VERSION ""

NS_ :

BS_:

BU_: BMS ECC EVBUS_Virtual_ECU GW OBC VCU

BO_ 1328 ICC_0x530: 8 GW
 SG_ ICC_DrvrTSet : 7|8@0+ (0.5,0) [0|127.5] "Degree Celsius"  ECC
 SG_ ICC_PassTSet : 15|8@0+ (0.5,0) [0|127.5] "Degree Celsius"  ECC
 SG_ ICC_VSPVoiceTypSwt : 17|1@0+ (1,0) [0|1] ""  EVBUS_Virtual_ECU
 SG_ ICC_ECCAUTOReq : 19|1@0+ (1,0) [0|1] ""  ECC
 SG_ ICC_DrvrSYNCReq : 20|1@0+ (1,0) [0|1] ""  ECC
 SG_ ICC_ACSwtReq : 21|1@0+ (1,0) [0|1] ""  ECC
 SG_ ICC_AirVolSet : 27|4@0+ (1,0) [0|15] ""  ECC
 SG_ ICC_ECCIntExtCircReq : 28|1@0+ (1,0) [0|1] ""  ECC
 SG_ ICC_AirClnSwtReq : 29|1@0+ (1,0) [0|1] ""  ECC
 SG_ ICC_MaxFrntDefrstSet : 30|1@0+ (1,0) [0|1] ""  ECC
 SG_ ICC_VSPCtrlCmd : 31|1@0+ (1,0) [0|1] ""  EVBUS_Virtual_ECU
 SG_ ICC_NavCtryCod : 39|8@0+ (1,0) [0|255] ""  EVBUS_Virtual_ECU
 SG_ ICC_NavRoadTyp : 43|4@0+ (1,0) [0|15] ""  EVBUS_Virtual_ECU
 SG_ ICC_NavSpdLimUnit : 45|2@0+ (1,0) [0|3] ""  EVBUS_Virtual_ECU
 SG_ ICC_NavSpdLimSts : 47|2@0+ (1,0) [0|3] ""  EVBUS_Virtual_ECU
 SG_ ICC_NavSpdLim : 53|6@0+ (1,0) [0|63] ""  EVBUS_Virtual_ECU
 SG_ ICC_BlowWinBtn : 55|1@0+ (1,0) [0|1] ""  ECC
 SG_ ICC_NavSpdLimExitDst : 63|8@0+ (10,0) [0|2550] "m"  EVBUS_Virtual_ECU

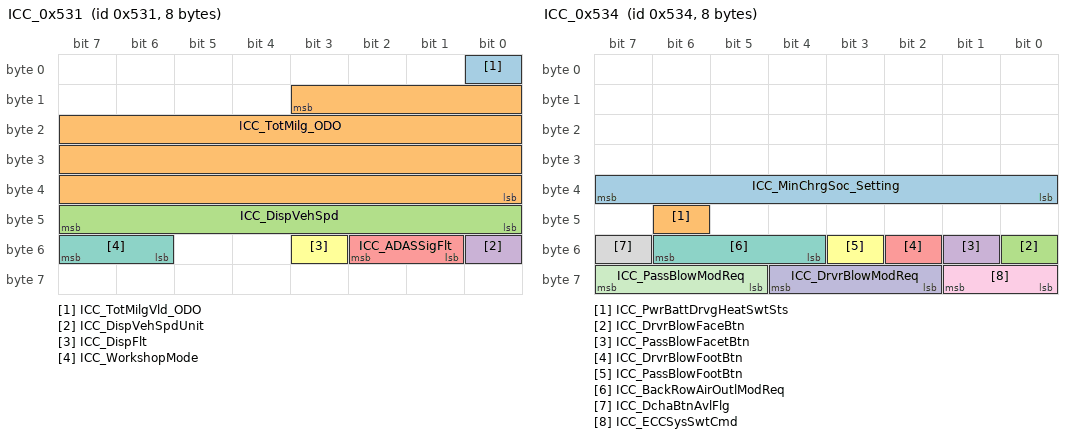
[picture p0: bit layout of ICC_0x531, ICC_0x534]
BO_ 1329 ICC_0x531: 8 GW
 SG_ ICC_TotMilgVld_ODO : 0|1@0+ (1,0) [0|1] ""  BMS,ECC,OBC,VCU
 SG_ ICC_TotMilg_ODO : 11|28@0+ (0.01,0) [0|2000000] "km"  BMS,ECC,OBC,VCU
 SG_ ICC_DispVehSpd : 47|8@0+ (1,0) [0|255] ""  ECC,VCU
 SG_ ICC_DispVehSpdUnit : 48|1@0+ (1,0) [0|1] ""  ECC,VCU
 SG_ ICC_ADASSigFlt : 50|2@0+ (1,0) [0|3] ""  ECC
 SG_ ICC_DispFlt : 51|1@0+ (1,0) [0|1] ""  ECC,VCU
 SG_ ICC_WorkshopMode : 55|2@0+ (1,0) [0|3] ""  ECC,VCU

BO_ 1332 ICC_0x534: 8 GW
 SG_ ICC_MinChrgSoc_Setting : 39|8@0+ (1,0) [0|255] "%"  VCU
 SG_ ICC_PwrBattDrvgHeatSwtSts : 46|1@0+ (1,0) [0|1] ""  ECC
 SG_ ICC_DrvrBlowFaceBtn : 48|1@0+ (1,0) [0|1] ""  ECC
 SG_ ICC_PassBlowFacetBtn : 49|1@0+ (1,0) [0|1] ""  ECC
 SG_ ICC_DrvrBlowFootBtn : 50|1@0+ (1,0) [0|1] ""  ECC
 SG_ ICC_PassBlowFootBtn : 51|1@0+ (1,0) [0|1] ""  ECC
 SG_ ICC_BackRowAirOutlModReq : 54|3@0+ (1,0) [0|7] ""  ECC
 SG_ ICC_DchaBtnAvlFlg : 55|1@0+ (1,0) [0|1] ""  VCU
 SG_ ICC_ECCSysSwtCmd : 57|2@0+ (1,0) [0|3] ""  ECC
 SG_ ICC_DrvrBlowModReq : 60|3@0+ (1,0) [0|7] ""  ECC
 SG_ ICC_PassBlowModReq : 63|3@0+ (1,0) [0|7] ""  ECC

BO_ 1360 OBC_0x550: 16 OBC
 SG_ OBC_0x550_CheckSum : 7|8@0+ (1,0) [0|255] ""  ECC,GW,VCU
 SG_ OBC_0x550_AliveCounter : 11|4@0+ (1,0) [0|14] ""  ECC,GW,VCU
 SG_ OBC_PDU_CrtSts : 12|1@0+ (1,0) [0|1] ""  GW,VCU
 SG_ OBC_Pwr : 15|3@0+ (1,0) [0|3] ""  GW,VCU
 SG_ OBC_OutpMaxPwr : 18|11@0+ (0.01,0) [0|20] "KW"  GW,VCU
 SG_ OBC_V2L_RdySts : 20|2@0+ (1,0) [0|3] ""  GW,VCU
 SG_ OBC_V2L_ActvStsFb : 22|2@0+ (1,0) [0|3] ""  GW,VCU
 SG_ OBC_T : 47|8@0+ (1,-48) [-48|207] "Degree Celsius"  ECC,GW,VCU
 SG_ OBC_CrtSts : 50|3@0+ (1,0) [0|7] ""  ECC,GW,VCU
 SG_ OBC_DCNegRlyAdhFlt : 51|1@0+ (1,0) [0|1] ""  GW,VCU
 SG_ OBC_DCPosRlyAdhFlt : 52|1@0+ (1,0) [0|1] ""  GW,VCU
 SG_ OBC_OperMod : 55|3@0+ (1,0) [0|3] ""  GW,VCU
 SG_ OBC_PwrSplyHLVIntlkFlt : 56|1@0+ (1,0) [0|1] ""  GW,VCU
 SG_ OBC_ACSCIntlkSigChkCircFlt : 57|1@0+ (1,0) [0|1] ""  GW,VCU
 SG_ OBC_DCFCIntlkSigChkCircFlt : 58|1@0+ (1,0) [0|1] ""  GW,VCU
 SG_ OBC_PTCIntlkSigChkCircFlt : 59|1@0+ (1,0) [0|1] ""  GW,VCU
 SG_ OBC_PwrBattIntlkSigChkCircFlt : 60|1@0+ (1,0) [0|1] ""  GW,VCU
 SG_ OBC_EASIntlkSigChkCircFlt : 61|1@0+ (1,0) [0|1] ""  GW,VCU
 SG_ OBC_OTARdy_Fb : 63|2@0+ (1,0) [0|3] ""  GW
 SG_ OBC_550_SSecOC_Fresh_Byte0 : 71|8@0+ (1,0) [0|255] ""  GW,VCU
 SG_ OBC_550_SSecOC_MAC_Byte0 : 79|8@0+ (1,0) [0|255] ""  GW,VCU
 SG_ OBC_550_SSecOC_MAC_Byte1 : 87|8@0+ (1,0) [0|255] ""  GW,VCU
 SG_ OBC_550_SSecOC_MAC_Byte2 : 95|8@0+ (1,0) [0|255] ""  GW,VCU

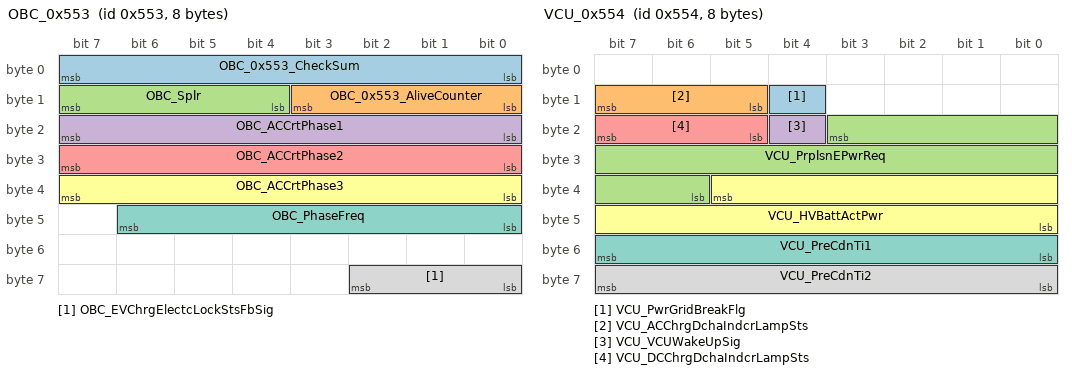
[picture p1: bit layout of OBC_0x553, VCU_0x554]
BO_ 1363 OBC_0x553: 8 OBC
 SG_ OBC_0x553_CheckSum : 7|8@0+ (1,0) [0|255] ""  GW,VCU
 SG_ OBC_0x553_AliveCounter : 11|4@0+ (1,0) [0|14] ""  GW,VCU
 SG_ OBC_Splr : 15|4@0+ (1,0) [0|15] ""  GW
 SG_ OBC_ACCrtPhase1 : 23|8@0+ (1,0) [0|255] "A"  GW,VCU
 SG_ OBC_ACCrtPhase2 : 31|8@0+ (1,0) [0|255] "A"  GW,VCU
 SG_ OBC_ACCrtPhase3 : 39|8@0+ (1,0) [0|255] "A"  GW,VCU
 SG_ OBC_PhaseFreq : 46|7@0+ (1,0) [0|63] "Hz"  GW,VCU
 SG_ OBC_EVChrgElectcLockStsFbSig : 58|3@0+ (1,0) [0|7] ""  GW,VCU

BO_ 1364 VCU_0x554: 8 VCU
 SG_ VCU_PwrGridBreakFlg : 12|1@0+ (1,0) [0|1] ""  GW
 SG_ VCU_ACChrgDchaIndcrLampSts : 15|3@0+ (1,0) [0|7] ""  GW
 SG_ VCU_PrplsnEPwrReq : 19|14@0+ (0.1,-600) [-600|600] "KW"  GW
 SG_ VCU_VCUWakeUpSig : 20|1@0+ (1,0) [0|1] ""  GW
 SG_ VCU_DCChrgDchaIndcrLampSts : 23|3@0+ (1,0) [0|7] ""  GW
 SG_ VCU_HVBattActPwr : 37|14@0+ (0.1,-600) [-600|600] "KW"  GW
 SG_ VCU_PreCdnTi1 : 55|8@0+ (1,0) [0|255] "min"  GW
 SG_ VCU_PreCdnTi2 : 63|8@0+ (1,0) [0|255] "min"  GW

BO_ 1365 VCU_0x555: 8 VCU
 SG_ VCU_DCChrgElectcLockDrvFlt : 1|2@0+ (1,0) [0|3] ""  GW
 SG_ VCU_ACDCChrgIndcrLamp12VFlt : 4|3@0+ (1,0) [0|7] ""  GW
 SG_ VCU_ComChkFlt_VCU : 5|1@0+ (1,0) [0|1] ""  GW
 SG_ VCU_ComChkFlt_BMS : 6|1@0+ (1,0) [0|1] ""  GW
 SG_ VCU_ComLostFlt_ICC : 7|1@0+ (1,0) [0|1] ""  GW
 SG_ VCU_ComLostFlt_PEPS : 9|1@0+ (1,0) [0|1] ""  GW
 SG_ VCU_ACChrgNTC1AndNTC2TFlt : 10|1@0+ (1,0) [0|1] ""  GW
 SG_ VCU_ComChkFlt_ESP : 11|1@0+ (1,0) [0|1] ""  GW
 SG_ VCU_ComLostFlt_OBC : 12|1@0+ (1,0) [0|1] ""  GW
 SG_ VCU_CrtSts : 15|3@0+ (1,0) [0|7] ""  GW
 SG_ VCU_ACChrgTAlrmFlt : 17|2@0+ (1,0) [0|3] ""  GW
 SG_ VCU_DCChrgNTC1AndNTC2TFlt : 19|1@0+ (1,0) [0|1] ""  GW
 SG_ VCU_KL30OperFlt : 20|1@0+ (1,0) [0|1] ""  GW
 SG_ VCU_ACChrgElectcLockDrvFlt : 23|2@0+ (1,0) [0|3] ""  GW
 SG_ VCU_ComLostFlt_VCU : 24|1@0+ (1,0) [0|1] ""  GW
 SG_ VCU_ACChrgDchaCCSigFlt : 27|2@0+ (1,0) [0|3] ""  GW
 SG_ VCU_ACChrgElectcUnlockFailFlt : 28|1@0+ (1,0) [0|1] ""  GW
 SG_ VCU_ACChrgElectcLockFailFlt : 29|1@0+ (1,0) [0|1] ""  GW
 SG_ VCU_DCChrgTAlrmFlt : 31|2@0+ (1,0) [0|3] ""  GW
 SG_ VCU_ChrgCPSigFlt : 33|2@0+ (1,0) [0|3] ""  GW
 SG_ VCU_DCChrgNTC1InpFlt : 35|2@0+ (1,0) [0|3] ""  GW
 SG_ VCU_DCChrgNTC2InpFlt : 37|2@0+ (1,0) [0|3] ""  GW
 SG_ VCU_ACChrgNTC1InpFlt : 39|2@0+ (1,0) [0|3] ""  GW
 SG_ VCU_ACChrgNTC2InpFlt : 41|2@0+ (1,0) [0|3] ""  GW
 SG_ VCU_DchgCPSigFlt : 44|3@0+ (1,0) [0|7] ""  GW
 SG_ VCU_CC2SigFlt : 47|3@0+ (1,0) [0|7] ""  GW
 SG_ VCU_CC2Volt : 55|8@0+ (0.1,0) [0|25.5] "V"  GW
 SG_ VCU_ACChrgIndcrLampDrvFlt : 58|3@0+ (1,0) [0|7] ""  GW
 SG_ VCU_DCChrgIndcrLampDrvFlt : 61|3@0+ (1,0) [0|7] ""  GW
 SG_ VCU_DCChrgASigFlt : 63|2@0+ (1,0) [0|3] ""  GW

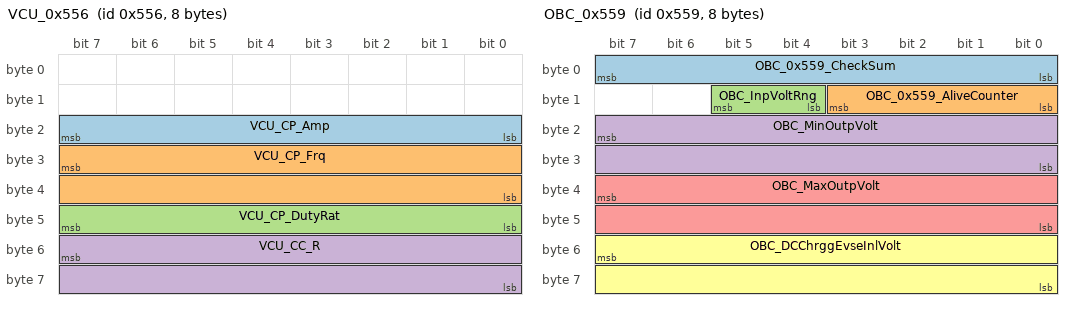
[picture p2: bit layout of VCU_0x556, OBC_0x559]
BO_ 1366 VCU_0x556: 8 VCU
 SG_ VCU_CP_Amp : 23|8@0+ (0.1,0) [0|25.5] "V"  GW
 SG_ VCU_CP_Frq : 31|16@0+ (1,0) [0|2000] "Hz"  GW
 SG_ VCU_CP_DutyRat : 47|8@0+ (1,0) [0|100] "%"  GW
 SG_ VCU_CC_R : 55|16@0+ (1,0) [0|4095] "Ohm"  GW

BO_ 1369 OBC_0x559: 8 OBC
 SG_ OBC_0x559_CheckSum : 7|8@0+ (1,0) [0|255] ""  GW,VCU
 SG_ OBC_0x559_AliveCounter : 11|4@0+ (1,0) [0|14] ""  GW,VCU
 SG_ OBC_InpVoltRng : 13|2@0+ (1,0) [0|3] ""  GW
 SG_ OBC_MinOutpVolt : 23|16@0+ (0.02,0) [0|1310.7] "V"  GW
 SG_ OBC_MaxOutpVolt : 39|16@0+ (0.02,0) [0|1310.7] "V"  GW
 SG_ OBC_DCChrggEvseInlVolt : 55|16@0+ (0.02,0) [0|1310.7] "V"  GW,VCU

BO_ 1370 OBC_0x55A: 8 OBC
 SG_ OBC_0x55A_CheckSum : 7|8@0+ (1,0) [0|255] ""  ECC,GW,VCU
 SG_ OBC_0x55A_AliveCounter : 11|4@0+ (1,0) [0|14] ""  ECC,GW,VCU
 SG_ OBC_HVDCOutpOverCrtSwFlt : 16|1@0+ (1,0) [0|1] ""  GW,VCU
 SG_ OBC_HVDCOutpOverCrtHwFlt : 17|1@0+ (1,0) [0|1] ""  GW,VCU
 SG_ OBC_ComLostFlt_BMS : 18|1@0+ (1,0) [0|1] ""  GW,VCU
 SG_ OBC_ACVoltOverVoltFlt : 19|1@0+ (1,0) [0|1] ""  GW,VCU
 SG_ OBC_ACVoltUnderVoltFlt : 20|1@0+ (1,0) [0|1] ""  GW,VCU
 SG_ OBC_HVDCOutpOverVoltHwFlt : 21|1@0+ (1,0) [0|1] ""  GW,VCU
 SG_ OBC_HVDCOutpUnderVoltFlt : 22|1@0+ (1,0) [0|1] ""  GW,VCU
 SG_ OBC_HVDCOutpOverVoltSwFlt : 26|1@0+ (1,0) [0|1] ""  GW,VCU
 SG_ OBC_InpCrtOverCrtHwSwFlt : 27|1@0+ (1,0) [0|1] ""  GW,VCU
 SG_ OBC_OverTTurnDwnPwrFlt : 29|1@0+ (1,0) [0|1] ""  ECC,GW,VCU
 SG_ OBC_OverTShutDwnFlt : 30|1@0+ (1,0) [0|1] ""  ECC,GW,VCU
 SG_ OBC_ExtFlt : 33|1@0+ (1,0) [0|1] ""  GW,VCU
 SG_ OBC_IntFlt : 34|1@0+ (1,0) [0|1] ""  GW,VCU
 SG_ OBC_ComLostFlt_VCU : 36|1@0+ (1,0) [0|1] ""  GW,VCU
 SG_ OBC_ComLostFlt_CCU : 37|1@0+ (1,0) [0|1] ""  GW,VCU
 SG_ OBC_12VPwrSplyVoltUnder : 38|1@0+ (1,0) [0|1] ""  GW,VCU
 SG_ OBC_12VPwrSplyVoltOver : 39|1@0+ (1,0) [0|1] ""  GW,VCU

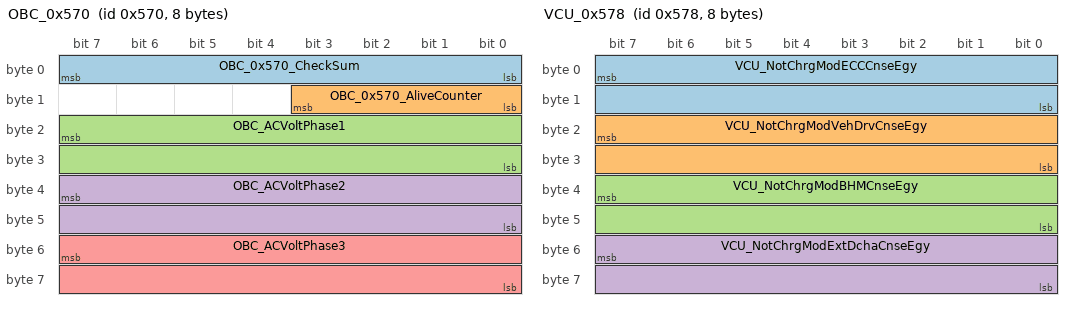
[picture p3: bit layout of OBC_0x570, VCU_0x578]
BO_ 1392 OBC_0x570: 8 OBC
 SG_ OBC_0x570_CheckSum : 7|8@0+ (1,0) [0|255] ""  GW,VCU
 SG_ OBC_0x570_AliveCounter : 11|4@0+ (1,0) [0|14] ""  GW,VCU
 SG_ OBC_ACVoltPhase1 : 23|16@0+ (0.02,0) [0|1310.7] "V"  GW,VCU
 SG_ OBC_ACVoltPhase2 : 39|16@0+ (0.02,0) [0|1310.7] "V"  GW,VCU
 SG_ OBC_ACVoltPhase3 : 55|16@0+ (0.02,0) [0|1310.7] "V"  GW,VCU

BO_ 1400 VCU_0x578: 8 VCU
 SG_ VCU_NotChrgModECCCnseEgy : 7|16@0+ (0.1,0) [0|6553.5] "kWh"  GW
 SG_ VCU_NotChrgModVehDrvCnseEgy : 23|16@0+ (0.1,0) [0|6553.5] "kWh"  GW
 SG_ VCU_NotChrgModBHMCnseEgy : 39|16@0+ (0.1,0) [0|6553.5] "kWh"  GW
 SG_ VCU_NotChrgModExtDchaCnseEgy : 55|16@0+ (0.1,0) [0|6553.5] "kWh"  GW

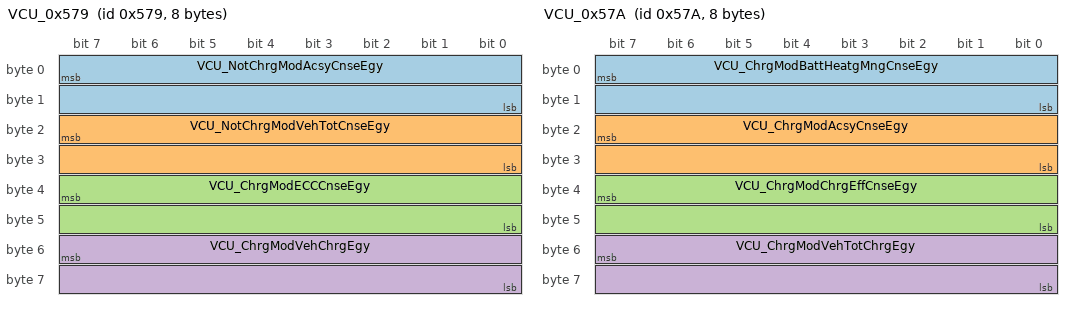
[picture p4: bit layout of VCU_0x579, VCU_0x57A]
BO_ 1401 VCU_0x579: 8 VCU
 SG_ VCU_NotChrgModAcsyCnseEgy : 7|16@0+ (0.1,0) [0|6553.5] "kWh"  GW
 SG_ VCU_NotChrgModVehTotCnseEgy : 23|16@0+ (0.1,0) [0|6553.5] "kWh"  GW
 SG_ VCU_ChrgModECCCnseEgy : 39|16@0+ (0.1,0) [0|6553.5] "kWh"  GW
 SG_ VCU_ChrgModVehChrgEgy : 55|16@0+ (0.1,0) [0|6553.5] "kWh"  GW

BO_ 1402 VCU_0x57A: 8 VCU
 SG_ VCU_ChrgModBattHeatgMngCnseEgy : 7|16@0+ (0.1,0) [0|6553.5] "kWh"  GW
 SG_ VCU_ChrgModAcsyCnseEgy : 23|16@0+ (0.1,0) [0|6553.5] "kWh"  GW
 SG_ VCU_ChrgModChrgEffCnseEgy : 39|16@0+ (0.1,0) [0|6553.5] "kWh"  GW
 SG_ VCU_ChrgModVehTotChrgEgy : 55|16@0+ (0.1,0) [0|6553.5] "kWh"  GW

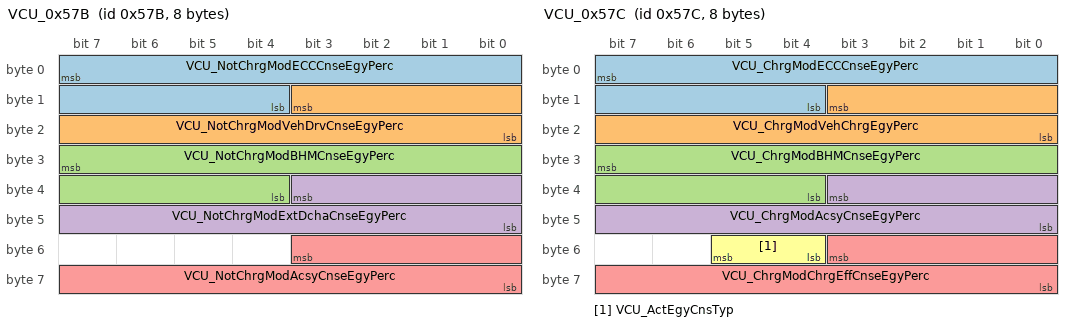
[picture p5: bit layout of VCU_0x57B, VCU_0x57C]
BO_ 1403 VCU_0x57B: 8 VCU
 SG_ VCU_NotChrgModECCCnseEgyPerc : 7|12@0+ (0.1,0) [0|100] "%"  GW
 SG_ VCU_NotChrgModVehDrvCnseEgyPerc : 11|12@0+ (0.1,0) [0|100] "%"  GW
 SG_ VCU_NotChrgModBHMCnseEgyPerc : 31|12@0+ (0.1,0) [0|100] "%"  GW
 SG_ VCU_NotChrgModExtDchaCnseEgyPerc : 35|12@0+ (0.1,0) [0|100] "%"  GW
 SG_ VCU_NotChrgModAcsyCnseEgyPerc : 51|12@0+ (0.1,0) [0|100] "%"  GW

BO_ 1404 VCU_0x57C: 8 VCU
 SG_ VCU_ChrgModECCCnseEgyPerc : 7|12@0+ (0.1,0) [0|100] "%"  GW
 SG_ VCU_ChrgModVehChrgEgyPerc : 11|12@0+ (0.1,0) [0|100] "%"  GW
 SG_ VCU_ChrgModBHMCnseEgyPerc : 31|12@0+ (0.1,0) [0|100] "%"  GW
 SG_ VCU_ChrgModAcsyCnseEgyPerc : 35|12@0+ (0.1,0) [0|100] "%"  GW
 SG_ VCU_ChrgModChrgEffCnseEgyPerc : 51|12@0+ (0.1,0) [0|100] "%"  GW
 SG_ VCU_ActEgyCnsTyp : 53|2@0+ (1,0) [0|3] ""  GW

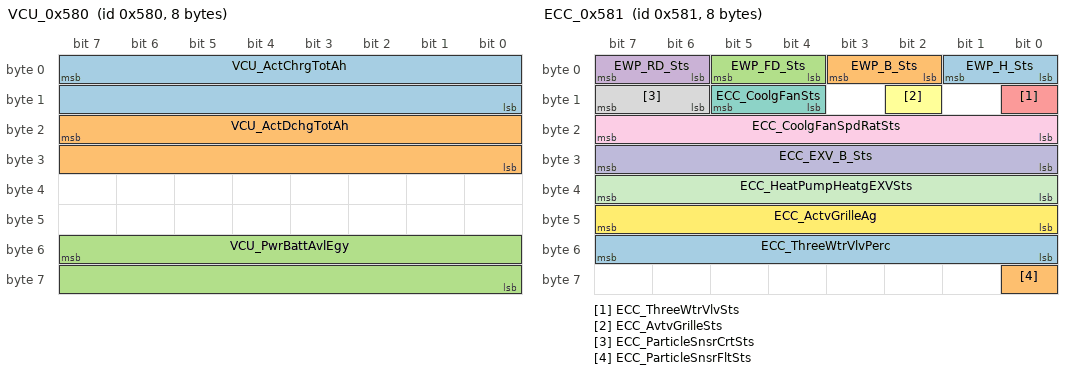
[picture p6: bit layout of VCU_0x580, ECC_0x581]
BO_ 1408 VCU_0x580: 8 VCU
 SG_ VCU_ActChrgTotAh : 7|16@0+ (0.01,0) [0|655.35] "Ah"  GW
 SG_ VCU_ActDchgTotAh : 23|16@0+ (0.01,0) [0|655.35] "Ah"  GW
 SG_ VCU_PwrBattAvlEgy : 55|16@0+ (0.01,0) [0|655.35] "kWh"  GW

BO_ 1409 ECC_0x581: 8 ECC
 SG_ EWP_H_Sts : 1|2@0+ (1,0) [0|3] ""  GW,VCU
 SG_ EWP_B_Sts : 3|2@0+ (1,0) [0|3] ""  GW,VCU
 SG_ EWP_FD_Sts : 5|2@0+ (1,0) [0|3] ""  GW,VCU
 SG_ EWP_RD_Sts : 7|2@0+ (1,0) [0|3] ""  GW,VCU
 SG_ ECC_ThreeWtrVlvSts : 8|1@0+ (1,0) [0|1] ""  GW,VCU
 SG_ ECC_AvtvGrilleSts : 10|1@0+ (1,0) [0|1] ""  GW,VCU
 SG_ ECC_CoolgFanSts : 13|2@0+ (1,0) [0|3] ""  GW,VCU
 SG_ ECC_ParticleSnsrCrtSts : 15|2@0+ (1,0) [0|3] ""  GW,VCU
 SG_ ECC_CoolgFanSpdRatSts : 23|8@0+ (1,0) [0|100] "%"  GW,VCU
 SG_ ECC_EXV_B_Sts : 31|8@0+ (1,0) [0|100] "%"  GW,VCU
 SG_ ECC_HeatPumpHeatgEXVSts : 39|8@0+ (1,0) [0|100] "%"  GW,VCU
 SG_ ECC_ActvGrilleAg : 47|8@0+ (1,0) [0|100] "%"  GW,VCU
 SG_ ECC_ThreeWtrVlvPerc : 55|8@0+ (1,0) [0|100] "%"  GW,VCU
 SG_ ECC_ParticleSnsrFltSts : 56|1@0+ (1,0) [0|1] ""  GW,VCU

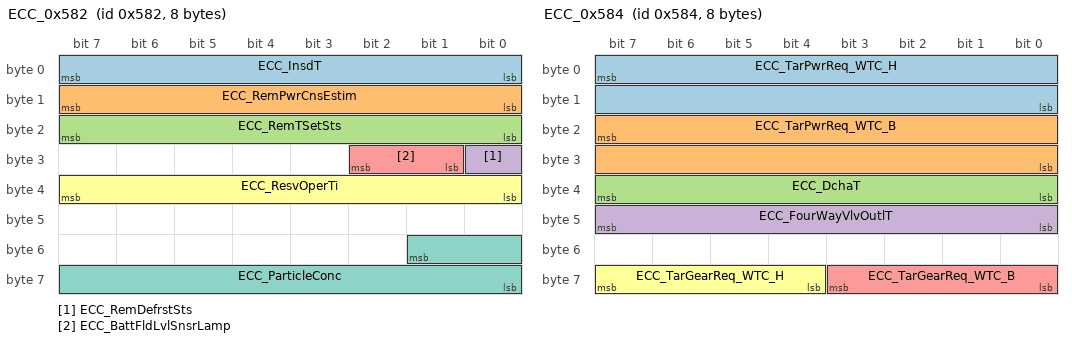
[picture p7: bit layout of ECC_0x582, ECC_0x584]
BO_ 1410 ECC_0x582: 8 ECC
 SG_ ECC_InsdT : 7|8@0+ (0.5,-48) [-48|79.5] "Degree Celsius"  GW,VCU
 SG_ ECC_RemPwrCnsEstim : 15|8@0+ (0.05,0) [0|12.75] "kWh"  GW
 SG_ ECC_RemTSetSts : 23|8@0+ (1,0) [0|255] ""  GW,VCU
 SG_ ECC_RemDefrstSts : 24|1@0+ (1,0) [0|1] ""  GW,VCU
 SG_ ECC_BattFldLvlSnsrLamp : 26|2@0+ (1,0) [0|3] ""  GW
 SG_ ECC_ResvOperTi : 39|8@0+ (1,0) [0|255] "min"  GW
 SG_ ECC_ParticleConc : 49|10@0+ (1,0) [0|999] "ug/m3"  GW

BO_ 1412 ECC_0x584: 8 ECC
 SG_ ECC_TarPwrReq_WTC_H : 7|16@0+ (1,0) [0|10000] "W"  GW,VCU
 SG_ ECC_TarPwrReq_WTC_B : 23|16@0+ (1,0) [0|10000] "W"  GW,VCU
 SG_ ECC_DchaT : 39|8@0+ (1,-48) [-48|207] "Degree Celsius"  GW,VCU
 SG_ ECC_FourWayVlvOutlT : 47|8@0+ (1,-48) [-48|207] "Degree Celsius"  GW,VCU
 SG_ ECC_TarGearReq_WTC_B : 59|4@0+ (1,0) [0|15] ""  GW,VCU
 SG_ ECC_TarGearReq_WTC_H : 63|4@0+ (1,0) [0|15] ""  GW,VCU

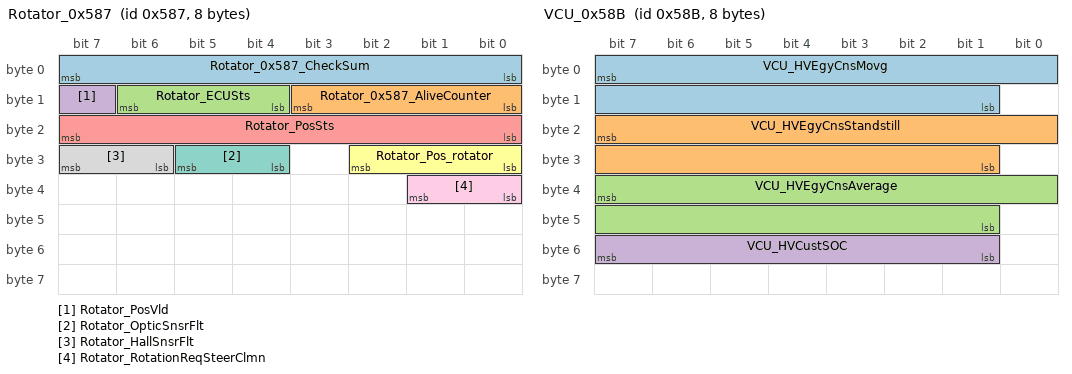
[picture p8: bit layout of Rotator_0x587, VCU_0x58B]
BO_ 1415 Rotator_0x587: 8 GW
 SG_ Rotator_0x587_CheckSum : 7|8@0+ (1,0) [0|255] ""  VCU
 SG_ Rotator_0x587_AliveCounter : 11|4@0+ (1,0) [0|14] ""  VCU
 SG_ Rotator_ECUSts : 14|3@0+ (1,0) [0|7] ""  VCU
 SG_ Rotator_PosVld : 15|1@0+ (1,0) [0|1] ""  VCU
 SG_ Rotator_PosSts : 23|8@0+ (1.8,0) [0|90] ""  VCU
 SG_ Rotator_Pos_rotator : 26|3@0+ (1,0) [0|7] ""  VCU
 SG_ Rotator_OpticSnsrFlt : 29|2@0+ (1,0) [0|3] ""  EVBUS_Virtual_ECU
 SG_ Rotator_HallSnsrFlt : 31|2@0+ (1,0) [0|3] ""  EVBUS_Virtual_ECU
 SG_ Rotator_RotationReqSteerClmn : 33|2@0+ (1,0) [0|1] ""  EVBUS_Virtual_ECU

BO_ 1419 VCU_0x58B: 8 VCU
 SG_ VCU_HVEgyCnsMovg : 7|15@0+ (1,-9999) [-9999|9999] "Wh/km"  GW
 SG_ VCU_HVEgyCnsStandstill : 23|15@0+ (1,-2000) [-2000|20000] "Wh"  GW
 SG_ VCU_HVEgyCnsAverage : 39|15@0+ (1,-9999) [-9999|9999] "Wh/km"  GW
 SG_ VCU_HVCustSOC : 55|7@0+ (1,0) [0|100] "%"  GW

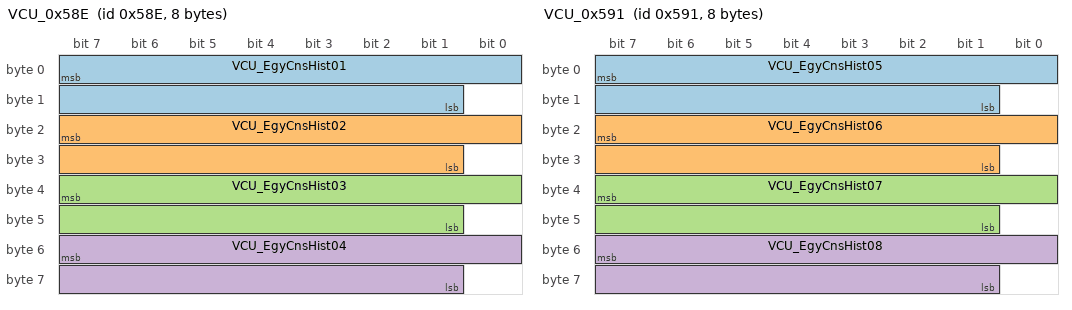
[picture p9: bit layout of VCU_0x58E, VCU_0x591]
BO_ 1422 VCU_0x58E: 8 VCU
 SG_ VCU_EgyCnsHist01 : 7|15@0+ (1,-9999) [-9999|9999] "Wh/km"  GW
 SG_ VCU_EgyCnsHist02 : 23|15@0+ (1,-9999) [-9999|9999] "Wh/km"  GW
 SG_ VCU_EgyCnsHist03 : 39|15@0+ (1,-9999) [-9999|9999] "Wh/km"  GW
 SG_ VCU_EgyCnsHist04 : 55|15@0+ (1,-9999) [-9999|9999] "Wh/km"  GW

BO_ 1425 VCU_0x591: 8 VCU
 SG_ VCU_EgyCnsHist05 : 7|15@0+ (1,-9999) [-9999|9999] "Wh/km"  GW
 SG_ VCU_EgyCnsHist06 : 23|15@0+ (1,-9999) [-9999|9999] "Wh/km"  GW
 SG_ VCU_EgyCnsHist07 : 39|15@0+ (1,-9999) [-9999|9999] "Wh/km"  GW
 SG_ VCU_EgyCnsHist08 : 55|15@0+ (1,-9999) [-9999|9999] "Wh/km"  GW

BO_ 1429 BMS_ChargingTime: 8 BMS
 SG_ BMS_RmChrgTi_FullChrg : 7|16@0+ (1,0) [0|65535] "min"  GW,VCU
 SG_ BMS_RmChrgTi_TrgtSoC : 23|16@0+ (1,0) [0|65535] "min"  GW,VCU

BO_ 1432 VCU_0x598: 8 VCU
 SG_ VCU_EgyCnsHist09 : 7|15@0+ (1,-9999) [-9999|9999] "Wh/km"  GW
 SG_ VCU_EgyCnsHist10 : 23|15@0+ (1,-9999) [-9999|9999] "Wh/km"  GW

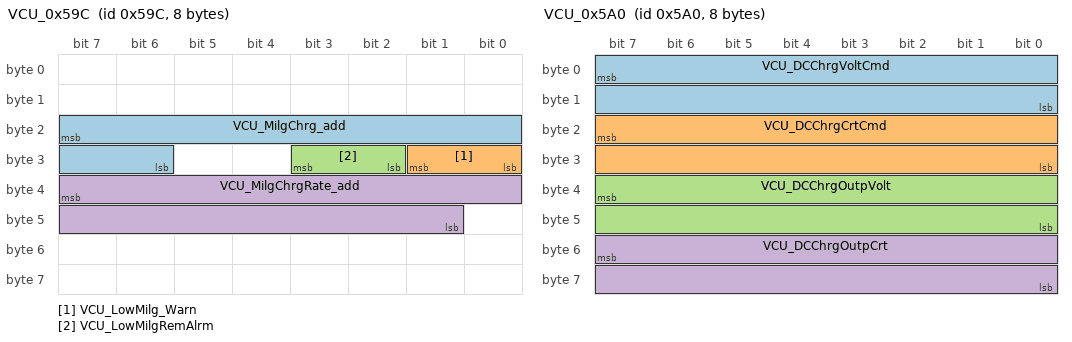
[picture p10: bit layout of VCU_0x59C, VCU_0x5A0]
BO_ 1436 VCU_0x59C: 8 VCU
 SG_ VCU_MilgChrg_add : 23|10@0+ (1,0) [0|1000] "km"  GW
 SG_ VCU_LowMilg_Warn : 25|2@0+ (1,0) [0|3] ""  GW
 SG_ VCU_LowMilgRemAlrm : 27|2@0+ (1,0) [0|3] ""  GW
 SG_ VCU_MilgChrgRate_add : 39|15@0+ (0.1,0) [0|2000] "km/h"  GW

BO_ 1440 VCU_0x5A0: 8 VCU
 SG_ VCU_DCChrgVoltCmd : 7|16@0+ (0.02,0) [0|1310.7] "V"  GW
 SG_ VCU_DCChrgCrtCmd : 23|16@0+ (0.02,0) [0|1310.7] "A"  GW
 SG_ VCU_DCChrgOutpVolt : 39|16@0+ (0.1,0) [0|3000] "V"  GW
 SG_ VCU_DCChrgOutpCrt : 55|16@0+ (0.02,0) [0|1310.7] "A"  GW

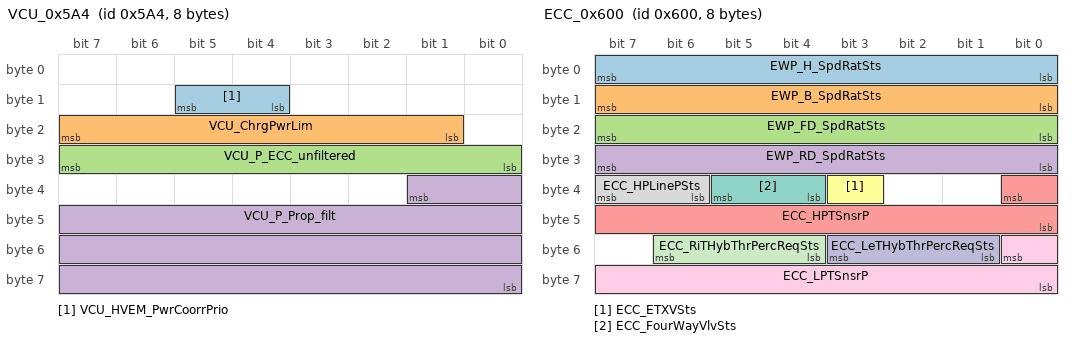
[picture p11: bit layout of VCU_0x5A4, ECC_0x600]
BO_ 1444 VCU_0x5A4: 8 VCU
 SG_ VCU_HVEM_PwrCoorrPrio : 13|2@0+ (1,0) [0|3] ""  GW
 SG_ VCU_ChrgPwrLim : 23|7@0+ (1,0) [0|100] "%"  GW
 SG_ VCU_P_ECC_unfiltered : 31|8@0+ (0.1,0) [0|15] "KW"  ECC,GW
 SG_ VCU_P_Prop_filt : 33|26@0+ (0.1,-450) [-450|450] "KW"  GW

BO_ 1476 TBOX_0x5C4: 16 GW
 SG_ TBOX_OTA_ownCondchk : 1|2@0+ (1,0) [0|3] ""  BMS,ECC,OBC,VCU
 SG_ TBOX_TerminalRemWakeupSig : 2|1@0+ (1,0) [0|1] ""  VCU
 SG_ TBOX_RemSCModReq : 4|2@0+ (1,0) [0|3] ""  VCU
 SG_ TBOX_RemPwrBattOpenHeatgReq : 6|2@0+ (1,0) [0|3] ""  ECC,VCU
 SG_ TBOX_RemPwrBattResvHeatgReq : 7|1@0+ (1,0) [0|1] ""  ECC,VCU
 SG_ TBOX_RemInsdInfoDispEna : 12|1@0+ (1,0) [0|1] ""  EVBUS_Virtual_ECU
 SG_ TBOX_RemECCDefrstModReq : 14|2@0+ (1,0) [0|3] ""  ECC,VCU
 SG_ TBOX_RemECCResvDefrstReq : 15|1@0+ (1,0) [0|1] ""  ECC
 SG_ TBOX_RemECCSetT : 31|8@0+ (0.5,0) [0|127.5] "Degree Celsius"  ECC,VCU
 SG_ TBOX_RemResvECCSetT : 39|8@0+ (0.5,0) [0|127.5] "Degree Celsius"  ECC
 SG_ TBOX_RemSOCMax : 47|8@0+ (1,0) [0|100] ""  ECC,VCU
 SG_ TBOX_4GSigIND : 49|2@0+ (1,0) [0|3] ""  EVBUS_Virtual_ECU
 SG_ TBOX_Conn_Typ : 52|3@0+ (1,0) [0|7] ""  EVBUS_Virtual_ECU
 SG_ TBOX_TSPNotConn : 53|1@0+ (1,0) [0|1] ""  EVBUS_Virtual_ECU
 SG_ TBOX_EHUNotCONN : 54|1@0+ (1,0) [0|1] ""  EVBUS_Virtual_ECU
 SG_ TBOX_WIFIError : 55|1@0+ (1,0) [0|1] ""  EVBUS_Virtual_ECU
 SG_ TBOX_InnerBattError : 56|1@0+ (1,0) [0|1] ""  EVBUS_Virtual_ECU
 SG_ TBOX_VoltLow : 57|1@0+ (1,0) [0|1] ""  EVBUS_Virtual_ECU
 SG_ TBOX_VoltHigh : 58|1@0+ (1,0) [0|1] ""  EVBUS_Virtual_ECU
 SG_ TBOX_4GLoss : 59|1@0+ (1,0) [0|1] ""  EVBUS_Virtual_ECU
 SG_ TBOX_RemSWH_Req : 61|2@0+ (1,0) [0|3] ""  EVBUS_Virtual_ECU
 SG_ TBOX_OTAInhbReq : 63|2@0+ (1,0) [0|3] ""  VCU
 SG_ TBOX_5C4_SSecOC_Fresh_Byte0 : 71|8@0+ (1,0) [0|255] ""  ECC,VCU
 SG_ TBOX_5C4_SSecOC_MAC_Byte0 : 79|8@0+ (1,0) [0|255] ""  ECC,VCU
 SG_ TBOX_5C4_SSecOC_MAC_Byte1 : 87|8@0+ (1,0) [0|255] ""  ECC,VCU
 SG_ TBOX_5C4_SSecOC_MAC_Byte2 : 95|8@0+ (1,0) [0|255] ""  ECC,VCU

BO_ 1514 VCU_0x5EA: 8 VCU
 SG_ VCU_TripMilg : 23|16@0+ (0.1,0) [0|6550] "km"  GW
 SG_ VCU_TripAvgEgyConsmd : 39|10@0+ (1,0) [0|1023] "Wh/km"  GW

BO_ 1536 ECC_0x600: 8 ECC
 SG_ EWP_H_SpdRatSts : 7|8@0+ (1,0) [0|100] "%"  GW,VCU
 SG_ EWP_B_SpdRatSts : 15|8@0+ (1,0) [0|100] "%"  GW,VCU
 SG_ EWP_FD_SpdRatSts : 23|8@0+ (1,0) [0|100] "%"  GW,VCU
 SG_ EWP_RD_SpdRatSts : 31|8@0+ (1,0) [0|100] "%"  GW,VCU
 SG_ ECC_HPTSnsrP : 32|9@0+ (0.01,0) [0|5] "Mpa"  GW,VCU
 SG_ ECC_ETXVSts : 35|1@0+ (1,0) [0|1] ""  GW,VCU
 SG_ ECC_FourWayVlvSts : 37|2@0+ (1,0) [0|3] ""  GW,VCU
 SG_ ECC_HPLinePSts : 39|2@0+ (1,0) [0|3] ""  GW,VCU
 SG_ ECC_LPTSnsrP : 48|9@0+ (0.01,0) [0|5] "Mpa"  GW,VCU
 SG_ ECC_LeTHybThrPercReqSts : 51|3@0+ (1,0) [0|7] ""  GW,VCU
 SG_ ECC_RiTHybThrPercReqSts : 54|3@0+ (1,0) [0|7] ""  GW,VCU

BO_ 1552 ICC_0x610: 8 GW
 SG_ ICC_UsrSetChrgRmnMilg : 7|8@0+ (1,0) [0|255] ""  VCU
 SG_ ICC_EPedlSts : 9|2@0+ (1,0) [0|3] ""  VCU
 SG_ ICC_AccelMod : 11|2@0+ (1,0) [0|3] ""  VCU
 SG_ ICC_BoostMode : 13|2@0+ (1,0) [0|3] ""  VCU
 SG_ ICC_EgyCnseClrFlg : 15|2@0+ (1,0) [0|3] ""  VCU
 SG_ ICC_UsrSetDchaEndDrvgMilg : 17|10@0+ (1,0) [0|800] "km"  EVBUS_Virtual_ECU
 SG_ ICC_VehiMod : 21|4@0+ (1,0) [0|15] ""  EVBUS_Virtual_ECU
 SG_ ICC_EgyCnseStcClrFlg : 23|2@0+ (1,0) [0|3] ""  VCU
 SG_ ICC_PollingFctOpenSts : 33|2@0+ (1,0) [0|3] ""  EVBUS_Virtual_ECU
 SG_ ICC_KickFctOpenSts : 35|2@0+ (1,0) [0|3] ""  EVBUS_Virtual_ECU
 SG_ ICC_UsrSetChrgGunAntithft : 36|1@0+ (1,0) [0|1] ""  VCU
 SG_ ICC_ChrgInsulFctReq : 38|2@0+ (1,0) [0|3] ""  VCU
 SG_ ICC_StopChrgBtn : 39|1@0+ (1,0) [0|1] ""  VCU
 SG_ ICC_DrvModSig : 42|3@0+ (1,0) [0|7] ""  ECC,VCU
 SG_ ICC_SetACChrgLmtCrt : 49|2@0+ (1,0) [0|3] ""  VCU
 SG_ ICC_SetTrvlMod : 51|2@0+ (1,0) [0|3] ""  VCU
 SG_ ICC_RegenLvl : 54|2@0+ (1,0) [0|3] ""  VCU
 SG_ ICC_SetChrgEndSOC : 62|7@0+ (1,0) [0|100] "%"  VCU
 SG_ ICC_StartChrgBtn : 63|1@0+ (1,0) [0|1] ""  VCU

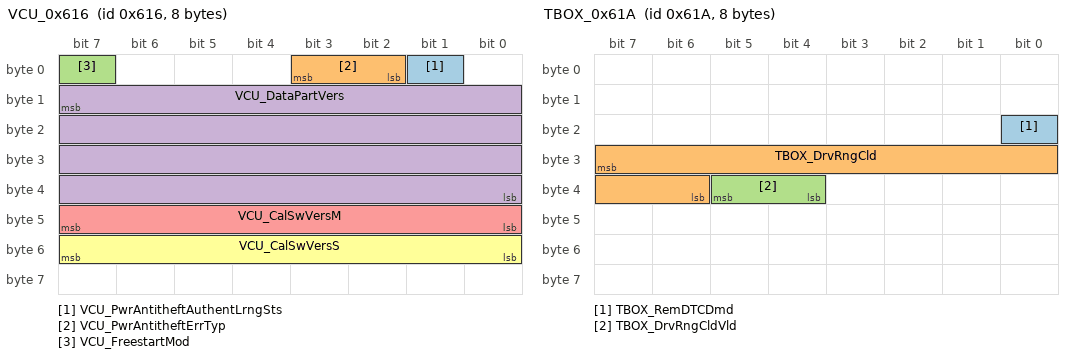
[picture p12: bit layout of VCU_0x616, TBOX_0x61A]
BO_ 1558 VCU_0x616: 8 VCU
 SG_ VCU_PwrAntitheftAuthentLrngSts : 1|1@0+ (1,0) [0|1] ""  GW
 SG_ VCU_PwrAntitheftErrTyp : 3|2@0+ (1,0) [0|3] ""  GW
 SG_ VCU_FreestartMod : 7|1@0+ (1,0) [0|1] ""  GW
 SG_ VCU_DataPartVers : 15|32@0+ (1,0) [0|4294967295] ""  GW
 SG_ VCU_CalSwVersM : 47|8@0+ (1,0) [0|255] ""  GW
 SG_ VCU_CalSwVersS : 55|8@0+ (1,0) [0|255] ""  GW

BO_ 1559 VCU_0x617: 8 VCU
 SG_ VCU_E2PROMAPICallFlt : 0|1@0+ (1,0) [0|1] ""  GW
 SG_ VCU_E2PROMReadFlt : 1|1@0+ (1,0) [0|1] ""  GW
 SG_ VCU_E2PROMWrFlt : 2|1@0+ (1,0) [0|1] ""  GW
 SG_ VCU_TMonFlt : 3|1@0+ (1,0) [0|1] ""  GW
 SG_ VCU_EVCANBusFlt : 4|1@0+ (1,0) [0|1] ""  GW
 SG_ VCU_CCANBusFlt : 5|1@0+ (1,0) [0|1] ""  GW
 SG_ VCU_BREAKCANBusFlt : 6|1@0+ (1,0) [0|1] ""  GW
 SG_ VCU_ATIC232ComFlt : 7|1@0+ (1,0) [0|1] ""  GW
 SG_ VCU_ATIC280ComFlt : 8|1@0+ (1,0) [0|1] ""  GW
 SG_ VCU_ATIC239LowSideOutpComFlt : 9|1@0+ (1,0) [0|1] ""  GW
 SG_ VCU_ATIC239VotSplyMngComFlt : 10|1@0+ (1,0) [0|1] ""  GW
 SG_ VCU_ATIC239UnderOverVotFlt : 11|1@0+ (1,0) [0|1] ""  GW
 SG_ VCU_ADCnvrFlt : 12|1@0+ (1,0) [0|1] ""  GW
 SG_ VCU_SftyFctMonrFlt : 13|1@0+ (1,0) [0|1] ""  GW
 SG_ VCU_SftyFctMonrMemFlt : 14|1@0+ (1,0) [0|1] ""  GW
 SG_ VCU_LVbattCtrlSigOpenFlt : 15|1@0+ (1,0) [0|1] ""  GW
 SG_ VCU_LVbattCtrlSigSTBFlt : 16|1@0+ (1,0) [0|1] ""  GW
 SG_ VCU_LVbattCtrlSigSTGFlt : 17|1@0+ (1,0) [0|1] ""  GW
 SG_ VCU_BMSWakeUpSigOpenFlt : 18|1@0+ (1,0) [0|1] ""  GW
 SG_ VCU_BMSWakeUpSigSTBFlt : 19|1@0+ (1,0) [0|1] ""  GW
 SG_ VCU_BMSWakeUpSigSTGFlt : 20|1@0+ (1,0) [0|1] ""  GW
 SG_ VCU_PDUWakeUpSigSTBFlt : 21|1@0+ (1,0) [0|1] ""  GW
 SG_ VCU_PDUWakeUpSigOpenFlt : 22|1@0+ (1,0) [0|1] ""  GW
 SG_ VCU_PDUWakeUpSigSTGFlt : 23|1@0+ (1,0) [0|1] ""  GW
 SG_ VCU_CCUCMUWakeUpSigOpenFlt : 24|1@0+ (1,0) [0|1] ""  GW
 SG_ VCU_CCUCMUWakeUpSigSTBFlt : 25|1@0+ (1,0) [0|1] ""  GW
 SG_ VCU_CCUCMUWakeUpSigSTGFlt : 26|1@0+ (1,0) [0|1] ""  GW
 SG_ VCU_MCUWakeUpSigOpenFlt : 27|1@0+ (1,0) [0|1] ""  GW
 SG_ VCU_MCUWakeUpSigSTBFlt : 28|1@0+ (1,0) [0|1] ""  GW
 SG_ VCU_MCUWakeUpSigSTGFlt : 29|1@0+ (1,0) [0|1] ""  GW
 SG_ VCU_ComLostFlt_CCU : 30|1@0+ (1,0) [0|1] ""  GW

BO_ 1562 TBOX_0x61A: 8 GW
 SG_ TBOX_RemDTCDmd : 16|1@0+ (1,0) [0|1] ""  VCU
 SG_ TBOX_DrvRngCld : 31|10@0+ (1,0) [0|1000] "km"  VCU
 SG_ TBOX_DrvRngCldVld : 37|2@0+ (1,0) [0|3] ""  VCU

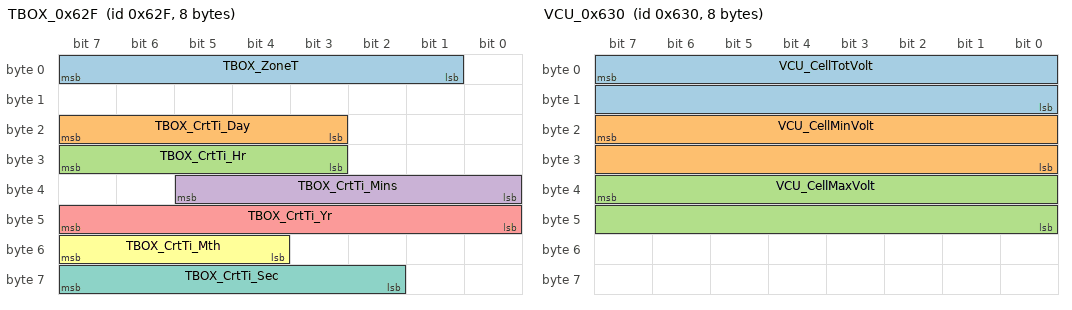
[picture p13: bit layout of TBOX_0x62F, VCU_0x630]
BO_ 1583 TBOX_0x62F: 8 GW
 SG_ TBOX_ZoneT : 7|7@0+ (15,-720) [-720|1185] "min"  ECC,EVBUS_Virtual_ECU
 SG_ TBOX_CrtTi_Day : 23|5@0+ (1,1) [1|31] "day"  BMS,ECC,OBC,VCU
 SG_ TBOX_CrtTi_Hr : 31|5@0+ (1,0) [0|23] "hour"  BMS,ECC,OBC,VCU
 SG_ TBOX_CrtTi_Mins : 37|6@0+ (1,0) [0|59] "mintue"  BMS,ECC,OBC,VCU
 SG_ TBOX_CrtTi_Yr : 47|8@0+ (1,2015) [2015|2270] "year"  BMS,ECC,OBC,VCU
 SG_ TBOX_CrtTi_Mth : 55|4@0+ (1,1) [1|12] "month"  BMS,ECC,OBC,VCU
 SG_ TBOX_CrtTi_Sec : 63|6@0+ (1,0) [0|59] "second"  BMS,ECC,OBC,VCU

BO_ 1584 VCU_0x630: 8 VCU
 SG_ VCU_CellTotVolt : 7|16@0+ (0.02,0) [0|1310.7] "V"  GW
 SG_ VCU_CellMinVolt : 23|16@0+ (0.0001,0) [0|6.5535] "V"  GW
 SG_ VCU_CellMaxVolt : 39|16@0+ (0.0001,0) [0|6.5535] "V"  GW

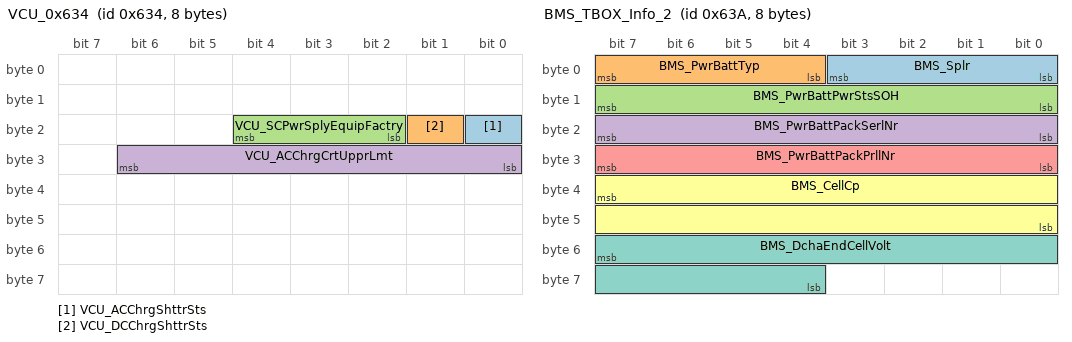
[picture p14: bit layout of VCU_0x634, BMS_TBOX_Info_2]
BO_ 1588 VCU_0x634: 8 VCU
 SG_ VCU_ACChrgShttrSts : 16|1@0+ (1,0) [0|1] ""  GW
 SG_ VCU_DCChrgShttrSts : 17|1@0+ (1,0) [0|1] ""  GW
 SG_ VCU_SCPwrSplyEquipFactry : 20|3@0+ (1,0) [0|7] ""  GW
 SG_ VCU_ACChrgCrtUpprLmt : 30|7@0+ (1,0) [0|100] ""  GW

BO_ 1594 BMS_TBOX_Info_2: 8 BMS
 SG_ BMS_Splr : 3|4@0+ (1,0) [0|15] ""  GW,VCU
 SG_ BMS_PwrBattTyp : 7|4@0+ (1,0) [0|15] ""  GW,VCU
 SG_ BMS_PwrBattPwrStsSOH : 15|8@0+ (0.01,0) [0|2.55] "KW"  GW
 SG_ BMS_PwrBattPackSerlNr : 23|8@0+ (1,0) [0|255] ""  GW,VCU
 SG_ BMS_PwrBattPackPrllNr : 31|8@0+ (1,0) [0|255] ""  GW,VCU
 SG_ BMS_CellCp : 39|16@0+ (0.1,0) [0|6553.5] "Ah"  GW,VCU
 SG_ BMS_DchaEndCellVolt : 55|12@0+ (0.01,0) [0|25.5] "V"  GW,VCU

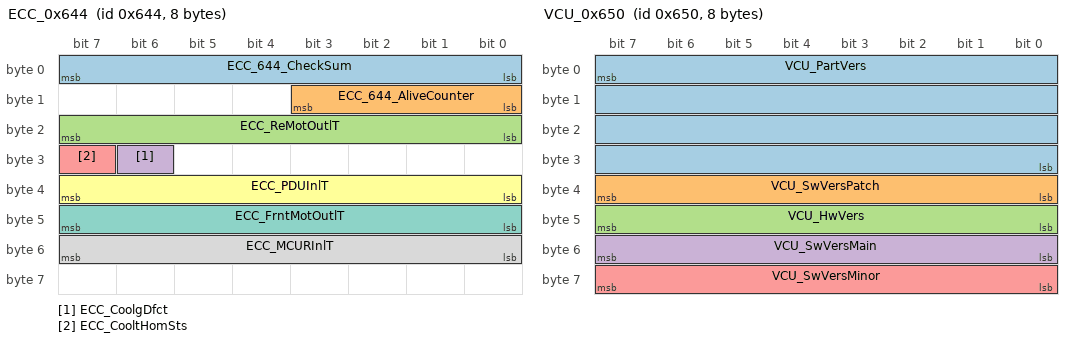
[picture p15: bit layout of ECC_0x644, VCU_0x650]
BO_ 1604 ECC_0x644: 8 ECC
 SG_ ECC_644_CheckSum : 7|8@0+ (1,0) [0|255] ""  GW,VCU
 SG_ ECC_644_AliveCounter : 11|4@0+ (1,0) [0|14] ""  GW,VCU
 SG_ ECC_ReMotOutlT : 23|8@0+ (1,-48) [-48|207] "Degree Celsius"  GW,VCU
 SG_ ECC_CoolgDfct : 30|1@0+ (1,0) [0|1] ""  BMS,GW,VCU
 SG_ ECC_CooltHomSts : 31|1@0+ (1,0) [0|1] ""  BMS,GW,VCU
 SG_ ECC_PDUInlT : 39|8@0+ (1,-48) [-48|207] "Degree Celsius"  GW,VCU
 SG_ ECC_FrntMotOutlT : 47|8@0+ (1,-48) [-48|207] "Degree Celsius"  GW,VCU
 SG_ ECC_MCURInlT : 55|8@0+ (1,-48) [-48|207] "Degree Celsius"  GW,VCU

BO_ 1605 ECC_0x645: 8 ECC
 SG_ ECC_DefrstAirOutlTSnsrFlt : 16|1@0+ (1,0) [0|1] ""  GW,VCU
 SG_ ECC_ComLost_EAS : 17|1@0+ (1,0) [0|1] ""  GW,VCU
 SG_ ECC_OutdTSnsrFlt : 18|1@0+ (1,0) [0|1] ""  GW,VCU
 SG_ ECC_InsdTSnsrFlt : 19|1@0+ (1,0) [0|1] ""  GW,VCU
 SG_ ECC_EvaprTSnsrFlt : 20|1@0+ (1,0) [0|1] ""  GW,VCU
 SG_ ECC_IntExtCircMotFlt : 21|1@0+ (1,0) [0|1] ""  GW,VCU
 SG_ ECC_LeModThrMotFlt : 22|1@0+ (1,0) [0|1] ""  GW,VCU
 SG_ ECC_RiModThrMotFlt : 23|1@0+ (1,0) [0|1] ""  GW,VCU
 SG_ ECC_CtrlrFlt : 24|1@0+ (1,0) [0|1] ""  GW,VCU
 SG_ ECC_PDUInlTSnsrFlt : 25|1@0+ (1,0) [0|1] ""  GW,VCU
 SG_ ECC_FrntMotOutlTSnsrFlt : 26|1@0+ (1,0) [0|1] ""  GW,VCU
 SG_ ECC_ReMotOutlTSnsrFlt : 27|1@0+ (1,0) [0|1] ""  GW,VCU
 SG_ ECC_ComLost_CDS : 28|1@0+ (1,0) [0|1] ""  GW,VCU
 SG_ ECC_ComLost_WTC_H : 30|1@0+ (1,0) [0|1] ""  GW,VCU
 SG_ ECC_ComLost_WTC_B : 31|1@0+ (1,0) [0|1] ""  GW,VCU
 SG_ ECC_HPTSnsrFlt : 34|1@0+ (1,0) [0|1] ""  GW,VCU
 SG_ ECC_LPTSnsrFlt : 35|1@0+ (1,0) [0|1] ""  GW,VCU
 SG_ ECC_BlowFaceLeAirOutlTSnsrFlt : 36|1@0+ (1,0) [0|1] ""  GW,VCU
 SG_ ECC_BlowFaceRiAirOutlTSnsrFlt : 37|1@0+ (1,0) [0|1] ""  GW,VCU
 SG_ ECC_ReBlowFaceFootMotFlt : 38|1@0+ (1,0) [0|1] ""  GW,VCU
 SG_ ECC_HPSnsrFlt : 39|1@0+ (1,0) [0|1] ""  GW,VCU
 SG_ ECC_LPSnsrFlt : 40|1@0+ (1,0) [0|1] ""  GW,VCU
 SG_ ECC_HeatPmpHeatgEXVFlt : 41|1@0+ (1,0) [0|1] ""  GW,VCU
 SG_ ECC_BattCoolgEXVFlt : 42|1@0+ (1,0) [0|1] ""  GW,VCU
 SG_ ECC_BlowFootLeAirOutlTSnsrFlt : 43|1@0+ (1,0) [0|1] ""  GW,VCU
 SG_ ECC_BlowFootRiAirOutlTSnsrFlt : 44|1@0+ (1,0) [0|1] ""  GW,VCU
 SG_ ECC_LeHybThrMotFlt : 45|1@0+ (1,0) [0|1] ""  GW,VCU
 SG_ ECC_RiHybThrMotFlt : 46|1@0+ (1,0) [0|1] ""  GW,VCU
 SG_ ECC_MCURInlTSnsrFlt : 47|1@0+ (1,0) [0|1] ""  GW,VCU
 SG_ ECC_ComLost_EWP_FD : 48|1@0+ (1,0) [0|1] ""  GW,VCU
 SG_ ECC_ComLost_EWP_RD : 49|1@0+ (1,0) [0|1] ""  GW,VCU
 SG_ ECC_ComLost_EWP_H : 50|1@0+ (1,0) [0|1] ""  GW,VCU
 SG_ ECC_ComLost_EWP_B : 51|1@0+ (1,0) [0|1] ""  GW,VCU
 SG_ ECC_ComLost_EXV_B : 52|1@0+ (1,0) [0|1] ""  GW,VCU
 SG_ ECC_ComLost_EXV_H : 53|1@0+ (1,0) [0|1] ""  GW,VCU
 SG_ ECC_ComLost_CFM : 54|1@0+ (1,0) [0|1] ""  GW,VCU
 SG_ ECC_ComLost_AGS : 55|1@0+ (1,0) [0|1] ""  GW,VCU
 SG_ ECC_ComLost_CVM : 57|1@0+ (1,0) [0|1] ""  GW,VCU
 SG_ ECC_ComLost_MDV : 58|1@0+ (1,0) [0|1] ""  GW,VCU

BO_ 1616 VCU_0x650: 8 VCU
 SG_ VCU_PartVers : 7|32@0+ (1,0) [0|4294967295] ""  GW
 SG_ VCU_SwVersPatch : 39|8@0+ (1,0) [0|255] ""  GW
 SG_ VCU_HwVers : 47|8@0+ (1,0) [0|255] ""  GW
 SG_ VCU_SwVersMain : 55|8@0+ (1,0) [0|255] ""  GW
 SG_ VCU_SwVersMinor : 63|8@0+ (1,0) [0|255] ""  GW

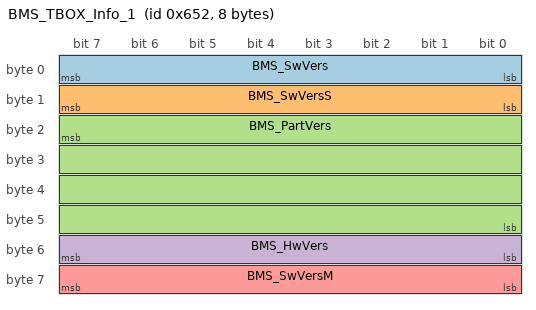
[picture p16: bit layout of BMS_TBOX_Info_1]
BO_ 1618 BMS_TBOX_Info_1: 8 BMS
 SG_ BMS_SwVers : 7|8@0+ (1,0) [0|255] ""  GW,VCU
 SG_ BMS_SwVersS : 15|8@0+ (1,0) [0|255] ""  GW,VCU
 SG_ BMS_PartVers : 23|32@0+ (1,0) [0|4294967295] ""  GW,VCU
 SG_ BMS_HwVers : 55|8@0+ (1,0) [0|255] ""  GW,VCU
 SG_ BMS_SwVersM : 63|8@0+ (1,0) [0|255] ""  GW,VCU

CM_ SG_ 1328 ICC_DrvrTSet "Main driving temperature setting";
CM_ SG_ 1328 ICC_PassTSet "Temperature setting of front passenger";
CM_ SG_ 1328 ICC_VSPVoiceTypSwt "VSP sound type switching switch";
CM_ SG_ 1328 ICC_ECCAUTOReq "Air conditioning AUTO request";
CM_ SG_ 1328 ICC_DrvrSYNCReq "Driver SYNC request";
CM_ SG_ 1328 ICC_ACSwtReq "A/C switch request";
CM_ SG_ 1328 ICC_AirVolSet "Air volume setting";
CM_ SG_ 1328 ICC_ECCIntExtCircReq "Requirement of A/C interior/exterior circulation";
CM_ SG_ 1328 ICC_AirClnSwtReq "Air purification switch request";
CM_ SG_ 1328 ICC_MaxFrntDefrstSet "MaxFront defroster setting";
CM_ SG_ 1328 ICC_VSPCtrlCmd "VSP control instruction";
CM_ SG_ 1328 ICC_NavCtryCod "Navigation-country code";
CM_ SG_ 1328 ICC_NavRoadTyp "Navigation-road typeRoad type from navigation.";
CM_ SG_ 1328 ICC_NavSpdLimUnit "Navigation-speed limit unitSpeed limit unit from naviation.";
CM_ SG_ 1328 ICC_NavSpdLimSts "Navigation-Speed limit stateNavigation state.";
CM_ SG_ 1328 ICC_NavSpdLim "Navigation-speed limitSpeed limit from navigation.";
CM_ SG_ 1328 ICC_BlowWinBtn "Window blowing button";
CM_ SG_ 1328 ICC_NavSpdLimExitDst "Navigation-Speed limit exit distance";
CM_ SG_ 1329 ICC_TotMilgVld_ODO "Effective bit of ODO total mileage";
CM_ SG_ 1329 ICC_TotMilg_ODO "ODO total mileage";
CM_ SG_ 1329 ICC_DispVehSpd "Display speed";
CM_ SG_ 1329 ICC_DispVehSpdUnit "Display vehicle speed unit";
CM_ SG_ 1329 ICC_ADASSigFlt "Instrument ADAS signal fault";
CM_ SG_ 1329 ICC_DispFlt "Instrument display failure";
CM_ SG_ 1329 ICC_WorkshopMode "Setting by customer over display before he wants to tow the vehicle (=Rescue (Workshop Mode)";
CM_ SG_ 1332 ICC_MinChrgSoc_Setting "Minimum SOC setting value for scheduled charging.";
CM_ SG_ 1332 ICC_PwrBattDrvgHeatSwtSts "State of traction battery on-board heating function switch";
CM_ SG_ 1332 ICC_DrvrBlowFaceBtn "Face-blowing button of driver";
CM_ SG_ 1332 ICC_PassBlowFacetBtn "Face-blowing button of front passenger";
CM_ SG_ 1332 ICC_DrvrBlowFootBtn "Feet-blowing button of driver";
CM_ SG_ 1332 ICC_PassBlowFootBtn "Front passenger foot-blowing button";
CM_ SG_ 1332 ICC_BackRowAirOutlModReq "Rear exhaust mode request";
CM_ SG_ 1332 ICC_DchaBtnAvlFlg "Effective flag bit of discharge button";
CM_ SG_ 1332 ICC_ECCSysSwtCmd "Air conditioning system switch instruction";
CM_ SG_ 1332 ICC_DrvrBlowModReq "Voice driver blowing mode request";
CM_ SG_ 1332 ICC_PassBlowModReq "Voice front passenger blowing mode request";
CM_ SG_ 1360 OBC_0x550_CheckSum "OBC_0x550 Message CheckSum  (0x3C)";
CM_ SG_ 1360 OBC_0x550_AliveCounter "OBC_0x550_AliveCounter";
CM_ SG_ 1360 OBC_Pwr "Rated power of on-board charger";
CM_ SG_ 1360 OBC_OutpMaxPwr "OBC output maximum power";
CM_ SG_ 1360 OBC_V2L_RdySts "OBC feedback V2L ready status to VCU";
CM_ SG_ 1360 OBC_V2L_ActvStsFb "OBC  feedback V2L working/active status to VCU";
CM_ SG_ 1360 OBC_T "Temperature of onboard charger";
CM_ SG_ 1360 OBC_CrtSts "Current status of on-board charger";
CM_ SG_ 1360 OBC_DCNegRlyAdhFlt "DC Neg charging relay sticking fault";
CM_ SG_ 1360 OBC_DCPosRlyAdhFlt "DC Pos charging relay sticking fault";
CM_ SG_ 1360 OBC_OperMod "Operating mode of on-board charger";
CM_ SG_ 1360 OBC_PwrSplyHLVIntlkFlt "High and low voltage interlock fault of power supply";
CM_ SG_ 1360 OBC_ACSCIntlkSigChkCircFlt "Open circuit of AC slow charge interlock signal detection loop_P197913_E00";
CM_ SG_ 1360 OBC_DCFCIntlkSigChkCircFlt "Fault in DC fast charge interlock signal detection loop_P197A13_E00";
CM_ SG_ 1360 OBC_PTCIntlkSigChkCircFlt "PTC interlock signal detection loop open circuit_P197B13_E00";
CM_ SG_ 1360 OBC_PwrBattIntlkSigChkCircFlt "Power supply interlock signal detection loop open circuit_P197C13_E00";
CM_ SG_ 1360 OBC_EASIntlkSigChkCircFlt "Open circuit of A/C compressor interlock signal detection loop_P197D13_E00";
CM_ SG_ 1360 OBC_OTARdy_Fb "OBC OTA ready status feedback";
CM_ SG_ 1360 OBC_550_SSecOC_Fresh_Byte0 "Short SecOC Fresh signal byte 0 on CAN";
CM_ SG_ 1360 OBC_550_SSecOC_MAC_Byte0 "Short SecOC MAC signal byte 0 on CAN";
CM_ SG_ 1360 OBC_550_SSecOC_MAC_Byte1 "Short SecOC MAC signal byte 1 on CAN";
CM_ SG_ 1360 OBC_550_SSecOC_MAC_Byte2 "Short SecOC MAC signal byte 2 on CAN";
CM_ SG_ 1363 OBC_0x553_CheckSum "OBC_0x553 Message CheckSum  (0x41)";
CM_ SG_ 1363 OBC_0x553_AliveCounter "OBC_0x553_AliveCounter";
CM_ SG_ 1363 OBC_Splr "OBC supplier";
CM_ SG_ 1363 OBC_ACCrtPhase1 "On-board charger AC terminal current phase1";
CM_ SG_ 1363 OBC_ACCrtPhase2 "On-board charger AC terminal current phase2";
CM_ SG_ 1363 OBC_ACCrtPhase3 "On-board charger AC terminal current phase3";
CM_ SG_ 1363 OBC_EVChrgElectcLockStsFbSig "EV charging inlet lock state feedback";
CM_ SG_ 1364 VCU_PwrGridBreakFlg "Grid outage flag bit";
CM_ SG_ 1364 VCU_ACChrgDchaIndcrLampSts "AC charge and discharge indicator state";
CM_ SG_ 1364 VCU_PrplsnEPwrReq "Propulsion power request (pos&negative)";
CM_ SG_ 1364 VCU_VCUWakeUpSig "VCU wake-up CCU signal";
CM_ SG_ 1364 VCU_DCChrgDchaIndcrLampSts "DC charging indicator state";
CM_ SG_ 1364 VCU_HVBattActPwr "HV battery in/out total actual power (- for discharge, + for charge)";
CM_ SG_ 1364 VCU_PreCdnTi1 " pre-conditioning time t1";
CM_ SG_ 1364 VCU_PreCdnTi2 " pre-conditioning time t2";
CM_ SG_ 1365 VCU_DCChrgElectcLockDrvFlt "DC charging electronic lock drive output abnormal_P193B96_E00";
CM_ SG_ 1365 VCU_ACDCChrgIndcrLamp12VFlt "AC charge and discharge/DC charge status indicator lamp 12 V supply output abnormal_P193E10_E00";
CM_ SG_ 1365 VCU_ComChkFlt_VCU "Communication with VCU to verify malfunction_U30F086_E00";
CM_ SG_ 1365 VCU_ComChkFlt_BMS "Communication with BMS to verify malfunction_U30F186_E00";
CM_ SG_ 1365 VCU_ComLostFlt_ICC "Failure of VCU communicating with ICC_U30F387_E00";
CM_ SG_ 1365 VCU_ComLostFlt_PEPS "VCU and PEPS communication loss faila_U30F587_E00";
CM_ SG_ 1365 VCU_ACChrgNTC1AndNTC2TFlt "Inconsistent temperature between the AC charging/discharging port NTC1 and NTC2_P193149_E00";
CM_ SG_ 1365 VCU_ComChkFlt_ESP "Communication with ESP to verify malfunction_U30F486_E00";
CM_ SG_ 1365 VCU_ComLostFlt_OBC "Lost communication with OBC failure_P30F287_E00";
CM_ SG_ 1365 VCU_CrtSts "Charging current state";
CM_ SG_ 1365 VCU_ACChrgTAlrmFlt "AC charging and discharging port temperature alarming_P193298_E00";
CM_ SG_ 1365 VCU_DCChrgNTC1AndNTC2TFlt "DC charging port NTC1 and NTC2 temperature inconsistent_P193949_E00";
CM_ SG_ 1365 VCU_KL30OperFlt "Normal work abnormality P193F01_E00";
CM_ SG_ 1365 VCU_ACChrgElectcLockDrvFlt "AC charging/discharging electronic lock drive output abnormal_P19346_E00";
CM_ SG_ 1365 VCU_ComLostFlt_VCU "Lost communication with VCU failure_U30F087_E00";
CM_ SG_ 1365 VCU_ACChrgDchaCCSigFlt "Abnormal CC signal of AC charging and discharging_P193202_E00";
CM_ SG_ 1365 VCU_ACChrgElectcUnlockFailFlt "Failure of AC charging/discharging electronic lock unlocking_P193573_E00";
CM_ SG_ 1365 VCU_ACChrgElectcLockFailFlt "AC charging and discharging electronic lock locking failure failure_P193572_E00";
CM_ SG_ 1365 VCU_DCChrgTAlrmFlt "DC charging port temperature alarming_P193A98_E00";
CM_ SG_ 1365 VCU_ChrgCPSigFlt "AC charge and discharge CP input signal abnormal_P193301_E00";
CM_ SG_ 1365 VCU_DCChrgNTC1InpFlt "DC charging port NTC1 input abnormal_P193710_E00";
CM_ SG_ 1365 VCU_DCChrgNTC2InpFlt "DC charging port NTC2 input abnormal_P193810_E00";
CM_ SG_ 1365 VCU_ACChrgNTC1InpFlt "Abnormal input at AC charging/discharging port NTC1_P193010_E00";
CM_ SG_ 1365 VCU_ACChrgNTC2InpFlt "Abnormal input at AC charging/discharging port NTC2_P193110_E00";
CM_ SG_ 1365 VCU_DchgCPSigFlt "Abnormal output signal of AC charge and discharge CP_P193401_E00";
CM_ SG_ 1365 VCU_CC2SigFlt "DC charging CC2 signal abnormal_P193A02_E00";
CM_ SG_ 1365 VCU_CC2Volt "CC2 voltage value";
CM_ SG_ 1365 VCU_ACChrgIndcrLampDrvFlt "AC charge and discharge state indicator lamp drive output abnormal_P193696_E00";
CM_ SG_ 1365 VCU_DCChrgIndcrLampDrvFlt "DC charging state indicator lamp drive output abnormal_P193D96_E00";
CM_ SG_ 1365 VCU_DCChrgASigFlt "DC charging A + signal abnormal_P193D02_E00";
CM_ SG_ 1366 VCU_CP_Amp "CP amplitude";
CM_ SG_ 1366 VCU_CP_Frq "CP frequency";
CM_ SG_ 1366 VCU_CP_DutyRat "CP duty ratio";
CM_ SG_ 1366 VCU_CC_R "Resistance value of CC resistor";
CM_ SG_ 1369 OBC_0x559_CheckSum "OBC_559_CheckSum (E2E data ID: 0x60) ";
CM_ SG_ 1369 OBC_0x559_AliveCounter "OBC_0x559_Message counter";
CM_ SG_ 1369 OBC_InpVoltRng "On-board charger AC side input voltage range";
CM_ SG_ 1369 OBC_MinOutpVolt "Minimum output voltage of on-board charger";
CM_ SG_ 1369 OBC_MaxOutpVolt "Maximum output voltage of on-board charger";
CM_ SG_ 1369 OBC_DCChrggEvseInlVolt "PDU EVSE DC charging side voltage";
CM_ SG_ 1370 OBC_0x55A_CheckSum "OBC_0x55A Message CheckSum  (0x3E)";
CM_ SG_ 1370 OBC_0x55A_AliveCounter "OBC_0x55A_AliveCounter";
CM_ SG_ 1370 OBC_HVDCOutpOverCrtSwFlt "High-voltage DC output overcurrent software fault_P19AD19_E00";
CM_ SG_ 1370 OBC_HVDCOutpOverCrtHwFlt "High-voltage DC output overcurrent hardware malfunctions_P19A619_E00";
CM_ SG_ 1370 OBC_ComLostFlt_BMS "Loss of communication between PDU and BMS (for CAN protocol)_U313787_E00";
CM_ SG_ 1370 OBC_ACVoltOverVoltFlt "AC voltage software overvoltage fault_P198917_E00";
CM_ SG_ 1370 OBC_ACVoltUnderVoltFlt "Undervoltage fault of AC voltage_P19A716_E00";
CM_ SG_ 1370 OBC_HVDCOutpOverVoltHwFlt "High voltage DC output overvoltage hardware fault_P198717_E00";
CM_ SG_ 1370 OBC_HVDCOutpUnderVoltFlt "High-voltage DC output undervoltage fault_P19A416_E00";
CM_ SG_ 1370 OBC_HVDCOutpOverVoltSwFlt "High voltage DC output overvoltage software faulty_P198817_E00";
CM_ SG_ 1370 OBC_InpCrtOverCrtHwSwFlt "Input current overcurrent software faulty_P198B19_E00";
CM_ SG_ 1370 OBC_OverTTurnDwnPwrFlt "Overtemperature drop power faure_P19A84B_E00";
CM_ SG_ 1370 OBC_OverTShutDwnFlt "Overtemperature shutdown failure_P19A94B_E00";
CM_ SG_ 1370 OBC_ExtFlt "OBC external fault";
CM_ SG_ 1370 OBC_IntFlt "PDU OBC internal failure_P19BA96_E00";
CM_ SG_ 1370 OBC_ComLostFlt_VCU "Loss of communication between PDU and VCU (for CAN protocol)_U313587_E00";
CM_ SG_ 1370 OBC_ComLostFlt_CCU "Loss of communication between PDU and CCU (for CAN protocol)_U313687_E00";
CM_ SG_ 1370 OBC_12VPwrSplyVoltUnder "12 V undervoltage P198F16_E00";
CM_ SG_ 1370 OBC_12VPwrSplyVoltOver "12 V Supply Voltage Overvoltage_P198F17_E00";
CM_ SG_ 1392 OBC_0x570_CheckSum "OBC_0x570 Message CheckSum  (0x43)";
CM_ SG_ 1392 OBC_0x570_AliveCounter "OBC_0x570_AliveCounter";
CM_ SG_ 1392 OBC_ACVoltPhase1 "Voltage at AC terminal of on-board charger phase1";
CM_ SG_ 1392 OBC_ACVoltPhase2 "Voltage at AC terminal of on-board charger phase2";
CM_ SG_ 1392 OBC_ACVoltPhase3 "Voltage at AC terminal of on-board charger phase3";
CM_ SG_ 1400 VCU_NotChrgModECCCnseEgy "Energy consumption of A/C in the passenger compartment in non-charging mode";
CM_ SG_ 1400 VCU_NotChrgModVehDrvCnseEgy "Energy consumption of vehicle driving in non-charging mode";
CM_ SG_ 1400 VCU_NotChrgModBHMCnseEgy " Energy consumption of battery thermal management in non-charging mode";
CM_ SG_ 1400 VCU_NotChrgModExtDchaCnseEgy "Energy consumption of battery thermal management in non-charging mode";
CM_ SG_ 1401 VCU_NotChrgModAcsyCnseEgy "Energy consumption of accessories in non-charging mode";
CM_ SG_ 1401 VCU_NotChrgModVehTotCnseEgy "Total energy consumption of vehicle in non-charging mode";
CM_ SG_ 1401 VCU_ChrgModECCCnseEgy "Energy consumption of A/C in the passenger compartment in charging mode";
CM_ SG_ 1401 VCU_ChrgModVehChrgEgy "Vehicle charging energy in charging mode";
CM_ SG_ 1402 VCU_ChrgModBattHeatgMngCnseEgy "Energy consumption of battery thermal management in charging mode";
CM_ SG_ 1402 VCU_ChrgModAcsyCnseEgy "Energy consumption of accessories in charging mode";
CM_ SG_ 1402 VCU_ChrgModChrgEffCnseEgy "Charging efficiency energy loss in charging mode";
CM_ SG_ 1402 VCU_ChrgModVehTotChrgEgy "Total charging energy of vehicle in charging mode";
CM_ SG_ 1403 VCU_NotChrgModECCCnseEgyPerc "Percentage of energy consumption of the A/C in the passenger compartment in the non-charging mode";
CM_ SG_ 1403 VCU_NotChrgModVehDrvCnseEgyPerc "Percentage of energy consumption in non-charging mode";
CM_ SG_ 1403 VCU_NotChrgModBHMCnseEgyPerc "Percentage energy consumption of battery thermal management in non-charging mode";
CM_ SG_ 1403 VCU_NotChrgModExtDchaCnseEgyPerc "Percentage of energy consumption of external discharge in non-charge mode";
CM_ SG_ 1403 VCU_NotChrgModAcsyCnseEgyPerc "Percentage energy consumption of accessories in non-charging mode";
CM_ SG_ 1404 VCU_ChrgModECCCnseEgyPerc "Percentage of energy consumption of A/C in passenger compartment in charging mode";
CM_ SG_ 1404 VCU_ChrgModVehChrgEgyPerc "Percentage of charging energy in charging mode";
CM_ SG_ 1404 VCU_ChrgModBHMCnseEgyPerc "Percentage energy consumption of battery thermal management in charging mode";
CM_ SG_ 1404 VCU_ChrgModAcsyCnseEgyPerc "Percentage energy consumption of accessories in charging mode";
CM_ SG_ 1404 VCU_ChrgModChrgEffCnseEgyPerc "Percentage energy loss at charging efficiency in charging mode";
CM_ SG_ 1404 VCU_ActEgyCnsTyp "Energy consumption visualization type, discriminated by vehicle speed, FB208 ";
CM_ SG_ 1408 VCU_ActChrgTotAh "Total Ah of actual charging on this power-on";
CM_ SG_ 1408 VCU_ActDchgTotAh "Total Ah of actual discharge on this power-on";
CM_ SG_ 1408 VCU_PwrBattAvlEgy "Power battery available energy";
CM_ SG_ 1409 EWP_H_Sts "EWP_H working state";
CM_ SG_ 1409 EWP_B_Sts "EWP_B Operating state";
CM_ SG_ 1409 EWP_FD_Sts "ECW";
CM_ SG_ 1409 EWP_RD_Sts "EP_RD working status";
CM_ SG_ 1409 ECC_ThreeWtrVlvSts "Operating state of three-way water valve";
CM_ SG_ 1409 ECC_AvtvGrilleSts "Operating state of active grille";
CM_ SG_ 1409 ECC_CoolgFanSts "Cooling fan working state";
CM_ SG_ 1409 ECC_ParticleSnsrCrtSts "Current working status of particle sensor";
CM_ SG_ 1409 ECC_CoolgFanSpdRatSts "Cooling fan speed ratio state";
CM_ SG_ 1409 ECC_EXV_B_Sts "EXV_B Battery electronic expansion valve state";
CM_ SG_ 1409 ECC_HeatPumpHeatgEXVSts "State of electronic expansion valve of heat pump";
CM_ SG_ 1409 ECC_ActvGrilleAg "Active grille angle";
CM_ SG_ 1409 ECC_ThreeWtrVlvPerc "Opening degree of three-way valve";
CM_ SG_ 1409 ECC_ParticleSnsrFltSts "Particulate sensor fault status";
CM_ SG_ 1410 ECC_InsdT "Inside temperature";
CM_ SG_ 1410 ECC_RemPwrCnsEstim "Remote power consumption estimation";
CM_ SG_ 1410 ECC_RemTSetSts "Remote temperature setting state";
CM_ SG_ 1410 ECC_RemDefrstSts "Remote defrosting working state";
CM_ SG_ 1410 ECC_BattFldLvlSnsrLamp "battery fluid level sensor warning lamp";
CM_ SG_ 1410 ECC_ResvOperTi "Reservation of A/C working time";
CM_ SG_ 1410 ECC_ParticleConc "Particulate concentration";
CM_ SG_ 1412 ECC_TarPwrReq_WTC_H "WTC_H target power demand";
CM_ SG_ 1412 ECC_TarPwrReq_WTC_B "WTC_B target power demand";
CM_ SG_ 1412 ECC_DchaT "Compressor exhaust temperature";
CM_ SG_ 1412 ECC_FourWayVlvOutlT "Outlet temperature of four-way valve";
CM_ SG_ 1412 ECC_TarGearReq_WTC_B "WTC_B Target gear requirement";
CM_ SG_ 1412 ECC_TarGearReq_WTC_H "WTC_H target gear requirement";
CM_ SG_ 1415 Rotator_0x587_CheckSum "Rotator_0x587_Message Verification (0x6C)Rotator_0x587_CheckSum";
CM_ SG_ 1415 Rotator_0x587_AliveCounter "Rotator_0x587_AliveCounter";
CM_ SG_ 1415 Rotator_ECUSts "CID_ECU_status";
CM_ SG_ 1415 Rotator_PosVld "CID_Pos_valid";
CM_ SG_ 1415 Rotator_PosSts "CID_Pos_status";
CM_ SG_ 1415 Rotator_Pos_rotator "CID_Pos_rotator";
CM_ SG_ 1415 Rotator_OpticSnsrFlt "Optical Sensor Fail A/B";
CM_ SG_ 1415 Rotator_HallSnsrFlt "Hall Sensor Fail A/B";
CM_ SG_ 1419 VCU_HVEgyCnsMovg "Actual energy consumption Wh per km while moving, FB311";
CM_ SG_ 1419 VCU_HVEgyCnsStandstill "Actual energy consumption Wh while in standstill, FB311";
CM_ SG_ 1419 VCU_HVEgyCnsAverage "Average energy consumption history of HV battery of the last 100km, FB311.";
CM_ SG_ 1419 VCU_HVCustSOC "Provide HV customer SOC, FB314";
CM_ SG_ 1422 VCU_EgyCnsHist01 "The energy consumption history-01 of HV battery";
CM_ SG_ 1422 VCU_EgyCnsHist02 "The energy consumption history-02 of HV battery";
CM_ SG_ 1422 VCU_EgyCnsHist03 "The energy consumption history-03 of HV battery";
CM_ SG_ 1422 VCU_EgyCnsHist04 "The energy consumption history-04 of HV battery";
CM_ SG_ 1425 VCU_EgyCnsHist05 "The energy consumption history-05 of HV battery";
CM_ SG_ 1425 VCU_EgyCnsHist06 "The energy consumption history-06 of HV battery";
CM_ SG_ 1425 VCU_EgyCnsHist07 "The energy consumption history-07 of HV battery";
CM_ SG_ 1425 VCU_EgyCnsHist08 "The energy consumption history-08 of HV battery";
CM_ SG_ 1429 BMS_RmChrgTi_FullChrg "Remaining charge time to 100% (full charge)SoC)";
CM_ SG_ 1429 BMS_RmChrgTi_TrgtSoC "Remaining charge time to desired target SOC";
CM_ SG_ 1432 VCU_EgyCnsHist09 "The energy consumption history-09 of HV battery";
CM_ SG_ 1432 VCU_EgyCnsHist10 "The energy consumption history-10 of HV battery";
CM_ SG_ 1436 VCU_MilgChrg_add "added driving range through charging, FB319";
CM_ SG_ 1436 VCU_LowMilg_Warn "Provide Warning Low range information, FB321";
CM_ SG_ 1436 VCU_LowMilgRemAlrm "Provide acoustic signal (Single acoustic signal in case of low driving range remaining), FB323";
CM_ SG_ 1436 VCU_MilgChrgRate_add "Charging milage rate of actual charging process, FB319";
CM_ SG_ 1440 VCU_DCChrgVoltCmd "DC charging terminal voltage command";
CM_ SG_ 1440 VCU_DCChrgCrtCmd "DC charging terminal current command";
CM_ SG_ 1440 VCU_DCChrgOutpVolt "DC charger output voltage";
CM_ SG_ 1440 VCU_DCChrgOutpCrt "DC charger output current";
CM_ SG_ 1444 VCU_HVEM_PwrCoorrPrio "Provide priority of power coordinator, FB381";
CM_ SG_ 1444 VCU_ChrgPwrLim "Provide Charge power limit (due to component temperatures), FB381";
CM_ SG_ 1444 VCU_P_ECC_unfiltered "Provide Max power reserved for ECC(unfiltered), FB380";
CM_ SG_ 1444 VCU_P_Prop_filt "Provide Max power reserved for Propulsion(filtered), FB382";
CM_ SG_ 1476 TBOX_OTA_ownCondchk "TBOX request ECUs to check own conditions for OTA";
CM_ SG_ 1476 TBOX_TerminalRemWakeupSig "Terminal remote wake-up signal";
CM_ SG_ 1476 TBOX_RemSCModReq "Remote charging mode request

";
CM_ SG_ 1476 TBOX_RemPwrBattOpenHeatgReq "Remote traction battery ON heating request";
CM_ SG_ 1476 TBOX_RemPwrBattResvHeatgReq "Remote traction battery heating reservation request";
CM_ SG_ 1476 TBOX_RemInsdInfoDispEna "Remote interior information display enabling";
CM_ SG_ 1476 TBOX_RemECCDefrstModReq "A/C defrosting mode request";
CM_ SG_ 1476 TBOX_RemECCResvDefrstReq "Remote A/C Reservation Defrosting Request";
CM_ SG_ 1476 TBOX_RemECCSetT "Remote A/C set temperature value";
CM_ SG_ 1476 TBOX_RemResvECCSetT "Reserved A/C set temperature value remotely";
CM_ SG_ 1476 TBOX_RemSOCMax "User setting of remote power battery heating cutoff SOC value";
CM_ SG_ 1476 TBOX_4GSigIND "4 G signal strength indication";
CM_ SG_ 1476 TBOX_TSPNotConn "Cannot connect to TSP";
CM_ SG_ 1476 TBOX_EHUNotCONN "Fault of USB communication with audio and entertainment system";
CM_ SG_ 1476 TBOX_WIFIError "WIFI fault";
CM_ SG_ 1476 TBOX_InnerBattError "Built-in battery fault";
CM_ SG_ 1476 TBOX_VoltLow "Low voltage fault";
CM_ SG_ 1476 TBOX_VoltHigh "Overvoltage fault";
CM_ SG_ 1476 TBOX_4GLoss "4 G signal loss fault";
CM_ SG_ 1476 TBOX_RemSWH_Req "Remote Function Steering Wheel Heating Request";
CM_ SG_ 1476 TBOX_OTAInhbReq "TBOX request inhibit function to VCU";
CM_ SG_ 1476 TBOX_5C4_SSecOC_Fresh_Byte0 "Short SecOC Fresh signal byte 0 on CAN";
CM_ SG_ 1476 TBOX_5C4_SSecOC_MAC_Byte0 "Short SecOC MAC signal byte 0 on CAN";
CM_ SG_ 1476 TBOX_5C4_SSecOC_MAC_Byte1 "Short SecOC MAC signal byte 1 on CAN";
CM_ SG_ 1476 TBOX_5C4_SSecOC_MAC_Byte2 "Short SecOC MAC signal byte 2 on CAN";
CM_ SG_ 1514 VCU_TripMilg "Distance travelled in a Trip ( km )";
CM_ SG_ 1514 VCU_TripAvgEgyConsmd "Average energy consumed during the trip (Wh/km)";
CM_ SG_ 1536 EWP_H_SpdRatSts "EWP_H speed ratio state";
CM_ SG_ 1536 EWP_B_SpdRatSts "EWP_B speed ratio state";
CM_ SG_ 1536 EWP_FD_SpdRatSts "EWP_FD speed ratio state";
CM_ SG_ 1536 EWP_RD_SpdRatSts "EWP_RD Speed ratio state";
CM_ SG_ 1536 ECC_HPTSnsrP "Pressure value of high pressure pressure temperature sensor";
CM_ SG_ 1536 ECC_ETXVSts "Solenoid valve (ETXV) state";
CM_ SG_ 1536 ECC_FourWayVlvSts "Four-way valve state";
CM_ SG_ 1536 ECC_HPLinePSts "Pressure state of high-pressure pipeline";
CM_ SG_ 1536 ECC_LPTSnsrP "Pressure value of low pressure pressure temperature sensor";
CM_ SG_ 1536 ECC_LeTHybThrPercReqSts "Left temperature blend damper opening request state";
CM_ SG_ 1536 ECC_RiTHybThrPercReqSts "Right temperature blend damper opening request state";
CM_ SG_ 1552 ICC_UsrSetChrgRmnMilg "User setting charging reminder mileage";
CM_ SG_ 1552 ICC_EPedlSts "Pedal Comport Setting (One Pedal Drive / Roll / Creep) command to VCU";
CM_ SG_ 1552 ICC_AccelMod "Acceleration Mode setting (Low/Mid/High) command to VCU";
CM_ SG_ 1552 ICC_BoostMode "Setting Boost mode active / inactive";
CM_ SG_ 1552 ICC_EgyCnseClrFlg "Energy consumption reset flag bit";
CM_ SG_ 1552 ICC_UsrSetDchaEndDrvgMilg "The user sets the driving range of the discharge cut-off";
CM_ SG_ 1552 ICC_VehiMod "Vehicle mode";
CM_ SG_ 1552 ICC_EgyCnseStcClrFlg "Energy consumption statistics reset flag bit";
CM_ SG_ 1552 ICC_PollingFctOpenSts "Polling function ON status";
CM_ SG_ 1552 ICC_KickFctOpenSts "Foot kicking function is on";
CM_ SG_ 1552 ICC_UsrSetChrgGunAntithft "The user sets whether the charging gun is anti-theft";
CM_ SG_ 1552 ICC_ChrgInsulFctReq "Central control charging insulation function request";
CM_ SG_ 1552 ICC_StopChrgBtn "Stop charging button of central control";
CM_ SG_ 1552 ICC_DrvModSig "Drive mode setting command to all ECUs that behave different basing on active drive mode";
CM_ SG_ 1552 ICC_SetACChrgLmtCrt "Central control setting AC charging current limit";
CM_ SG_ 1552 ICC_SetTrvlMod "Central control setting travel mode";
CM_ SG_ 1552 ICC_RegenLvl "Coasting Mode settings (Off, Normal, high) command to VCU";
CM_ SG_ 1552 ICC_SetChrgEndSOC "Set cut-off charging SOC value with central control";
CM_ SG_ 1552 ICC_StartChrgBtn "Start charging button of central control";
CM_ SG_ 1558 VCU_PwrAntitheftAuthentLrngSts "Power anti-theft learning state";
CM_ SG_ 1558 VCU_PwrAntitheftErrTyp "Power anti-theft error type";
CM_ SG_ 1558 VCU_FreestartMod "VCU Freestart mode";
CM_ SG_ 1558 VCU_DataPartVers "Data part number";
CM_ SG_ 1558 VCU_CalSwVersM "Calibration version number Major version number";
CM_ SG_ 1558 VCU_CalSwVersS "Calibration version number Secondary version number";
CM_ SG_ 1559 VCU_E2PROMAPICallFlt "E2PROM API call faulty_P132806_E00";
CM_ SG_ 1559 VCU_E2PROMReadFlt "Verification failure during E2PROM read_P132864_E00";
CM_ SG_ 1559 VCU_E2PROMWrFlt "Fault during E2PROM write-in_P132865_E00";
CM_ SG_ 1559 VCU_TMonFlt "Temperature monitoring fault_P131698_E00";
CM_ SG_ 1559 VCU_EVCANBusFlt "EVCAN bus fa_U101188_E00";
CM_ SG_ 1559 VCU_CCANBusFlt "CCAN bus fa_U101288_E00";
CM_ SG_ 1559 VCU_BREAKCANBusFlt "BRACECAN bus faulty_U101388_E00";
CM_ SG_ 1559 VCU_ATIC232ComFlt "Communication failure between ATIC232 and MCU SPI_P132182_E00";
CM_ SG_ 1559 VCU_ATIC280ComFlt "Communication failure between ATIC280 and MCU SPI_P132282_E00";
CM_ SG_ 1559 VCU_ATIC239LowSideOutpComFlt "ATIC239 low-side output and MCU SPI communication failure_P132382_E00";
CM_ SG_ 1559 VCU_ATIC239VotSplyMngComFlt "ATIC239 power supply management and MCU SPI communication failure_P132482_E00";
CM_ SG_ 1559 VCU_ATIC239UnderOverVotFlt "ATIC239 5 V supply voltage overvoltage/undervoltage fault_P131A1C_E00";
CM_ SG_ 1559 VCU_ADCnvrFlt "ADConverter faulty_P132596_E00";
CM_ SG_ 1559 VCU_SftyFctMonrFlt "Failure of safety integrity function monitoring_P131996_E00";
CM_ SG_ 1559 VCU_SftyFctMonrMemFlt "Memory Failure_P131B96_E00";
CM_ SG_ 1559 VCU_LVbattCtrlSigOpenFlt "Battery relay control signal open fault_P132913_E00";
CM_ SG_ 1559 VCU_LVbattCtrlSigSTBFlt "Battery relay control signal short circuit to power fa_P132911_E00";
CM_ SG_ 1559 VCU_LVbattCtrlSigSTGFlt "Battery relay control signal short circuit to ground_P132912_E00";
CM_ SG_ 1559 VCU_BMSWakeUpSigOpenFlt "BMS wake-up signal open fault_P100213_E00";
CM_ SG_ 1559 VCU_BMSWakeUpSigSTBFlt "BMS wake signal short circuit to power faet_P100212_E00";
CM_ SG_ 1559 VCU_BMSWakeUpSigSTGFlt "BMS wake-up signal short-circuit to ground fa_P100211_E00";
CM_ SG_ 1559 VCU_PDUWakeUpSigSTBFlt "PDU wake signal short circuit to power faet_P100E12_E00";
CM_ SG_ 1559 VCU_PDUWakeUpSigOpenFlt "Open circuit of PDU wake signal FA_P100E13_E00";
CM_ SG_ 1559 VCU_PDUWakeUpSigSTGFlt "PDU wake signal short circuit to ground fa_P100E11_E00";
CM_ SG_ 1559 VCU_CCUCMUWakeUpSigOpenFlt "Open circuit of CCU/CMU wake signal";
CM_ SG_ 1559 VCU_CCUCMUWakeUpSigSTBFlt "CCU/CMU wake signal short circuit to power fa_P132A11_E00";
CM_ SG_ 1559 VCU_CCUCMUWakeUpSigSTGFlt "CCU/CMU wake signal short circuit to ground fa_P132A12_E00";
CM_ SG_ 1559 VCU_MCUWakeUpSigOpenFlt "MCU wake-up signal open fault_P100113_E00";
CM_ SG_ 1559 VCU_MCUWakeUpSigSTBFlt "MCU wake signal short circuit to power faet_P100112_E00";
CM_ SG_ 1559 VCU_MCUWakeUpSigSTGFlt "MCU wake-up signal short circuit to ground fa_P100111_E00";
CM_ SG_ 1559 VCU_ComLostFlt_CCU "Lost communication between VCU and CCU failure_U101687_E00";
CM_ SG_ 1562 TBOX_RemDTCDmd "Remote diagnosis requirement";
CM_ SG_ 1562 TBOX_DrvRngCld "Driving range prediction from the cloud service";
CM_ SG_ 1562 TBOX_DrvRngCldVld "Valid flag of signal TBOX_DrivRangeCld";
CM_ SG_ 1583 TBOX_CrtTi_Day "Current time_day";
CM_ SG_ 1583 TBOX_CrtTi_Hr "Current time_hour";
CM_ SG_ 1583 TBOX_CrtTi_Mins "Current time_min";
CM_ SG_ 1583 TBOX_CrtTi_Yr "Current time_year";
CM_ SG_ 1583 TBOX_CrtTi_Mth "Current time_month";
CM_ SG_ 1583 TBOX_CrtTi_Sec "Current time_seconds";
CM_ SG_ 1584 VCU_CellTotVolt "Total voltage of monomer accumulation";
CM_ SG_ 1584 VCU_CellMinVolt "Minimum voltage of single cell";
CM_ SG_ 1584 VCU_CellMaxVolt "Maximum voltage of single cell";
CM_ SG_ 1588 VCU_ACChrgShttrSts "AC charge and discharge port door state";
CM_ SG_ 1588 VCU_DCChrgShttrSts "State of DC charging port door panel";
CM_ SG_ 1588 VCU_SCPwrSplyEquipFactry "Slow charging power supply equipment manufacturer";
CM_ SG_ 1588 VCU_ACChrgCrtUpprLmt "AC charging current upper limit";
CM_ SG_ 1594 BMS_Splr "Power battery supplier";
CM_ SG_ 1594 BMS_PwrBattTyp "Power battery type";
CM_ SG_ 1594 BMS_PwrBattPwrStsSOH "Traction battery power state SOH";
CM_ SG_ 1594 BMS_PwrBattPackSerlNr "series number of traction battery PACK";
CM_ SG_ 1594 BMS_PwrBattPackPrllNr "Traction battery PACK parallel number";
CM_ SG_ 1594 BMS_CellCp "Single cell capacity";
CM_ SG_ 1594 BMS_DchaEndCellVolt "Discharge cut-off monomer voltage value";
CM_ SG_ 1604 ECC_644_CheckSum "ECC_644_Message checksum (E2E data ID: 0x14)";
CM_ SG_ 1604 ECC_644_AliveCounter "ECC_644_Message Counter";
CM_ SG_ 1604 ECC_ReMotOutlT "Rear motor outlet water temperature";
CM_ SG_ 1604 ECC_CoolgDfct "ECC HVB Thermal status:cooling defect";
CM_ SG_ 1604 ECC_CooltHomSts "?Coolant homogenisation status";
CM_ SG_ 1604 ECC_PDUInlT "Water temperature at PDU inlet";
CM_ SG_ 1604 ECC_FrntMotOutlT "Water temperature at front motor outlet";
CM_ SG_ 1604 ECC_MCURInlT "MCU_R inlet temperature";
CM_ SG_ 1605 ECC_DefrstAirOutlTSnsrFlt "Defrosting air outlet temperature sensor faulty_P16A01C_E00";
CM_ SG_ 1605 ECC_ComLost_EAS "Loss of communication between ECC and EAS faila_U016487_E00";
CM_ SG_ 1605 ECC_OutdTSnsrFlt "External ambient temperature sensor faulty_P16821C_E00";
CM_ SG_ 1605 ECC_InsdTSnsrFlt "ECC interior temperature sensor fault_P16831C_E00";
CM_ SG_ 1605 ECC_EvaprTSnsrFlt "Evaporation temperature sensor faulty_P16841C_E00";
CM_ SG_ 1605 ECC_IntExtCircMotFlt "Internal and external circulation motor fault";
CM_ SG_ 1605 ECC_LeModThrMotFlt "Left mode damper motor fault";
CM_ SG_ 1605 ECC_RiModThrMotFlt "Right mode damper motor fault";
CM_ SG_ 1605 ECC_CtrlrFlt "ECC controller fault";
CM_ SG_ 1605 ECC_PDUInlTSnsrFlt "PDU inlet temperature sensor fault";
CM_ SG_ 1605 ECC_FrntMotOutlTSnsrFlt "Water temperature sensor at front motor outlet";
CM_ SG_ 1605 ECC_ReMotOutlTSnsrFlt "Rear motor outlet water temperature sensor fault";
CM_ SG_ 1605 ECC_ComLost_CDS "Loss of communication between ECC and CDS";
CM_ SG_ 1605 ECC_ComLost_WTC_H "Lost communication between ECC and WTC_H";
CM_ SG_ 1605 ECC_ComLost_WTC_B "Loss of ECC and WTC_B communication";
CM_ SG_ 1605 ECC_HPTSnsrFlt "High pressure temperature sensor fault";
CM_ SG_ 1605 ECC_LPTSnsrFlt "Low pressure temperature sensor fault";
CM_ SG_ 1605 ECC_BlowFaceLeAirOutlTSnsrFlt "Face-blowing left air outlet temperature sensor failure";
CM_ SG_ 1605 ECC_BlowFaceRiAirOutlTSnsrFlt "Face-blowing right air outlet temperature sensor failure";
CM_ SG_ 1605 ECC_ReBlowFaceFootMotFlt "Rear face blowing foot blowing motor failure";
CM_ SG_ 1605 ECC_HPSnsrFlt "High pressure sensor fault";
CM_ SG_ 1605 ECC_LPSnsrFlt "Low pressure sensor fault";
CM_ SG_ 1605 ECC_HeatPmpHeatgEXVFlt "Failure of electronic expansion valve for heat pump heating";
CM_ SG_ 1605 ECC_BattCoolgEXVFlt "Battery cooling electronic expansion valve fault";
CM_ SG_ 1605 ECC_BlowFootLeAirOutlTSnsrFlt "Foot blowing air outlet temperature sensor LH failure";
CM_ SG_ 1605 ECC_BlowFootRiAirOutlTSnsrFlt "Foot blowing right air outlet temperature sensor failure";
CM_ SG_ 1605 ECC_LeHybThrMotFlt "Left blend damper motor fault";
CM_ SG_ 1605 ECC_RiHybThrMotFlt "Right blend damper motor fault";
CM_ SG_ 1605 ECC_MCURInlTSnsrFlt "MCU_R inlet temperature sensor fault";
CM_ SG_ 1605 ECC_ComLost_EWP_FD "Lost communication between ECC and EWP_FD";
CM_ SG_ 1605 ECC_ComLost_EWP_RD "Lost communication between ECC and EWP_RD";
CM_ SG_ 1605 ECC_ComLost_EWP_H "Lost communication between ECC and EPP-H";
CM_ SG_ 1605 ECC_ComLost_EWP_B "Lost communication between ECC and EWP_B";
CM_ SG_ 1605 ECC_ComLost_EXV_B "Lost ECC and EXV_B communication";
CM_ SG_ 1605 ECC_ComLost_EXV_H "Lost ECC and EXV_H communication";
CM_ SG_ 1605 ECC_ComLost_CFM "ECC and CFM communication loss";
CM_ SG_ 1605 ECC_ComLost_AGS "Lost communication between ECC and AGS";
CM_ SG_ 1605 ECC_ComLost_CVM "ECC and CVM communication loss";
CM_ SG_ 1605 ECC_ComLost_MDV "Lost communication between ECC and MDV";
CM_ SG_ 1616 VCU_PartVers "VCU part number";
CM_ SG_ 1616 VCU_SwVersPatch "VCU software version patch number ";
CM_ SG_ 1616 VCU_HwVers "VCU hardware version number";
CM_ SG_ 1616 VCU_SwVersMain "VCU software version main number ";
CM_ SG_ 1616 VCU_SwVersMinor "VCU software version minor number ";
CM_ SG_ 1618 BMS_SwVers "BMS software scheme number";
CM_ SG_ 1618 BMS_SwVersS "BMS software version number";
CM_ SG_ 1618 BMS_PartVers "BMS part No.";
CM_ SG_ 1618 BMS_HwVers "BMS hardware version number";
CM_ SG_ 1618 BMS_SwVersM "BMS main software version number";
BA_DEF_ BO_  "NmAsrMessage" ENUM  "No","Yes";
BA_DEF_ SG_  "GenSigCycleTime" INT 0 0;
BA_DEF_ BO_  "NmMessage" ENUM  "No","Yes";
BA_DEF_ BO_  "SC_Message" ENUM  "No","Yes","Yes, split message";
BA_DEF_ BO_  "DiagState" ENUM  "No","Yes";
BA_DEF_ BO_  "SC_LinkPos" INT 0 65535;
BA_DEF_ BO_  "DiagRequest" ENUM  "No","Yes";
BA_DEF_ BO_  "DiagFdOnly" ENUM  "No","Yes";
BA_DEF_ BO_  "DiagResponse" ENUM  "No","Yes";
BA_DEF_ BO_  "SCP_AuthInfoTxLength" INT 0 512;
BA_DEF_ BO_  "GenMsgSendType" ENUM  "Cyclic","NotUsed","NotUsed","NotUsed","NotUsed","NotUsed","NotUsed","IfActive","NoMsgSendType";
BA_DEF_ BO_  "SCP_DataId" INT 0 65535;
BA_DEF_ BO_  "GenMsgCycleTime" INT 0 0;
BA_DEF_ BO_  "SCP_FreshnessValueId" INT 0 65535;
BA_DEF_ BO_  "SCP_FreshnessValueLength" INT 0 512;
BA_DEF_ SG_  "GenSigStartValue" INT 0 0;
BA_DEF_ BO_  "SCL_CryptographicMessageID" INT 0 65535;
BA_DEF_ SG_  "GenSigInactiveValue" INT 0 0;
BA_DEF_ SG_  "GenSigSendType" ENUM  "Cyclic","OnWrite","OnWriteWithRepetition","OnChange","OnChangeWithRepetition","IfActive","IfActiveWithRepetition","NoSigSendType";
BA_DEF_ BO_  "SCP_FreshnessValueTxLength" INT 0 512;
BA_DEF_ BO_  "GenMsgCycleTimeFast" INT 0 0;
BA_DEF_ BO_  "GenMsgNrOfRepetition" INT 0 0;
BA_DEF_ BO_  "DiagConnection" INT 0 65535;
BA_DEF_ BO_  "GenMsgDelayTime" INT 0 0;
BA_DEF_ BO_  "CANFD_BRS" ENUM  "0","1";
BA_DEF_ BO_  "VFrameFormat" ENUM  "StandardCAN","ExtendedCAN","reserved","reserved","reserved","reserved","reserved","reserved","reserved","reserved","reserved","reserved","reserved","reserved","StandardCAN_FD","ExtendedCAN_FD";
BA_DEF_ BO_  "GenMsgILSupport" ENUM  "No","Yes";
BA_DEF_ BO_  "GenMsgStartDelayTime" INT 0 65535;
BA_DEF_ BO_  "E2EP01DataLength" INT 0 65535;
BA_DEF_ BO_  "E2EP01DataId" INT 0 65535;
BA_DEF_ SG_  "sigSecLevel" STRING ;
BA_DEF_ SG_  "sigConfig" STRING ;
BA_DEF_ SG_  "sigExplanation" STRING ;
BA_DEF_ SG_  "SystemSignalLongSymbol" STRING ;
BA_DEF_REL_ BU_SG_REL_  "SC_Verification" ENUM  "No","Yes";
BA_DEF_DEF_  "NmAsrMessage" "No";
BA_DEF_DEF_  "GenSigCycleTime" 0;
BA_DEF_DEF_  "NmMessage" "No";
BA_DEF_DEF_  "SC_Message" "No";
BA_DEF_DEF_  "DiagState" "No";
BA_DEF_DEF_  "SC_LinkPos" 0;
BA_DEF_DEF_  "DiagRequest" "No";
BA_DEF_DEF_  "DiagFdOnly" "No";
BA_DEF_DEF_  "DiagResponse" "No";
BA_DEF_DEF_  "SCP_AuthInfoTxLength" 0;
BA_DEF_DEF_  "GenMsgSendType" "Cyclic";
BA_DEF_DEF_  "SCP_DataId" 0;
BA_DEF_DEF_  "GenMsgCycleTime" 0;
BA_DEF_DEF_  "SCP_FreshnessValueId" 0;
BA_DEF_DEF_  "SCP_FreshnessValueLength" 0;
BA_DEF_DEF_  "GenSigStartValue" 0;
BA_DEF_DEF_  "SCL_CryptographicMessageID" 0;
BA_DEF_DEF_  "GenSigInactiveValue" 0;
BA_DEF_DEF_  "GenSigSendType" "Cyclic";
BA_DEF_DEF_  "SCP_FreshnessValueTxLength" 0;
BA_DEF_DEF_  "GenMsgCycleTimeFast" 0;
BA_DEF_DEF_  "GenMsgNrOfRepetition" 0;
BA_DEF_DEF_  "DiagConnection" 0;
BA_DEF_DEF_  "GenMsgDelayTime" 0;
BA_DEF_DEF_  "CANFD_BRS" "1";
BA_DEF_DEF_  "VFrameFormat" "StandardCAN";
BA_DEF_DEF_  "GenMsgILSupport" "Yes";
BA_DEF_DEF_  "GenMsgStartDelayTime" 0;
BA_DEF_DEF_  "E2EP01DataLength" 0;
BA_DEF_DEF_  "E2EP01DataId" 0;
BA_DEF_DEF_  "sigSecLevel" "";
BA_DEF_DEF_  "sigConfig" "";
BA_DEF_DEF_  "sigExplanation" "";
BA_DEF_DEF_REL_ "SC_Verification" "No";
BA_DEF_DEF_  "SystemSignalLongSymbol" "";
BA_ "GenMsgDelayTime" BO_ 1328 20;
BA_ "GenMsgSendType" BO_ 1328 8;
BA_ "GenMsgNrOfRepetition" BO_ 1328 3;
BA_ "GenMsgCycleTimeFast" BO_ 1328 20;
BA_ "VFrameFormat" BO_ 1328 14;
BA_ "GenMsgCycleTime" BO_ 1329 100;
BA_ "VFrameFormat" BO_ 1329 14;
BA_ "GenMsgDelayTime" BO_ 1332 20;
BA_ "GenMsgSendType" BO_ 1332 8;
BA_ "GenMsgNrOfRepetition" BO_ 1332 3;
BA_ "GenMsgCycleTimeFast" BO_ 1332 20;
BA_ "VFrameFormat" BO_ 1332 14;
BA_ "E2EP01DataId" BO_ 1360 60;
BA_ "E2EP01DataLength" BO_ 1360 64;
BA_ "GenMsgCycleTime" BO_ 1360 100;
BA_ "SCL_CryptographicMessageID" BO_ 1360 1360;
BA_ "SCP_AuthInfoTxLength" BO_ 1360 24;
BA_ "SCP_DataId" BO_ 1360 1360;
BA_ "SCP_FreshnessValueId" BO_ 1360 1360;
BA_ "SCP_FreshnessValueLength" BO_ 1360 64;
BA_ "SCP_FreshnessValueTxLength" BO_ 1360 8;
BA_ "SC_LinkPos" BO_ 1360 64;
BA_ "SC_Message" BO_ 1360 1;
BA_ "VFrameFormat" BO_ 1360 14;
BA_ "E2EP01DataId" BO_ 1363 65;
BA_ "E2EP01DataLength" BO_ 1363 64;
BA_ "GenMsgCycleTime" BO_ 1363 100;
BA_ "VFrameFormat" BO_ 1363 14;
BA_ "GenMsgCycleTime" BO_ 1364 100;
BA_ "VFrameFormat" BO_ 1364 14;
BA_ "GenMsgCycleTime" BO_ 1365 100;
BA_ "VFrameFormat" BO_ 1365 14;
BA_ "GenMsgCycleTime" BO_ 1366 100;
BA_ "VFrameFormat" BO_ 1366 14;
BA_ "E2EP01DataId" BO_ 1369 96;
BA_ "E2EP01DataLength" BO_ 1369 64;
BA_ "GenMsgCycleTime" BO_ 1369 100;
BA_ "VFrameFormat" BO_ 1369 14;
BA_ "E2EP01DataId" BO_ 1370 62;
BA_ "E2EP01DataLength" BO_ 1370 64;
BA_ "GenMsgCycleTime" BO_ 1370 100;
BA_ "VFrameFormat" BO_ 1370 14;
BA_ "E2EP01DataId" BO_ 1392 67;
BA_ "E2EP01DataLength" BO_ 1392 64;
BA_ "GenMsgCycleTime" BO_ 1392 100;
BA_ "VFrameFormat" BO_ 1392 14;
BA_ "GenMsgCycleTime" BO_ 1400 500;
BA_ "VFrameFormat" BO_ 1400 14;
BA_ "GenMsgCycleTime" BO_ 1401 500;
BA_ "VFrameFormat" BO_ 1401 14;
BA_ "GenMsgCycleTime" BO_ 1402 500;
BA_ "VFrameFormat" BO_ 1402 14;
BA_ "GenMsgCycleTime" BO_ 1403 500;
BA_ "VFrameFormat" BO_ 1403 14;
BA_ "GenMsgCycleTime" BO_ 1404 500;
BA_ "VFrameFormat" BO_ 1404 14;
BA_ "GenMsgCycleTime" BO_ 1408 250;
BA_ "VFrameFormat" BO_ 1408 14;
BA_ "GenMsgCycleTime" BO_ 1409 200;
BA_ "VFrameFormat" BO_ 1409 14;
BA_ "GenMsgCycleTime" BO_ 1410 100;
BA_ "VFrameFormat" BO_ 1410 14;
BA_ "GenMsgCycleTime" BO_ 1412 100;
BA_ "VFrameFormat" BO_ 1412 14;
BA_ "E2EP01DataId" BO_ 1415 108;
BA_ "E2EP01DataLength" BO_ 1415 64;
BA_ "GenMsgCycleTime" BO_ 1415 200;
BA_ "VFrameFormat" BO_ 1415 14;
BA_ "GenMsgCycleTime" BO_ 1419 1000;
BA_ "VFrameFormat" BO_ 1419 14;
BA_ "GenMsgCycleTime" BO_ 1422 1000;
BA_ "VFrameFormat" BO_ 1422 14;
BA_ "GenMsgCycleTime" BO_ 1425 1000;
BA_ "VFrameFormat" BO_ 1425 14;
BA_ "GenMsgCycleTime" BO_ 1429 1000;
BA_ "VFrameFormat" BO_ 1429 14;
BA_ "GenMsgCycleTime" BO_ 1432 1000;
BA_ "VFrameFormat" BO_ 1432 14;
BA_ "GenMsgCycleTime" BO_ 1436 500;
BA_ "VFrameFormat" BO_ 1436 14;
BA_ "GenMsgCycleTime" BO_ 1440 250;
BA_ "VFrameFormat" BO_ 1440 14;
BA_ "GenMsgCycleTime" BO_ 1444 100;
BA_ "VFrameFormat" BO_ 1444 14;
BA_ "GenMsgCycleTime" BO_ 1476 100;
BA_ "GenMsgDelayTime" BO_ 1476 90;
BA_ "GenMsgStartDelayTime" BO_ 1476 90;
BA_ "SCL_CryptographicMessageID" BO_ 1476 1476;
BA_ "SCP_AuthInfoTxLength" BO_ 1476 24;
BA_ "SCP_DataId" BO_ 1476 1476;
BA_ "SCP_FreshnessValueId" BO_ 1476 1476;
BA_ "SCP_FreshnessValueLength" BO_ 1476 64;
BA_ "SCP_FreshnessValueTxLength" BO_ 1476 8;
BA_ "SC_LinkPos" BO_ 1476 64;
BA_ "SC_Message" BO_ 1476 1;
BA_ "VFrameFormat" BO_ 1476 14;
BA_ "GenMsgCycleTime" BO_ 1514 500;
BA_ "VFrameFormat" BO_ 1514 14;
BA_ "GenMsgCycleTime" BO_ 1536 1000;
BA_ "VFrameFormat" BO_ 1536 14;
BA_ "GenMsgCycleTime" BO_ 1552 1000;
BA_ "GenMsgDelayTime" BO_ 1552 20;
BA_ "GenMsgNrOfRepetition" BO_ 1552 3;
BA_ "GenMsgCycleTimeFast" BO_ 1552 20;
BA_ "VFrameFormat" BO_ 1552 14;
BA_ "GenMsgCycleTime" BO_ 1558 1000;
BA_ "VFrameFormat" BO_ 1558 14;
BA_ "GenMsgCycleTime" BO_ 1559 1000;
BA_ "VFrameFormat" BO_ 1559 14;
BA_ "GenMsgCycleTime" BO_ 1562 1000;
BA_ "GenMsgCycleTimeFast" BO_ 1562 1000;
BA_ "VFrameFormat" BO_ 1562 14;
BA_ "GenMsgCycleTime" BO_ 1583 1000;
BA_ "GenMsgStartDelayTime" BO_ 1583 195;
BA_ "VFrameFormat" BO_ 1583 14;
BA_ "GenMsgCycleTime" BO_ 1584 1000;
BA_ "VFrameFormat" BO_ 1584 14;
BA_ "GenMsgCycleTime" BO_ 1588 1000;
BA_ "VFrameFormat" BO_ 1588 14;
BA_ "GenMsgCycleTime" BO_ 1594 1000;
BA_ "VFrameFormat" BO_ 1594 14;
BA_ "E2EP01DataId" BO_ 1604 20;
BA_ "E2EP01DataLength" BO_ 1604 64;
BA_ "GenMsgCycleTime" BO_ 1604 1000;
BA_ "VFrameFormat" BO_ 1604 14;
BA_ "GenMsgCycleTime" BO_ 1605 1000;
BA_ "VFrameFormat" BO_ 1605 14;
BA_ "GenMsgCycleTime" BO_ 1616 1000;
BA_ "VFrameFormat" BO_ 1616 14;
BA_ "GenMsgCycleTime" BO_ 1618 1000;
BA_ "VFrameFormat" BO_ 1618 14;
BA_ "GenSigSendType" SG_ 1328 ICC_DrvrTSet 2;
BA_ "sigConfig" SG_ 1328 ICC_DrvrTSet "null";
BA_ "sigExplanation" SG_ 1328 ICC_DrvrTSet "null";
BA_ "sigSecLevel" SG_ 1328 ICC_DrvrTSet "null";
BA_ "GenSigSendType" SG_ 1328 ICC_PassTSet 2;
BA_ "sigConfig" SG_ 1328 ICC_PassTSet "null";
BA_ "sigExplanation" SG_ 1328 ICC_PassTSet "null";
BA_ "sigSecLevel" SG_ 1328 ICC_PassTSet "null";
BA_ "GenSigSendType" SG_ 1328 ICC_VSPVoiceTypSwt 2;
BA_ "sigConfig" SG_ 1328 ICC_VSPVoiceTypSwt "null";
BA_ "sigExplanation" SG_ 1328 ICC_VSPVoiceTypSwt "null";
BA_ "sigSecLevel" SG_ 1328 ICC_VSPVoiceTypSwt "null";
BA_ "GenSigSendType" SG_ 1328 ICC_ECCAUTOReq 2;
BA_ "sigConfig" SG_ 1328 ICC_ECCAUTOReq "null";
BA_ "sigExplanation" SG_ 1328 ICC_ECCAUTOReq "null";
BA_ "sigSecLevel" SG_ 1328 ICC_ECCAUTOReq "null";
BA_ "GenSigSendType" SG_ 1328 ICC_DrvrSYNCReq 2;
BA_ "sigConfig" SG_ 1328 ICC_DrvrSYNCReq "null";
BA_ "sigExplanation" SG_ 1328 ICC_DrvrSYNCReq "null";
BA_ "sigSecLevel" SG_ 1328 ICC_DrvrSYNCReq "null";
BA_ "GenSigSendType" SG_ 1328 ICC_ACSwtReq 2;
BA_ "sigConfig" SG_ 1328 ICC_ACSwtReq "null";
BA_ "sigExplanation" SG_ 1328 ICC_ACSwtReq "null";
BA_ "sigSecLevel" SG_ 1328 ICC_ACSwtReq "null";
BA_ "GenSigSendType" SG_ 1328 ICC_AirVolSet 2;
BA_ "sigConfig" SG_ 1328 ICC_AirVolSet "null";
BA_ "sigExplanation" SG_ 1328 ICC_AirVolSet "null";
BA_ "sigSecLevel" SG_ 1328 ICC_AirVolSet "null";
BA_ "GenSigSendType" SG_ 1328 ICC_ECCIntExtCircReq 2;
BA_ "sigConfig" SG_ 1328 ICC_ECCIntExtCircReq "null";
BA_ "sigExplanation" SG_ 1328 ICC_ECCIntExtCircReq "null";
BA_ "sigSecLevel" SG_ 1328 ICC_ECCIntExtCircReq "null";
BA_ "GenSigSendType" SG_ 1328 ICC_AirClnSwtReq 2;
BA_ "sigConfig" SG_ 1328 ICC_AirClnSwtReq "null";
BA_ "sigExplanation" SG_ 1328 ICC_AirClnSwtReq "null";
BA_ "sigSecLevel" SG_ 1328 ICC_AirClnSwtReq "null";
BA_ "GenSigSendType" SG_ 1328 ICC_MaxFrntDefrstSet 2;
BA_ "sigConfig" SG_ 1328 ICC_MaxFrntDefrstSet "null";
BA_ "sigExplanation" SG_ 1328 ICC_MaxFrntDefrstSet "null";
BA_ "sigSecLevel" SG_ 1328 ICC_MaxFrntDefrstSet "null";
BA_ "GenSigSendType" SG_ 1328 ICC_VSPCtrlCmd 2;
BA_ "sigConfig" SG_ 1328 ICC_VSPCtrlCmd "null";
BA_ "sigExplanation" SG_ 1328 ICC_VSPCtrlCmd "null";
BA_ "sigSecLevel" SG_ 1328 ICC_VSPCtrlCmd "null";
BA_ "GenSigSendType" SG_ 1328 ICC_NavCtryCod 2;
BA_ "GenSigStartValue" SG_ 1328 ICC_NavCtryCod 255;
BA_ "sigConfig" SG_ 1328 ICC_NavCtryCod "null";
BA_ "sigExplanation" SG_ 1328 ICC_NavCtryCod "null";
BA_ "sigSecLevel" SG_ 1328 ICC_NavCtryCod "null";
BA_ "GenSigSendType" SG_ 1328 ICC_NavRoadTyp 2;
BA_ "GenSigStartValue" SG_ 1328 ICC_NavRoadTyp 15;
BA_ "sigConfig" SG_ 1328 ICC_NavRoadTyp "null";
BA_ "sigExplanation" SG_ 1328 ICC_NavRoadTyp "null";
BA_ "sigSecLevel" SG_ 1328 ICC_NavRoadTyp "null";
BA_ "GenSigSendType" SG_ 1328 ICC_NavSpdLimUnit 2;
BA_ "sigConfig" SG_ 1328 ICC_NavSpdLimUnit "null";
BA_ "sigExplanation" SG_ 1328 ICC_NavSpdLimUnit "null";
BA_ "sigSecLevel" SG_ 1328 ICC_NavSpdLimUnit "null";
BA_ "GenSigSendType" SG_ 1328 ICC_NavSpdLimSts 2;
BA_ "sigConfig" SG_ 1328 ICC_NavSpdLimSts "null";
BA_ "sigExplanation" SG_ 1328 ICC_NavSpdLimSts "null";
BA_ "sigSecLevel" SG_ 1328 ICC_NavSpdLimSts "null";
BA_ "GenSigSendType" SG_ 1328 ICC_NavSpdLim 2;
BA_ "sigConfig" SG_ 1328 ICC_NavSpdLim "null";
BA_ "sigExplanation" SG_ 1328 ICC_NavSpdLim "null";
BA_ "sigSecLevel" SG_ 1328 ICC_NavSpdLim "null";
BA_ "GenSigSendType" SG_ 1328 ICC_BlowWinBtn 2;
BA_ "sigConfig" SG_ 1328 ICC_BlowWinBtn "null";
BA_ "sigExplanation" SG_ 1328 ICC_BlowWinBtn "null";
BA_ "sigSecLevel" SG_ 1328 ICC_BlowWinBtn "null";
BA_ "GenSigSendType" SG_ 1328 ICC_NavSpdLimExitDst 2;
BA_ "GenSigStartValue" SG_ 1328 ICC_NavSpdLimExitDst 255;
BA_ "sigConfig" SG_ 1328 ICC_NavSpdLimExitDst "null";
BA_ "sigExplanation" SG_ 1328 ICC_NavSpdLimExitDst "null";
BA_ "sigSecLevel" SG_ 1328 ICC_NavSpdLimExitDst "null";
BA_ "sigConfig" SG_ 1329 ICC_TotMilgVld_ODO "null";
BA_ "sigExplanation" SG_ 1329 ICC_TotMilgVld_ODO "null";
BA_ "sigSecLevel" SG_ 1329 ICC_TotMilgVld_ODO "null";
BA_ "sigConfig" SG_ 1329 ICC_TotMilg_ODO "null";
BA_ "sigExplanation" SG_ 1329 ICC_TotMilg_ODO "null";
BA_ "sigSecLevel" SG_ 1329 ICC_TotMilg_ODO "null";
BA_ "sigConfig" SG_ 1329 ICC_DispVehSpd "null";
BA_ "sigExplanation" SG_ 1329 ICC_DispVehSpd "null";
BA_ "sigSecLevel" SG_ 1329 ICC_DispVehSpd "null";
BA_ "sigConfig" SG_ 1329 ICC_DispVehSpdUnit "null";
BA_ "sigExplanation" SG_ 1329 ICC_DispVehSpdUnit "null";
BA_ "sigSecLevel" SG_ 1329 ICC_DispVehSpdUnit "null";
BA_ "sigConfig" SG_ 1329 ICC_ADASSigFlt "null";
BA_ "sigExplanation" SG_ 1329 ICC_ADASSigFlt "null";
BA_ "sigSecLevel" SG_ 1329 ICC_ADASSigFlt "null";
BA_ "sigConfig" SG_ 1329 ICC_DispFlt "null";
BA_ "sigExplanation" SG_ 1329 ICC_DispFlt "null";
BA_ "sigSecLevel" SG_ 1329 ICC_DispFlt "null";
BA_ "GenSigSendType" SG_ 1332 ICC_MinChrgSoc_Setting 2;
BA_ "GenSigSendType" SG_ 1332 ICC_PwrBattDrvgHeatSwtSts 2;
BA_ "sigConfig" SG_ 1332 ICC_PwrBattDrvgHeatSwtSts "null";
BA_ "sigExplanation" SG_ 1332 ICC_PwrBattDrvgHeatSwtSts "null";
BA_ "sigSecLevel" SG_ 1332 ICC_PwrBattDrvgHeatSwtSts "null";
BA_ "GenSigSendType" SG_ 1332 ICC_DrvrBlowFaceBtn 2;
BA_ "sigConfig" SG_ 1332 ICC_DrvrBlowFaceBtn "null";
BA_ "sigExplanation" SG_ 1332 ICC_DrvrBlowFaceBtn "null";
BA_ "sigSecLevel" SG_ 1332 ICC_DrvrBlowFaceBtn "null";
BA_ "GenSigSendType" SG_ 1332 ICC_PassBlowFacetBtn 2;
BA_ "sigConfig" SG_ 1332 ICC_PassBlowFacetBtn "null";
BA_ "sigExplanation" SG_ 1332 ICC_PassBlowFacetBtn "null";
BA_ "sigSecLevel" SG_ 1332 ICC_PassBlowFacetBtn "null";
BA_ "GenSigSendType" SG_ 1332 ICC_DrvrBlowFootBtn 2;
BA_ "sigConfig" SG_ 1332 ICC_DrvrBlowFootBtn "null";
BA_ "sigExplanation" SG_ 1332 ICC_DrvrBlowFootBtn "null";
BA_ "sigSecLevel" SG_ 1332 ICC_DrvrBlowFootBtn "null";
BA_ "GenSigSendType" SG_ 1332 ICC_PassBlowFootBtn 2;
BA_ "sigConfig" SG_ 1332 ICC_PassBlowFootBtn "null";
BA_ "sigExplanation" SG_ 1332 ICC_PassBlowFootBtn "null";
BA_ "sigSecLevel" SG_ 1332 ICC_PassBlowFootBtn "null";
BA_ "sigConfig" SG_ 1332 ICC_BackRowAirOutlModReq "null";
BA_ "sigExplanation" SG_ 1332 ICC_BackRowAirOutlModReq "null";
BA_ "sigSecLevel" SG_ 1332 ICC_BackRowAirOutlModReq "null";
BA_ "GenSigSendType" SG_ 1332 ICC_DchaBtnAvlFlg 2;
BA_ "sigConfig" SG_ 1332 ICC_DchaBtnAvlFlg "null";
BA_ "sigExplanation" SG_ 1332 ICC_DchaBtnAvlFlg "null";
BA_ "sigSecLevel" SG_ 1332 ICC_DchaBtnAvlFlg "null";
BA_ "GenSigSendType" SG_ 1332 ICC_ECCSysSwtCmd 2;
BA_ "sigConfig" SG_ 1332 ICC_ECCSysSwtCmd "null";
BA_ "sigExplanation" SG_ 1332 ICC_ECCSysSwtCmd "null";
BA_ "sigSecLevel" SG_ 1332 ICC_ECCSysSwtCmd "null";
BA_ "GenSigSendType" SG_ 1332 ICC_DrvrBlowModReq 2;
BA_ "sigConfig" SG_ 1332 ICC_DrvrBlowModReq "null";
BA_ "sigExplanation" SG_ 1332 ICC_DrvrBlowModReq "null";
BA_ "sigSecLevel" SG_ 1332 ICC_DrvrBlowModReq "null";
BA_ "GenSigSendType" SG_ 1332 ICC_PassBlowModReq 2;
BA_ "sigConfig" SG_ 1332 ICC_PassBlowModReq "null";
BA_ "sigExplanation" SG_ 1332 ICC_PassBlowModReq "null";
BA_ "sigSecLevel" SG_ 1332 ICC_PassBlowModReq "null";
BA_ "sigConfig" SG_ 1360 OBC_0x550_CheckSum "null";
BA_ "sigExplanation" SG_ 1360 OBC_0x550_CheckSum "null";
BA_ "sigSecLevel" SG_ 1360 OBC_0x550_CheckSum "null";
BA_ "sigConfig" SG_ 1360 OBC_0x550_AliveCounter "null";
BA_ "sigExplanation" SG_ 1360 OBC_0x550_AliveCounter "null";
BA_ "sigSecLevel" SG_ 1360 OBC_0x550_AliveCounter "null";
BA_ "sigConfig" SG_ 1360 OBC_Pwr "null";
BA_ "sigExplanation" SG_ 1360 OBC_Pwr "null";
BA_ "sigSecLevel" SG_ 1360 OBC_Pwr "null";
BA_ "sigConfig" SG_ 1360 OBC_OutpMaxPwr "null";
BA_ "sigExplanation" SG_ 1360 OBC_OutpMaxPwr "null";
BA_ "sigSecLevel" SG_ 1360 OBC_OutpMaxPwr "null";
BA_ "GenSigStartValue" SG_ 1360 OBC_T 48;
BA_ "sigConfig" SG_ 1360 OBC_T "null";
BA_ "sigExplanation" SG_ 1360 OBC_T "null";
BA_ "sigSecLevel" SG_ 1360 OBC_T "null";
BA_ "sigConfig" SG_ 1360 OBC_CrtSts "null";
BA_ "sigExplanation" SG_ 1360 OBC_CrtSts "null";
BA_ "sigSecLevel" SG_ 1360 OBC_CrtSts "null";
BA_ "sigConfig" SG_ 1360 OBC_DCNegRlyAdhFlt "null";
BA_ "sigExplanation" SG_ 1360 OBC_DCNegRlyAdhFlt "null";
BA_ "sigSecLevel" SG_ 1360 OBC_DCNegRlyAdhFlt "null";
BA_ "sigConfig" SG_ 1360 OBC_DCPosRlyAdhFlt "null";
BA_ "sigExplanation" SG_ 1360 OBC_DCPosRlyAdhFlt "null";
BA_ "sigSecLevel" SG_ 1360 OBC_DCPosRlyAdhFlt "null";
BA_ "sigConfig" SG_ 1360 OBC_OperMod "null";
BA_ "sigExplanation" SG_ 1360 OBC_OperMod "null";
BA_ "sigSecLevel" SG_ 1360 OBC_OperMod "null";
BA_ "sigConfig" SG_ 1360 OBC_PwrSplyHLVIntlkFlt "null";
BA_ "sigExplanation" SG_ 1360 OBC_PwrSplyHLVIntlkFlt "null";
BA_ "sigSecLevel" SG_ 1360 OBC_PwrSplyHLVIntlkFlt "null";
BA_ "sigConfig" SG_ 1360 OBC_ACSCIntlkSigChkCircFlt "null";
BA_ "sigExplanation" SG_ 1360 OBC_ACSCIntlkSigChkCircFlt "null";
BA_ "sigSecLevel" SG_ 1360 OBC_ACSCIntlkSigChkCircFlt "null";
BA_ "sigConfig" SG_ 1360 OBC_DCFCIntlkSigChkCircFlt "null";
BA_ "sigExplanation" SG_ 1360 OBC_DCFCIntlkSigChkCircFlt "null";
BA_ "sigSecLevel" SG_ 1360 OBC_DCFCIntlkSigChkCircFlt "null";
BA_ "sigConfig" SG_ 1360 OBC_PTCIntlkSigChkCircFlt "null";
BA_ "sigExplanation" SG_ 1360 OBC_PTCIntlkSigChkCircFlt "null";
BA_ "sigSecLevel" SG_ 1360 OBC_PTCIntlkSigChkCircFlt "null";
BA_ "sigConfig" SG_ 1360 OBC_PwrBattIntlkSigChkCircFlt "null";
BA_ "sigExplanation" SG_ 1360 OBC_PwrBattIntlkSigChkCircFlt "null";
BA_ "sigSecLevel" SG_ 1360 OBC_PwrBattIntlkSigChkCircFlt "null";
BA_ "sigConfig" SG_ 1360 OBC_EASIntlkSigChkCircFlt "null";
BA_ "sigExplanation" SG_ 1360 OBC_EASIntlkSigChkCircFlt "null";
BA_ "sigSecLevel" SG_ 1360 OBC_EASIntlkSigChkCircFlt "null";
BA_ "sigConfig" SG_ 1360 OBC_550_SSecOC_Fresh_Byte0 "null";
BA_ "sigExplanation" SG_ 1360 OBC_550_SSecOC_Fresh_Byte0 "null";
BA_ "sigSecLevel" SG_ 1360 OBC_550_SSecOC_Fresh_Byte0 "null";
BA_ "sigConfig" SG_ 1360 OBC_550_SSecOC_MAC_Byte0 "null";
BA_ "sigExplanation" SG_ 1360 OBC_550_SSecOC_MAC_Byte0 "null";
BA_ "sigSecLevel" SG_ 1360 OBC_550_SSecOC_MAC_Byte0 "null";
BA_ "sigConfig" SG_ 1360 OBC_550_SSecOC_MAC_Byte1 "null";
BA_ "sigExplanation" SG_ 1360 OBC_550_SSecOC_MAC_Byte1 "null";
BA_ "sigSecLevel" SG_ 1360 OBC_550_SSecOC_MAC_Byte1 "null";
BA_ "sigConfig" SG_ 1360 OBC_550_SSecOC_MAC_Byte2 "null";
BA_ "sigExplanation" SG_ 1360 OBC_550_SSecOC_MAC_Byte2 "null";
BA_ "sigSecLevel" SG_ 1360 OBC_550_SSecOC_MAC_Byte2 "null";
BA_ "sigConfig" SG_ 1363 OBC_0x553_CheckSum "null";
BA_ "sigExplanation" SG_ 1363 OBC_0x553_CheckSum "null";
BA_ "sigSecLevel" SG_ 1363 OBC_0x553_CheckSum "null";
BA_ "sigConfig" SG_ 1363 OBC_0x553_AliveCounter "null";
BA_ "sigExplanation" SG_ 1363 OBC_0x553_AliveCounter "null";
BA_ "sigSecLevel" SG_ 1363 OBC_0x553_AliveCounter "null";
BA_ "sigConfig" SG_ 1363 OBC_Splr "null";
BA_ "sigExplanation" SG_ 1363 OBC_Splr "null";
BA_ "sigSecLevel" SG_ 1363 OBC_Splr "null";
BA_ "sigConfig" SG_ 1363 OBC_ACCrtPhase1 "null";
BA_ "sigExplanation" SG_ 1363 OBC_ACCrtPhase1 "null";
BA_ "sigSecLevel" SG_ 1363 OBC_ACCrtPhase1 "null";
BA_ "sigConfig" SG_ 1363 OBC_ACCrtPhase2 "null";
BA_ "sigExplanation" SG_ 1363 OBC_ACCrtPhase2 "null";
BA_ "sigSecLevel" SG_ 1363 OBC_ACCrtPhase2 "null";
BA_ "sigConfig" SG_ 1363 OBC_ACCrtPhase3 "null";
BA_ "sigExplanation" SG_ 1363 OBC_ACCrtPhase3 "null";
BA_ "sigSecLevel" SG_ 1363 OBC_ACCrtPhase3 "null";
BA_ "sigConfig" SG_ 1363 OBC_EVChrgElectcLockStsFbSig "null";
BA_ "sigExplanation" SG_ 1363 OBC_EVChrgElectcLockStsFbSig "null";
BA_ "sigSecLevel" SG_ 1363 OBC_EVChrgElectcLockStsFbSig "A";
BA_ "sigConfig" SG_ 1364 VCU_PwrGridBreakFlg "null";
BA_ "sigExplanation" SG_ 1364 VCU_PwrGridBreakFlg "null";
BA_ "sigSecLevel" SG_ 1364 VCU_PwrGridBreakFlg "null";
BA_ "sigConfig" SG_ 1364 VCU_ACChrgDchaIndcrLampSts "null";
BA_ "sigExplanation" SG_ 1364 VCU_ACChrgDchaIndcrLampSts "null";
BA_ "sigSecLevel" SG_ 1364 VCU_ACChrgDchaIndcrLampSts "null";
BA_ "GenSigStartValue" SG_ 1364 VCU_PrplsnEPwrReq 6000;
BA_ "sigConfig" SG_ 1364 VCU_VCUWakeUpSig "null";
BA_ "sigExplanation" SG_ 1364 VCU_VCUWakeUpSig "null";
BA_ "sigSecLevel" SG_ 1364 VCU_VCUWakeUpSig "null";
BA_ "sigConfig" SG_ 1364 VCU_DCChrgDchaIndcrLampSts "null";
BA_ "sigExplanation" SG_ 1364 VCU_DCChrgDchaIndcrLampSts "null";
BA_ "sigSecLevel" SG_ 1364 VCU_DCChrgDchaIndcrLampSts "null";
BA_ "GenSigStartValue" SG_ 1364 VCU_HVBattActPwr 6000;
BA_ "sigConfig" SG_ 1364 VCU_PreCdnTi1 "null";
BA_ "sigExplanation" SG_ 1364 VCU_PreCdnTi1 "null";
BA_ "sigSecLevel" SG_ 1364 VCU_PreCdnTi1 "null";
BA_ "sigConfig" SG_ 1364 VCU_PreCdnTi2 "null";
BA_ "sigExplanation" SG_ 1364 VCU_PreCdnTi2 "null";
BA_ "sigSecLevel" SG_ 1364 VCU_PreCdnTi2 "null";
BA_ "sigConfig" SG_ 1365 VCU_DCChrgElectcLockDrvFlt "null";
BA_ "sigExplanation" SG_ 1365 VCU_DCChrgElectcLockDrvFlt "null";
BA_ "sigSecLevel" SG_ 1365 VCU_DCChrgElectcLockDrvFlt "null";
BA_ "sigConfig" SG_ 1365 VCU_ACDCChrgIndcrLamp12VFlt "null";
BA_ "sigExplanation" SG_ 1365 VCU_ACDCChrgIndcrLamp12VFlt "null";
BA_ "sigSecLevel" SG_ 1365 VCU_ACDCChrgIndcrLamp12VFlt "null";
BA_ "sigConfig" SG_ 1365 VCU_ComChkFlt_VCU "null";
BA_ "sigExplanation" SG_ 1365 VCU_ComChkFlt_VCU "null";
BA_ "sigSecLevel" SG_ 1365 VCU_ComChkFlt_VCU "null";
BA_ "sigConfig" SG_ 1365 VCU_ComChkFlt_BMS "null";
BA_ "sigExplanation" SG_ 1365 VCU_ComChkFlt_BMS "null";
BA_ "sigSecLevel" SG_ 1365 VCU_ComChkFlt_BMS "null";
BA_ "sigConfig" SG_ 1365 VCU_ComLostFlt_ICC "null";
BA_ "sigExplanation" SG_ 1365 VCU_ComLostFlt_ICC "null";
BA_ "sigSecLevel" SG_ 1365 VCU_ComLostFlt_ICC "null";
BA_ "sigConfig" SG_ 1365 VCU_ComLostFlt_PEPS "null";
BA_ "sigExplanation" SG_ 1365 VCU_ComLostFlt_PEPS "null";
BA_ "sigSecLevel" SG_ 1365 VCU_ComLostFlt_PEPS "null";
BA_ "sigConfig" SG_ 1365 VCU_ACChrgNTC1AndNTC2TFlt "null";
BA_ "sigExplanation" SG_ 1365 VCU_ACChrgNTC1AndNTC2TFlt "null";
BA_ "sigSecLevel" SG_ 1365 VCU_ACChrgNTC1AndNTC2TFlt "null";
BA_ "sigConfig" SG_ 1365 VCU_ComChkFlt_ESP "null";
BA_ "sigExplanation" SG_ 1365 VCU_ComChkFlt_ESP "null";
BA_ "sigSecLevel" SG_ 1365 VCU_ComChkFlt_ESP "null";
BA_ "sigConfig" SG_ 1365 VCU_ComLostFlt_OBC "null";
BA_ "sigExplanation" SG_ 1365 VCU_ComLostFlt_OBC "null";
BA_ "sigSecLevel" SG_ 1365 VCU_ComLostFlt_OBC "null";
BA_ "sigConfig" SG_ 1365 VCU_CrtSts "null";
BA_ "sigExplanation" SG_ 1365 VCU_CrtSts "null";
BA_ "sigSecLevel" SG_ 1365 VCU_CrtSts "null";
BA_ "sigConfig" SG_ 1365 VCU_ACChrgTAlrmFlt "null";
BA_ "sigExplanation" SG_ 1365 VCU_ACChrgTAlrmFlt "null";
BA_ "sigSecLevel" SG_ 1365 VCU_ACChrgTAlrmFlt "null";
BA_ "sigConfig" SG_ 1365 VCU_DCChrgNTC1AndNTC2TFlt "null";
BA_ "sigExplanation" SG_ 1365 VCU_DCChrgNTC1AndNTC2TFlt "null";
BA_ "sigSecLevel" SG_ 1365 VCU_DCChrgNTC1AndNTC2TFlt "null";
BA_ "sigConfig" SG_ 1365 VCU_KL30OperFlt "null";
BA_ "sigExplanation" SG_ 1365 VCU_KL30OperFlt "null";
BA_ "sigSecLevel" SG_ 1365 VCU_KL30OperFlt "null";
BA_ "sigConfig" SG_ 1365 VCU_ACChrgElectcLockDrvFlt "null";
BA_ "sigExplanation" SG_ 1365 VCU_ACChrgElectcLockDrvFlt "null";
BA_ "sigSecLevel" SG_ 1365 VCU_ACChrgElectcLockDrvFlt "null";
BA_ "sigConfig" SG_ 1365 VCU_ComLostFlt_VCU "null";
BA_ "sigExplanation" SG_ 1365 VCU_ComLostFlt_VCU "null";
BA_ "sigSecLevel" SG_ 1365 VCU_ComLostFlt_VCU "null";
BA_ "sigConfig" SG_ 1365 VCU_ACChrgDchaCCSigFlt "null";
BA_ "sigExplanation" SG_ 1365 VCU_ACChrgDchaCCSigFlt "null";
BA_ "sigSecLevel" SG_ 1365 VCU_ACChrgDchaCCSigFlt "null";
BA_ "sigConfig" SG_ 1365 VCU_ACChrgElectcUnlockFailFlt "null";
BA_ "sigExplanation" SG_ 1365 VCU_ACChrgElectcUnlockFailFlt "null";
BA_ "sigSecLevel" SG_ 1365 VCU_ACChrgElectcUnlockFailFlt "null";
BA_ "sigConfig" SG_ 1365 VCU_ACChrgElectcLockFailFlt "null";
BA_ "sigExplanation" SG_ 1365 VCU_ACChrgElectcLockFailFlt "null";
BA_ "sigSecLevel" SG_ 1365 VCU_ACChrgElectcLockFailFlt "null";
BA_ "sigConfig" SG_ 1365 VCU_DCChrgTAlrmFlt "null";
BA_ "sigExplanation" SG_ 1365 VCU_DCChrgTAlrmFlt "null";
BA_ "sigSecLevel" SG_ 1365 VCU_DCChrgTAlrmFlt "null";
BA_ "sigConfig" SG_ 1365 VCU_ChrgCPSigFlt "null";
BA_ "sigExplanation" SG_ 1365 VCU_ChrgCPSigFlt "null";
BA_ "sigSecLevel" SG_ 1365 VCU_ChrgCPSigFlt "null";
BA_ "sigConfig" SG_ 1365 VCU_DCChrgNTC1InpFlt "null";
BA_ "sigExplanation" SG_ 1365 VCU_DCChrgNTC1InpFlt "null";
BA_ "sigSecLevel" SG_ 1365 VCU_DCChrgNTC1InpFlt "null";
BA_ "sigConfig" SG_ 1365 VCU_DCChrgNTC2InpFlt "null";
BA_ "sigExplanation" SG_ 1365 VCU_DCChrgNTC2InpFlt "null";
BA_ "sigSecLevel" SG_ 1365 VCU_DCChrgNTC2InpFlt "null";
BA_ "sigConfig" SG_ 1365 VCU_ACChrgNTC1InpFlt "null";
BA_ "sigExplanation" SG_ 1365 VCU_ACChrgNTC1InpFlt "null";
BA_ "sigSecLevel" SG_ 1365 VCU_ACChrgNTC1InpFlt "null";
BA_ "sigConfig" SG_ 1365 VCU_ACChrgNTC2InpFlt "null";
BA_ "sigExplanation" SG_ 1365 VCU_ACChrgNTC2InpFlt "null";
BA_ "sigSecLevel" SG_ 1365 VCU_ACChrgNTC2InpFlt "null";
BA_ "sigConfig" SG_ 1365 VCU_DchgCPSigFlt "null";
BA_ "sigExplanation" SG_ 1365 VCU_DchgCPSigFlt "null";
BA_ "sigSecLevel" SG_ 1365 VCU_DchgCPSigFlt "null";
BA_ "sigConfig" SG_ 1365 VCU_CC2SigFlt "null";
BA_ "sigExplanation" SG_ 1365 VCU_CC2SigFlt "null";
BA_ "sigSecLevel" SG_ 1365 VCU_CC2SigFlt "null";
BA_ "sigConfig" SG_ 1365 VCU_CC2Volt "null";
BA_ "sigExplanation" SG_ 1365 VCU_CC2Volt "null";
BA_ "sigSecLevel" SG_ 1365 VCU_CC2Volt "null";
BA_ "sigConfig" SG_ 1365 VCU_ACChrgIndcrLampDrvFlt "null";
BA_ "sigExplanation" SG_ 1365 VCU_ACChrgIndcrLampDrvFlt "null";
BA_ "sigSecLevel" SG_ 1365 VCU_ACChrgIndcrLampDrvFlt "null";
BA_ "sigConfig" SG_ 1365 VCU_DCChrgIndcrLampDrvFlt "null";
BA_ "sigExplanation" SG_ 1365 VCU_DCChrgIndcrLampDrvFlt "null";
BA_ "sigSecLevel" SG_ 1365 VCU_DCChrgIndcrLampDrvFlt "null";
BA_ "sigConfig" SG_ 1365 VCU_DCChrgASigFlt "null";
BA_ "sigExplanation" SG_ 1365 VCU_DCChrgASigFlt "null";
BA_ "sigSecLevel" SG_ 1365 VCU_DCChrgASigFlt "null";
BA_ "sigConfig" SG_ 1366 VCU_CP_Amp "null";
BA_ "sigExplanation" SG_ 1366 VCU_CP_Amp "null";
BA_ "sigSecLevel" SG_ 1366 VCU_CP_Amp "null";
BA_ "sigConfig" SG_ 1366 VCU_CP_Frq "null";
BA_ "sigExplanation" SG_ 1366 VCU_CP_Frq "null";
BA_ "sigSecLevel" SG_ 1366 VCU_CP_Frq "null";
BA_ "sigConfig" SG_ 1366 VCU_CP_DutyRat "null";
BA_ "sigExplanation" SG_ 1366 VCU_CP_DutyRat "null";
BA_ "sigSecLevel" SG_ 1366 VCU_CP_DutyRat "null";
BA_ "sigConfig" SG_ 1366 VCU_CC_R "null";
BA_ "sigExplanation" SG_ 1366 VCU_CC_R "null";
BA_ "sigSecLevel" SG_ 1366 VCU_CC_R "null";
BA_ "sigConfig" SG_ 1369 OBC_InpVoltRng "null";
BA_ "sigExplanation" SG_ 1369 OBC_InpVoltRng "null";
BA_ "sigSecLevel" SG_ 1369 OBC_InpVoltRng "null";
BA_ "sigConfig" SG_ 1369 OBC_MinOutpVolt "null";
BA_ "sigExplanation" SG_ 1369 OBC_MinOutpVolt "null";
BA_ "sigSecLevel" SG_ 1369 OBC_MinOutpVolt "null";
BA_ "sigConfig" SG_ 1369 OBC_MaxOutpVolt "null";
BA_ "sigExplanation" SG_ 1369 OBC_MaxOutpVolt "null";
BA_ "sigSecLevel" SG_ 1369 OBC_MaxOutpVolt "null";
BA_ "sigConfig" SG_ 1369 OBC_DCChrggEvseInlVolt "null";
BA_ "sigExplanation" SG_ 1369 OBC_DCChrggEvseInlVolt "null";
BA_ "sigSecLevel" SG_ 1369 OBC_DCChrggEvseInlVolt "null";
BA_ "sigConfig" SG_ 1370 OBC_0x55A_CheckSum "null";
BA_ "sigExplanation" SG_ 1370 OBC_0x55A_CheckSum "null";
BA_ "sigSecLevel" SG_ 1370 OBC_0x55A_CheckSum "null";
BA_ "sigConfig" SG_ 1370 OBC_0x55A_AliveCounter "null";
BA_ "sigExplanation" SG_ 1370 OBC_0x55A_AliveCounter "null";
BA_ "sigSecLevel" SG_ 1370 OBC_0x55A_AliveCounter "null";
BA_ "sigConfig" SG_ 1370 OBC_HVDCOutpOverCrtSwFlt "null";
BA_ "sigExplanation" SG_ 1370 OBC_HVDCOutpOverCrtSwFlt "null";
BA_ "sigSecLevel" SG_ 1370 OBC_HVDCOutpOverCrtSwFlt "null";
BA_ "sigConfig" SG_ 1370 OBC_HVDCOutpOverCrtHwFlt "null";
BA_ "sigExplanation" SG_ 1370 OBC_HVDCOutpOverCrtHwFlt "null";
BA_ "sigSecLevel" SG_ 1370 OBC_HVDCOutpOverCrtHwFlt "null";
BA_ "sigConfig" SG_ 1370 OBC_ComLostFlt_BMS "null";
BA_ "sigExplanation" SG_ 1370 OBC_ComLostFlt_BMS "null";
BA_ "sigSecLevel" SG_ 1370 OBC_ComLostFlt_BMS "null";
BA_ "sigConfig" SG_ 1370 OBC_ACVoltOverVoltFlt "null";
BA_ "sigExplanation" SG_ 1370 OBC_ACVoltOverVoltFlt "null";
BA_ "sigSecLevel" SG_ 1370 OBC_ACVoltOverVoltFlt "null";
BA_ "sigConfig" SG_ 1370 OBC_ACVoltUnderVoltFlt "null";
BA_ "sigExplanation" SG_ 1370 OBC_ACVoltUnderVoltFlt "null";
BA_ "sigSecLevel" SG_ 1370 OBC_ACVoltUnderVoltFlt "null";
BA_ "sigConfig" SG_ 1370 OBC_HVDCOutpOverVoltHwFlt "null";
BA_ "sigExplanation" SG_ 1370 OBC_HVDCOutpOverVoltHwFlt "null";
BA_ "sigSecLevel" SG_ 1370 OBC_HVDCOutpOverVoltHwFlt "null";
BA_ "sigConfig" SG_ 1370 OBC_HVDCOutpUnderVoltFlt "null";
BA_ "sigExplanation" SG_ 1370 OBC_HVDCOutpUnderVoltFlt "null";
BA_ "sigSecLevel" SG_ 1370 OBC_HVDCOutpUnderVoltFlt "null";
BA_ "sigConfig" SG_ 1370 OBC_HVDCOutpOverVoltSwFlt "null";
BA_ "sigExplanation" SG_ 1370 OBC_HVDCOutpOverVoltSwFlt "null";
BA_ "sigSecLevel" SG_ 1370 OBC_HVDCOutpOverVoltSwFlt "null";
BA_ "sigConfig" SG_ 1370 OBC_InpCrtOverCrtHwSwFlt "null";
BA_ "sigExplanation" SG_ 1370 OBC_InpCrtOverCrtHwSwFlt "null";
BA_ "sigSecLevel" SG_ 1370 OBC_InpCrtOverCrtHwSwFlt "null";
BA_ "sigConfig" SG_ 1370 OBC_OverTTurnDwnPwrFlt "null";
BA_ "sigExplanation" SG_ 1370 OBC_OverTTurnDwnPwrFlt "null";
BA_ "sigSecLevel" SG_ 1370 OBC_OverTTurnDwnPwrFlt "null";
BA_ "sigConfig" SG_ 1370 OBC_OverTShutDwnFlt "null";
BA_ "sigExplanation" SG_ 1370 OBC_OverTShutDwnFlt "null";
BA_ "sigSecLevel" SG_ 1370 OBC_OverTShutDwnFlt "null";
BA_ "sigConfig" SG_ 1370 OBC_IntFlt "null";
BA_ "sigExplanation" SG_ 1370 OBC_IntFlt "null";
BA_ "sigSecLevel" SG_ 1370 OBC_IntFlt "null";
BA_ "sigConfig" SG_ 1370 OBC_ComLostFlt_VCU "null";
BA_ "sigExplanation" SG_ 1370 OBC_ComLostFlt_VCU "null";
BA_ "sigSecLevel" SG_ 1370 OBC_ComLostFlt_VCU "null";
BA_ "sigConfig" SG_ 1370 OBC_ComLostFlt_CCU "null";
BA_ "sigExplanation" SG_ 1370 OBC_ComLostFlt_CCU "null";
BA_ "sigSecLevel" SG_ 1370 OBC_ComLostFlt_CCU "null";
BA_ "sigConfig" SG_ 1370 OBC_12VPwrSplyVoltUnder "null";
BA_ "sigExplanation" SG_ 1370 OBC_12VPwrSplyVoltUnder "null";
BA_ "sigSecLevel" SG_ 1370 OBC_12VPwrSplyVoltUnder "null";
BA_ "sigConfig" SG_ 1370 OBC_12VPwrSplyVoltOver "null";
BA_ "sigExplanation" SG_ 1370 OBC_12VPwrSplyVoltOver "null";
BA_ "sigSecLevel" SG_ 1370 OBC_12VPwrSplyVoltOver "null";
BA_ "sigConfig" SG_ 1392 OBC_0x570_CheckSum "null";
BA_ "sigExplanation" SG_ 1392 OBC_0x570_CheckSum "null";
BA_ "sigSecLevel" SG_ 1392 OBC_0x570_CheckSum "null";
BA_ "sigConfig" SG_ 1392 OBC_0x570_AliveCounter "null";
BA_ "sigExplanation" SG_ 1392 OBC_0x570_AliveCounter "null";
BA_ "sigSecLevel" SG_ 1392 OBC_0x570_AliveCounter "null";
BA_ "sigConfig" SG_ 1392 OBC_ACVoltPhase1 "null";
BA_ "sigExplanation" SG_ 1392 OBC_ACVoltPhase1 "null";
BA_ "sigSecLevel" SG_ 1392 OBC_ACVoltPhase1 "null";
BA_ "sigConfig" SG_ 1392 OBC_ACVoltPhase2 "null";
BA_ "sigExplanation" SG_ 1392 OBC_ACVoltPhase2 "null";
BA_ "sigSecLevel" SG_ 1392 OBC_ACVoltPhase2 "null";
BA_ "sigConfig" SG_ 1392 OBC_ACVoltPhase3 "null";
BA_ "sigExplanation" SG_ 1392 OBC_ACVoltPhase3 "null";
BA_ "sigSecLevel" SG_ 1392 OBC_ACVoltPhase3 "null";
BA_ "sigConfig" SG_ 1400 VCU_NotChrgModECCCnseEgy "null";
BA_ "sigExplanation" SG_ 1400 VCU_NotChrgModECCCnseEgy "null";
BA_ "sigSecLevel" SG_ 1400 VCU_NotChrgModECCCnseEgy "null";
BA_ "sigConfig" SG_ 1400 VCU_NotChrgModVehDrvCnseEgy "null";
BA_ "sigExplanation" SG_ 1400 VCU_NotChrgModVehDrvCnseEgy "null";
BA_ "sigSecLevel" SG_ 1400 VCU_NotChrgModVehDrvCnseEgy "null";
BA_ "sigConfig" SG_ 1400 VCU_NotChrgModBHMCnseEgy "null";
BA_ "sigExplanation" SG_ 1400 VCU_NotChrgModBHMCnseEgy "null";
BA_ "sigSecLevel" SG_ 1400 VCU_NotChrgModBHMCnseEgy "null";
BA_ "sigConfig" SG_ 1400 VCU_NotChrgModExtDchaCnseEgy "null";
BA_ "sigExplanation" SG_ 1400 VCU_NotChrgModExtDchaCnseEgy "null";
BA_ "sigSecLevel" SG_ 1400 VCU_NotChrgModExtDchaCnseEgy "null";
BA_ "sigConfig" SG_ 1401 VCU_NotChrgModAcsyCnseEgy "null";
BA_ "sigExplanation" SG_ 1401 VCU_NotChrgModAcsyCnseEgy "null";
BA_ "sigSecLevel" SG_ 1401 VCU_NotChrgModAcsyCnseEgy "null";
BA_ "sigConfig" SG_ 1401 VCU_NotChrgModVehTotCnseEgy "null";
BA_ "sigExplanation" SG_ 1401 VCU_NotChrgModVehTotCnseEgy "null";
BA_ "sigSecLevel" SG_ 1401 VCU_NotChrgModVehTotCnseEgy "null";
BA_ "sigConfig" SG_ 1401 VCU_ChrgModECCCnseEgy "null";
BA_ "sigExplanation" SG_ 1401 VCU_ChrgModECCCnseEgy "null";
BA_ "sigSecLevel" SG_ 1401 VCU_ChrgModECCCnseEgy "null";
BA_ "sigConfig" SG_ 1401 VCU_ChrgModVehChrgEgy "null";
BA_ "sigExplanation" SG_ 1401 VCU_ChrgModVehChrgEgy "null";
BA_ "sigSecLevel" SG_ 1401 VCU_ChrgModVehChrgEgy "null";
BA_ "sigConfig" SG_ 1402 VCU_ChrgModBattHeatgMngCnseEgy "null";
BA_ "sigExplanation" SG_ 1402 VCU_ChrgModBattHeatgMngCnseEgy "null";
BA_ "sigSecLevel" SG_ 1402 VCU_ChrgModBattHeatgMngCnseEgy "null";
BA_ "sigConfig" SG_ 1402 VCU_ChrgModAcsyCnseEgy "null";
BA_ "sigExplanation" SG_ 1402 VCU_ChrgModAcsyCnseEgy "null";
BA_ "sigSecLevel" SG_ 1402 VCU_ChrgModAcsyCnseEgy "null";
BA_ "sigConfig" SG_ 1402 VCU_ChrgModChrgEffCnseEgy "null";
BA_ "sigExplanation" SG_ 1402 VCU_ChrgModChrgEffCnseEgy "null";
BA_ "sigSecLevel" SG_ 1402 VCU_ChrgModChrgEffCnseEgy "null";
BA_ "sigConfig" SG_ 1402 VCU_ChrgModVehTotChrgEgy "null";
BA_ "sigExplanation" SG_ 1402 VCU_ChrgModVehTotChrgEgy "null";
BA_ "sigSecLevel" SG_ 1402 VCU_ChrgModVehTotChrgEgy "null";
BA_ "sigConfig" SG_ 1403 VCU_NotChrgModECCCnseEgyPerc "null";
BA_ "sigExplanation" SG_ 1403 VCU_NotChrgModECCCnseEgyPerc "null";
BA_ "sigSecLevel" SG_ 1403 VCU_NotChrgModECCCnseEgyPerc "null";
BA_ "sigConfig" SG_ 1403 VCU_NotChrgModVehDrvCnseEgyPerc "null";
BA_ "sigExplanation" SG_ 1403 VCU_NotChrgModVehDrvCnseEgyPerc "null";
BA_ "sigSecLevel" SG_ 1403 VCU_NotChrgModVehDrvCnseEgyPerc "null";
BA_ "sigConfig" SG_ 1403 VCU_NotChrgModBHMCnseEgyPerc "null";
BA_ "sigExplanation" SG_ 1403 VCU_NotChrgModBHMCnseEgyPerc "null";
BA_ "sigSecLevel" SG_ 1403 VCU_NotChrgModBHMCnseEgyPerc "null";
BA_ "sigConfig" SG_ 1403 VCU_NotChrgModExtDchaCnseEgyPerc "null";
BA_ "sigExplanation" SG_ 1403 VCU_NotChrgModExtDchaCnseEgyPerc "null";
BA_ "sigSecLevel" SG_ 1403 VCU_NotChrgModExtDchaCnseEgyPerc "null";
BA_ "sigConfig" SG_ 1403 VCU_NotChrgModAcsyCnseEgyPerc "null";
BA_ "sigExplanation" SG_ 1403 VCU_NotChrgModAcsyCnseEgyPerc "null";
BA_ "sigSecLevel" SG_ 1403 VCU_NotChrgModAcsyCnseEgyPerc "null";
BA_ "sigConfig" SG_ 1404 VCU_ChrgModECCCnseEgyPerc "null";
BA_ "sigExplanation" SG_ 1404 VCU_ChrgModECCCnseEgyPerc "null";
BA_ "sigSecLevel" SG_ 1404 VCU_ChrgModECCCnseEgyPerc "null";
BA_ "sigConfig" SG_ 1404 VCU_ChrgModVehChrgEgyPerc "null";
BA_ "sigExplanation" SG_ 1404 VCU_ChrgModVehChrgEgyPerc "null";
BA_ "sigSecLevel" SG_ 1404 VCU_ChrgModVehChrgEgyPerc "null";
BA_ "sigConfig" SG_ 1404 VCU_ChrgModBHMCnseEgyPerc "null";
BA_ "sigExplanation" SG_ 1404 VCU_ChrgModBHMCnseEgyPerc "null";
BA_ "sigSecLevel" SG_ 1404 VCU_ChrgModBHMCnseEgyPerc "null";
BA_ "sigConfig" SG_ 1404 VCU_ChrgModAcsyCnseEgyPerc "null";
BA_ "sigExplanation" SG_ 1404 VCU_ChrgModAcsyCnseEgyPerc "null";
BA_ "sigSecLevel" SG_ 1404 VCU_ChrgModAcsyCnseEgyPerc "null";
BA_ "sigConfig" SG_ 1404 VCU_ChrgModChrgEffCnseEgyPerc "null";
BA_ "sigExplanation" SG_ 1404 VCU_ChrgModChrgEffCnseEgyPerc "null";
BA_ "sigSecLevel" SG_ 1404 VCU_ChrgModChrgEffCnseEgyPerc "null";
BA_ "sigConfig" SG_ 1408 VCU_ActChrgTotAh "null";
BA_ "sigExplanation" SG_ 1408 VCU_ActChrgTotAh "null";
BA_ "sigSecLevel" SG_ 1408 VCU_ActChrgTotAh "null";
BA_ "sigConfig" SG_ 1408 VCU_ActDchgTotAh "null";
BA_ "sigExplanation" SG_ 1408 VCU_ActDchgTotAh "null";
BA_ "sigSecLevel" SG_ 1408 VCU_ActDchgTotAh "null";
BA_ "sigConfig" SG_ 1408 VCU_PwrBattAvlEgy "null";
BA_ "sigExplanation" SG_ 1408 VCU_PwrBattAvlEgy "null";
BA_ "sigSecLevel" SG_ 1408 VCU_PwrBattAvlEgy "null";
BA_ "sigConfig" SG_ 1409 EWP_H_Sts "null";
BA_ "sigExplanation" SG_ 1409 EWP_H_Sts "null";
BA_ "sigSecLevel" SG_ 1409 EWP_H_Sts "null";
BA_ "sigConfig" SG_ 1409 EWP_B_Sts "null";
BA_ "sigExplanation" SG_ 1409 EWP_B_Sts "null";
BA_ "sigSecLevel" SG_ 1409 EWP_B_Sts "null";
BA_ "sigConfig" SG_ 1409 EWP_FD_Sts "null";
BA_ "sigExplanation" SG_ 1409 EWP_FD_Sts "null";
BA_ "sigSecLevel" SG_ 1409 EWP_FD_Sts "null";
BA_ "sigConfig" SG_ 1409 EWP_RD_Sts "null";
BA_ "sigExplanation" SG_ 1409 EWP_RD_Sts "null";
BA_ "sigSecLevel" SG_ 1409 EWP_RD_Sts "null";
BA_ "sigConfig" SG_ 1409 ECC_ThreeWtrVlvSts "null";
BA_ "sigExplanation" SG_ 1409 ECC_ThreeWtrVlvSts "null";
BA_ "sigSecLevel" SG_ 1409 ECC_ThreeWtrVlvSts "null";
BA_ "sigConfig" SG_ 1409 ECC_AvtvGrilleSts "null";
BA_ "sigExplanation" SG_ 1409 ECC_AvtvGrilleSts "null";
BA_ "sigSecLevel" SG_ 1409 ECC_AvtvGrilleSts "null";
BA_ "sigConfig" SG_ 1409 ECC_CoolgFanSts "null";
BA_ "sigExplanation" SG_ 1409 ECC_CoolgFanSts "null";
BA_ "sigSecLevel" SG_ 1409 ECC_CoolgFanSts "null";
BA_ "sigConfig" SG_ 1409 ECC_ParticleSnsrCrtSts "null";
BA_ "sigExplanation" SG_ 1409 ECC_ParticleSnsrCrtSts "null";
BA_ "sigSecLevel" SG_ 1409 ECC_ParticleSnsrCrtSts "null";
BA_ "sigConfig" SG_ 1409 ECC_CoolgFanSpdRatSts "null";
BA_ "sigExplanation" SG_ 1409 ECC_CoolgFanSpdRatSts "null";
BA_ "sigSecLevel" SG_ 1409 ECC_CoolgFanSpdRatSts "null";
BA_ "sigConfig" SG_ 1409 ECC_EXV_B_Sts "null";
BA_ "sigExplanation" SG_ 1409 ECC_EXV_B_Sts "null";
BA_ "sigSecLevel" SG_ 1409 ECC_EXV_B_Sts "null";
BA_ "sigConfig" SG_ 1409 ECC_HeatPumpHeatgEXVSts "null";
BA_ "sigExplanation" SG_ 1409 ECC_HeatPumpHeatgEXVSts "null";
BA_ "sigSecLevel" SG_ 1409 ECC_HeatPumpHeatgEXVSts "null";
BA_ "sigConfig" SG_ 1409 ECC_ActvGrilleAg "null";
BA_ "sigExplanation" SG_ 1409 ECC_ActvGrilleAg "null";
BA_ "sigSecLevel" SG_ 1409 ECC_ActvGrilleAg "null";
BA_ "sigConfig" SG_ 1409 ECC_ThreeWtrVlvPerc "null";
BA_ "sigExplanation" SG_ 1409 ECC_ThreeWtrVlvPerc "null";
BA_ "sigSecLevel" SG_ 1409 ECC_ThreeWtrVlvPerc "null";
BA_ "sigConfig" SG_ 1409 ECC_ParticleSnsrFltSts "null";
BA_ "sigExplanation" SG_ 1409 ECC_ParticleSnsrFltSts "null";
BA_ "sigSecLevel" SG_ 1409 ECC_ParticleSnsrFltSts "null";
BA_ "GenSigStartValue" SG_ 1410 ECC_InsdT 48;
BA_ "sigConfig" SG_ 1410 ECC_InsdT "null";
BA_ "sigExplanation" SG_ 1410 ECC_InsdT "null";
BA_ "sigSecLevel" SG_ 1410 ECC_InsdT "null";
BA_ "sigConfig" SG_ 1410 ECC_RemPwrCnsEstim "null";
BA_ "sigExplanation" SG_ 1410 ECC_RemPwrCnsEstim "null";
BA_ "sigSecLevel" SG_ 1410 ECC_RemPwrCnsEstim "null";
BA_ "sigConfig" SG_ 1410 ECC_RemTSetSts "null";
BA_ "sigExplanation" SG_ 1410 ECC_RemTSetSts "null";
BA_ "sigSecLevel" SG_ 1410 ECC_RemTSetSts "null";
BA_ "sigConfig" SG_ 1410 ECC_RemDefrstSts "null";
BA_ "sigExplanation" SG_ 1410 ECC_RemDefrstSts "null";
BA_ "sigSecLevel" SG_ 1410 ECC_RemDefrstSts "null";
BA_ "sigConfig" SG_ 1410 ECC_ResvOperTi "null";
BA_ "sigExplanation" SG_ 1410 ECC_ResvOperTi "null";
BA_ "sigSecLevel" SG_ 1410 ECC_ResvOperTi "null";
BA_ "sigConfig" SG_ 1410 ECC_ParticleConc "null";
BA_ "sigExplanation" SG_ 1410 ECC_ParticleConc "null";
BA_ "sigSecLevel" SG_ 1410 ECC_ParticleConc "null";
BA_ "sigConfig" SG_ 1412 ECC_TarPwrReq_WTC_H "null";
BA_ "sigExplanation" SG_ 1412 ECC_TarPwrReq_WTC_H "null";
BA_ "sigSecLevel" SG_ 1412 ECC_TarPwrReq_WTC_H "null";
BA_ "sigConfig" SG_ 1412 ECC_TarPwrReq_WTC_B "null";
BA_ "sigExplanation" SG_ 1412 ECC_TarPwrReq_WTC_B "null";
BA_ "sigSecLevel" SG_ 1412 ECC_TarPwrReq_WTC_B "null";
BA_ "GenSigStartValue" SG_ 1412 ECC_DchaT 48;
BA_ "sigConfig" SG_ 1412 ECC_DchaT "null";
BA_ "sigExplanation" SG_ 1412 ECC_DchaT "null";
BA_ "sigSecLevel" SG_ 1412 ECC_DchaT "null";
BA_ "GenSigStartValue" SG_ 1412 ECC_FourWayVlvOutlT 48;
BA_ "sigConfig" SG_ 1412 ECC_FourWayVlvOutlT "null";
BA_ "sigExplanation" SG_ 1412 ECC_FourWayVlvOutlT "null";
BA_ "sigSecLevel" SG_ 1412 ECC_FourWayVlvOutlT "null";
BA_ "sigConfig" SG_ 1412 ECC_TarGearReq_WTC_B "null";
BA_ "sigExplanation" SG_ 1412 ECC_TarGearReq_WTC_B "null";
BA_ "sigSecLevel" SG_ 1412 ECC_TarGearReq_WTC_B "null";
BA_ "sigConfig" SG_ 1412 ECC_TarGearReq_WTC_H "null";
BA_ "sigExplanation" SG_ 1412 ECC_TarGearReq_WTC_H "null";
BA_ "sigSecLevel" SG_ 1412 ECC_TarGearReq_WTC_H "null";
BA_ "sigConfig" SG_ 1415 Rotator_0x587_CheckSum "null";
BA_ "sigExplanation" SG_ 1415 Rotator_0x587_CheckSum "null";
BA_ "sigSecLevel" SG_ 1415 Rotator_0x587_CheckSum "null";
BA_ "sigConfig" SG_ 1415 Rotator_0x587_AliveCounter "null";
BA_ "sigExplanation" SG_ 1415 Rotator_0x587_AliveCounter "null";
BA_ "sigSecLevel" SG_ 1415 Rotator_0x587_AliveCounter "null";
BA_ "sigConfig" SG_ 1415 Rotator_ECUSts "null";
BA_ "sigExplanation" SG_ 1415 Rotator_ECUSts "null";
BA_ "sigSecLevel" SG_ 1415 Rotator_ECUSts "null";
BA_ "sigConfig" SG_ 1415 Rotator_PosVld "null";
BA_ "sigExplanation" SG_ 1415 Rotator_PosVld "null";
BA_ "sigSecLevel" SG_ 1415 Rotator_PosVld "null";
BA_ "sigConfig" SG_ 1415 Rotator_PosSts "null";
BA_ "sigExplanation" SG_ 1415 Rotator_PosSts "null";
BA_ "sigSecLevel" SG_ 1415 Rotator_PosSts "null";
BA_ "sigConfig" SG_ 1415 Rotator_Pos_rotator "null";
BA_ "sigExplanation" SG_ 1415 Rotator_Pos_rotator "null";
BA_ "sigSecLevel" SG_ 1415 Rotator_Pos_rotator "null";
BA_ "GenSigSendType" SG_ 1415 Rotator_RotationReqSteerClmn 3;
BA_ "GenSigStartValue" SG_ 1419 VCU_HVEgyCnsMovg 9999;
BA_ "GenSigStartValue" SG_ 1419 VCU_HVEgyCnsStandstill 2000;
BA_ "GenSigStartValue" SG_ 1419 VCU_HVEgyCnsAverage 9999;
BA_ "GenSigStartValue" SG_ 1422 VCU_EgyCnsHist01 9999;
BA_ "GenSigStartValue" SG_ 1422 VCU_EgyCnsHist02 9999;
BA_ "GenSigStartValue" SG_ 1422 VCU_EgyCnsHist03 9999;
BA_ "GenSigStartValue" SG_ 1422 VCU_EgyCnsHist04 9999;
BA_ "GenSigStartValue" SG_ 1425 VCU_EgyCnsHist05 9999;
BA_ "GenSigStartValue" SG_ 1425 VCU_EgyCnsHist06 9999;
BA_ "GenSigStartValue" SG_ 1425 VCU_EgyCnsHist07 9999;
BA_ "GenSigStartValue" SG_ 1425 VCU_EgyCnsHist08 9999;
BA_ "sigConfig" SG_ 1429 BMS_RmChrgTi_FullChrg "null";
BA_ "sigExplanation" SG_ 1429 BMS_RmChrgTi_FullChrg "null";
BA_ "sigSecLevel" SG_ 1429 BMS_RmChrgTi_FullChrg "null";
BA_ "sigConfig" SG_ 1429 BMS_RmChrgTi_TrgtSoC "null";
BA_ "sigExplanation" SG_ 1429 BMS_RmChrgTi_TrgtSoC "null";
BA_ "sigSecLevel" SG_ 1429 BMS_RmChrgTi_TrgtSoC "null";
BA_ "GenSigStartValue" SG_ 1432 VCU_EgyCnsHist09 9999;
BA_ "GenSigStartValue" SG_ 1432 VCU_EgyCnsHist10 9999;
BA_ "sigConfig" SG_ 1440 VCU_DCChrgVoltCmd "null";
BA_ "sigExplanation" SG_ 1440 VCU_DCChrgVoltCmd "null";
BA_ "sigSecLevel" SG_ 1440 VCU_DCChrgVoltCmd "null";
BA_ "sigConfig" SG_ 1440 VCU_DCChrgCrtCmd "null";
BA_ "sigExplanation" SG_ 1440 VCU_DCChrgCrtCmd "null";
BA_ "sigSecLevel" SG_ 1440 VCU_DCChrgCrtCmd "null";
BA_ "sigConfig" SG_ 1440 VCU_DCChrgOutpVolt "null";
BA_ "sigExplanation" SG_ 1440 VCU_DCChrgOutpVolt "null";
BA_ "sigSecLevel" SG_ 1440 VCU_DCChrgOutpVolt "null";
BA_ "sigConfig" SG_ 1440 VCU_DCChrgOutpCrt "null";
BA_ "sigExplanation" SG_ 1440 VCU_DCChrgOutpCrt "null";
BA_ "sigSecLevel" SG_ 1440 VCU_DCChrgOutpCrt "null";
BA_ "GenSigStartValue" SG_ 1444 VCU_P_Prop_filt 4500;
BA_ "sigConfig" SG_ 1476 TBOX_TerminalRemWakeupSig "null";
BA_ "sigExplanation" SG_ 1476 TBOX_TerminalRemWakeupSig "null";
BA_ "sigSecLevel" SG_ 1476 TBOX_TerminalRemWakeupSig "null";
BA_ "sigConfig" SG_ 1476 TBOX_RemSCModReq "null";
BA_ "sigExplanation" SG_ 1476 TBOX_RemSCModReq "null";
BA_ "sigSecLevel" SG_ 1476 TBOX_RemSCModReq "null";
BA_ "sigConfig" SG_ 1476 TBOX_RemPwrBattOpenHeatgReq "null";
BA_ "sigExplanation" SG_ 1476 TBOX_RemPwrBattOpenHeatgReq "null";
BA_ "sigSecLevel" SG_ 1476 TBOX_RemPwrBattOpenHeatgReq "null";
BA_ "sigConfig" SG_ 1476 TBOX_RemPwrBattResvHeatgReq "null";
BA_ "sigExplanation" SG_ 1476 TBOX_RemPwrBattResvHeatgReq "null";
BA_ "sigSecLevel" SG_ 1476 TBOX_RemPwrBattResvHeatgReq "null";
BA_ "sigConfig" SG_ 1476 TBOX_RemInsdInfoDispEna "null";
BA_ "sigExplanation" SG_ 1476 TBOX_RemInsdInfoDispEna "null";
BA_ "sigSecLevel" SG_ 1476 TBOX_RemInsdInfoDispEna "null";
BA_ "sigConfig" SG_ 1476 TBOX_RemECCDefrstModReq "null";
BA_ "sigExplanation" SG_ 1476 TBOX_RemECCDefrstModReq "null";
BA_ "sigSecLevel" SG_ 1476 TBOX_RemECCDefrstModReq "null";
BA_ "sigConfig" SG_ 1476 TBOX_RemECCResvDefrstReq "null";
BA_ "sigExplanation" SG_ 1476 TBOX_RemECCResvDefrstReq "null";
BA_ "sigSecLevel" SG_ 1476 TBOX_RemECCResvDefrstReq "null";
BA_ "sigConfig" SG_ 1476 TBOX_RemECCSetT "null";
BA_ "sigExplanation" SG_ 1476 TBOX_RemECCSetT "null";
BA_ "sigSecLevel" SG_ 1476 TBOX_RemECCSetT "null";
BA_ "sigConfig" SG_ 1476 TBOX_RemResvECCSetT "null";
BA_ "sigExplanation" SG_ 1476 TBOX_RemResvECCSetT "null";
BA_ "sigSecLevel" SG_ 1476 TBOX_RemResvECCSetT "null";
BA_ "sigConfig" SG_ 1476 TBOX_RemSOCMax "null";
BA_ "sigExplanation" SG_ 1476 TBOX_RemSOCMax "null";
BA_ "sigSecLevel" SG_ 1476 TBOX_RemSOCMax "null";
BA_ "sigConfig" SG_ 1476 TBOX_4GSigIND "null";
BA_ "sigExplanation" SG_ 1476 TBOX_4GSigIND "null";
BA_ "sigSecLevel" SG_ 1476 TBOX_4GSigIND "null";
BA_ "sigConfig" SG_ 1476 TBOX_TSPNotConn "null";
BA_ "sigExplanation" SG_ 1476 TBOX_TSPNotConn "null";
BA_ "sigSecLevel" SG_ 1476 TBOX_TSPNotConn "null";
BA_ "sigConfig" SG_ 1476 TBOX_EHUNotCONN "null";
BA_ "sigExplanation" SG_ 1476 TBOX_EHUNotCONN "null";
BA_ "sigSecLevel" SG_ 1476 TBOX_EHUNotCONN "null";
BA_ "sigConfig" SG_ 1476 TBOX_WIFIError "null";
BA_ "sigExplanation" SG_ 1476 TBOX_WIFIError "null";
BA_ "sigSecLevel" SG_ 1476 TBOX_WIFIError "null";
BA_ "sigConfig" SG_ 1476 TBOX_InnerBattError "null";
BA_ "sigExplanation" SG_ 1476 TBOX_InnerBattError "null";
BA_ "sigSecLevel" SG_ 1476 TBOX_InnerBattError "null";
BA_ "sigConfig" SG_ 1476 TBOX_VoltLow "null";
BA_ "sigExplanation" SG_ 1476 TBOX_VoltLow "null";
BA_ "sigSecLevel" SG_ 1476 TBOX_VoltLow "null";
BA_ "sigConfig" SG_ 1476 TBOX_VoltHigh "null";
BA_ "sigExplanation" SG_ 1476 TBOX_VoltHigh "null";
BA_ "sigSecLevel" SG_ 1476 TBOX_VoltHigh "null";
BA_ "sigConfig" SG_ 1476 TBOX_4GLoss "null";
BA_ "sigExplanation" SG_ 1476 TBOX_4GLoss "null";
BA_ "sigSecLevel" SG_ 1476 TBOX_4GLoss "null";
BA_ "sigConfig" SG_ 1476 TBOX_RemSWH_Req "null";
BA_ "sigExplanation" SG_ 1476 TBOX_RemSWH_Req "null";
BA_ "sigSecLevel" SG_ 1476 TBOX_RemSWH_Req "null";
BA_ "sigConfig" SG_ 1476 TBOX_5C4_SSecOC_Fresh_Byte0 "null";
BA_ "sigExplanation" SG_ 1476 TBOX_5C4_SSecOC_Fresh_Byte0 "null";
BA_ "sigSecLevel" SG_ 1476 TBOX_5C4_SSecOC_Fresh_Byte0 "null";
BA_ "sigConfig" SG_ 1476 TBOX_5C4_SSecOC_MAC_Byte0 "null";
BA_ "sigExplanation" SG_ 1476 TBOX_5C4_SSecOC_MAC_Byte0 "null";
BA_ "sigSecLevel" SG_ 1476 TBOX_5C4_SSecOC_MAC_Byte0 "null";
BA_ "sigConfig" SG_ 1476 TBOX_5C4_SSecOC_MAC_Byte1 "null";
BA_ "sigExplanation" SG_ 1476 TBOX_5C4_SSecOC_MAC_Byte1 "null";
BA_ "sigSecLevel" SG_ 1476 TBOX_5C4_SSecOC_MAC_Byte1 "null";
BA_ "sigConfig" SG_ 1476 TBOX_5C4_SSecOC_MAC_Byte2 "null";
BA_ "sigExplanation" SG_ 1476 TBOX_5C4_SSecOC_MAC_Byte2 "null";
BA_ "sigSecLevel" SG_ 1476 TBOX_5C4_SSecOC_MAC_Byte2 "null";
BA_ "sigConfig" SG_ 1536 EWP_H_SpdRatSts "null";
BA_ "sigExplanation" SG_ 1536 EWP_H_SpdRatSts "null";
BA_ "sigSecLevel" SG_ 1536 EWP_H_SpdRatSts "null";
BA_ "sigConfig" SG_ 1536 EWP_B_SpdRatSts "null";
BA_ "sigExplanation" SG_ 1536 EWP_B_SpdRatSts "null";
BA_ "sigSecLevel" SG_ 1536 EWP_B_SpdRatSts "null";
BA_ "sigConfig" SG_ 1536 EWP_FD_SpdRatSts "null";
BA_ "sigExplanation" SG_ 1536 EWP_FD_SpdRatSts "null";
BA_ "sigSecLevel" SG_ 1536 EWP_FD_SpdRatSts "null";
BA_ "sigConfig" SG_ 1536 EWP_RD_SpdRatSts "null";
BA_ "sigExplanation" SG_ 1536 EWP_RD_SpdRatSts "null";
BA_ "sigSecLevel" SG_ 1536 EWP_RD_SpdRatSts "null";
BA_ "sigConfig" SG_ 1536 ECC_HPTSnsrP "null";
BA_ "sigExplanation" SG_ 1536 ECC_HPTSnsrP "null";
BA_ "sigSecLevel" SG_ 1536 ECC_HPTSnsrP "null";
BA_ "sigConfig" SG_ 1536 ECC_ETXVSts "null";
BA_ "sigExplanation" SG_ 1536 ECC_ETXVSts "null";
BA_ "sigSecLevel" SG_ 1536 ECC_ETXVSts "null";
BA_ "sigConfig" SG_ 1536 ECC_FourWayVlvSts "null";
BA_ "sigExplanation" SG_ 1536 ECC_FourWayVlvSts "null";
BA_ "sigSecLevel" SG_ 1536 ECC_FourWayVlvSts "null";
BA_ "sigConfig" SG_ 1536 ECC_HPLinePSts "null";
BA_ "sigExplanation" SG_ 1536 ECC_HPLinePSts "null";
BA_ "sigSecLevel" SG_ 1536 ECC_HPLinePSts "null";
BA_ "sigConfig" SG_ 1536 ECC_LPTSnsrP "null";
BA_ "sigExplanation" SG_ 1536 ECC_LPTSnsrP "null";
BA_ "sigSecLevel" SG_ 1536 ECC_LPTSnsrP "null";
BA_ "sigConfig" SG_ 1536 ECC_LeTHybThrPercReqSts "null";
BA_ "sigExplanation" SG_ 1536 ECC_LeTHybThrPercReqSts "null";
BA_ "sigSecLevel" SG_ 1536 ECC_LeTHybThrPercReqSts "null";
BA_ "sigConfig" SG_ 1536 ECC_RiTHybThrPercReqSts "null";
BA_ "sigExplanation" SG_ 1536 ECC_RiTHybThrPercReqSts "null";
BA_ "sigSecLevel" SG_ 1536 ECC_RiTHybThrPercReqSts "null";
BA_ "GenSigStartValue" SG_ 1552 ICC_UsrSetChrgRmnMilg 255;
BA_ "sigConfig" SG_ 1552 ICC_UsrSetChrgRmnMilg "null";
BA_ "sigExplanation" SG_ 1552 ICC_UsrSetChrgRmnMilg "null";
BA_ "sigSecLevel" SG_ 1552 ICC_UsrSetChrgRmnMilg "null";
BA_ "GenSigSendType" SG_ 1552 ICC_EPedlSts 4;
BA_ "sigConfig" SG_ 1552 ICC_EPedlSts "null";
BA_ "sigExplanation" SG_ 1552 ICC_EPedlSts "null";
BA_ "sigSecLevel" SG_ 1552 ICC_EPedlSts "null";
BA_ "GenSigSendType" SG_ 1552 ICC_AccelMod 4;
BA_ "sigConfig" SG_ 1552 ICC_AccelMod "null";
BA_ "sigExplanation" SG_ 1552 ICC_AccelMod "null";
BA_ "sigSecLevel" SG_ 1552 ICC_AccelMod "null";
BA_ "sigConfig" SG_ 1552 ICC_EgyCnseClrFlg "null";
BA_ "sigExplanation" SG_ 1552 ICC_EgyCnseClrFlg "null";
BA_ "sigSecLevel" SG_ 1552 ICC_EgyCnseClrFlg "null";
BA_ "GenSigStartValue" SG_ 1552 ICC_UsrSetDchaEndDrvgMilg 1023;
BA_ "sigConfig" SG_ 1552 ICC_UsrSetDchaEndDrvgMilg "null";
BA_ "sigExplanation" SG_ 1552 ICC_UsrSetDchaEndDrvgMilg "null";
BA_ "sigSecLevel" SG_ 1552 ICC_UsrSetDchaEndDrvgMilg "null";
BA_ "sigConfig" SG_ 1552 ICC_VehiMod "null";
BA_ "sigExplanation" SG_ 1552 ICC_VehiMod "null";
BA_ "sigSecLevel" SG_ 1552 ICC_VehiMod "null";
BA_ "sigConfig" SG_ 1552 ICC_EgyCnseStcClrFlg "null";
BA_ "sigExplanation" SG_ 1552 ICC_EgyCnseStcClrFlg "null";
BA_ "sigSecLevel" SG_ 1552 ICC_EgyCnseStcClrFlg "null";
BA_ "sigConfig" SG_ 1552 ICC_PollingFctOpenSts "null";
BA_ "sigExplanation" SG_ 1552 ICC_PollingFctOpenSts "null";
BA_ "sigSecLevel" SG_ 1552 ICC_PollingFctOpenSts "null";
BA_ "sigConfig" SG_ 1552 ICC_KickFctOpenSts "null";
BA_ "sigExplanation" SG_ 1552 ICC_KickFctOpenSts "null";
BA_ "sigSecLevel" SG_ 1552 ICC_KickFctOpenSts "null";
BA_ "sigConfig" SG_ 1552 ICC_UsrSetChrgGunAntithft "null";
BA_ "sigExplanation" SG_ 1552 ICC_UsrSetChrgGunAntithft "null";
BA_ "sigSecLevel" SG_ 1552 ICC_UsrSetChrgGunAntithft "null";
BA_ "sigConfig" SG_ 1552 ICC_ChrgInsulFctReq "null";
BA_ "sigExplanation" SG_ 1552 ICC_ChrgInsulFctReq "null";
BA_ "sigSecLevel" SG_ 1552 ICC_ChrgInsulFctReq "null";
BA_ "sigConfig" SG_ 1552 ICC_StopChrgBtn "null";
BA_ "sigExplanation" SG_ 1552 ICC_StopChrgBtn "null";
BA_ "sigSecLevel" SG_ 1552 ICC_StopChrgBtn "null";
BA_ "GenSigSendType" SG_ 1552 ICC_DrvModSig 4;
BA_ "sigConfig" SG_ 1552 ICC_DrvModSig "null";
BA_ "sigExplanation" SG_ 1552 ICC_DrvModSig "null";
BA_ "sigSecLevel" SG_ 1552 ICC_DrvModSig "null";
BA_ "sigConfig" SG_ 1552 ICC_SetACChrgLmtCrt "null";
BA_ "sigExplanation" SG_ 1552 ICC_SetACChrgLmtCrt "null";
BA_ "sigSecLevel" SG_ 1552 ICC_SetACChrgLmtCrt "null";
BA_ "sigConfig" SG_ 1552 ICC_SetTrvlMod "null";
BA_ "sigExplanation" SG_ 1552 ICC_SetTrvlMod "null";
BA_ "sigSecLevel" SG_ 1552 ICC_SetTrvlMod "null";
BA_ "GenSigSendType" SG_ 1552 ICC_RegenLvl 4;
BA_ "sigConfig" SG_ 1552 ICC_RegenLvl "null";
BA_ "sigExplanation" SG_ 1552 ICC_RegenLvl "null";
BA_ "sigSecLevel" SG_ 1552 ICC_RegenLvl "null";
BA_ "GenSigStartValue" SG_ 1552 ICC_SetChrgEndSOC 127;
BA_ "sigConfig" SG_ 1552 ICC_SetChrgEndSOC "null";
BA_ "sigExplanation" SG_ 1552 ICC_SetChrgEndSOC "null";
BA_ "sigSecLevel" SG_ 1552 ICC_SetChrgEndSOC "null";
BA_ "sigConfig" SG_ 1552 ICC_StartChrgBtn "null";
BA_ "sigExplanation" SG_ 1552 ICC_StartChrgBtn "null";
BA_ "sigSecLevel" SG_ 1552 ICC_StartChrgBtn "null";
BA_ "sigConfig" SG_ 1558 VCU_PwrAntitheftAuthentLrngSts "null";
BA_ "sigExplanation" SG_ 1558 VCU_PwrAntitheftAuthentLrngSts "null";
BA_ "sigSecLevel" SG_ 1558 VCU_PwrAntitheftAuthentLrngSts "null";
BA_ "sigConfig" SG_ 1558 VCU_PwrAntitheftErrTyp "null";
BA_ "sigExplanation" SG_ 1558 VCU_PwrAntitheftErrTyp "null";
BA_ "sigSecLevel" SG_ 1558 VCU_PwrAntitheftErrTyp "null";
BA_ "sigConfig" SG_ 1558 VCU_FreestartMod "null";
BA_ "sigExplanation" SG_ 1558 VCU_FreestartMod "null";
BA_ "sigSecLevel" SG_ 1558 VCU_FreestartMod "null";
BA_ "sigConfig" SG_ 1558 VCU_DataPartVers "null";
BA_ "sigExplanation" SG_ 1558 VCU_DataPartVers "null";
BA_ "sigSecLevel" SG_ 1558 VCU_DataPartVers "null";
BA_ "sigConfig" SG_ 1558 VCU_CalSwVersM "null";
BA_ "sigExplanation" SG_ 1558 VCU_CalSwVersM "null";
BA_ "sigSecLevel" SG_ 1558 VCU_CalSwVersM "null";
BA_ "sigConfig" SG_ 1558 VCU_CalSwVersS "null";
BA_ "sigExplanation" SG_ 1558 VCU_CalSwVersS "null";
BA_ "sigSecLevel" SG_ 1558 VCU_CalSwVersS "null";
BA_ "sigConfig" SG_ 1559 VCU_E2PROMAPICallFlt "null";
BA_ "sigExplanation" SG_ 1559 VCU_E2PROMAPICallFlt "null";
BA_ "sigSecLevel" SG_ 1559 VCU_E2PROMAPICallFlt "null";
BA_ "sigConfig" SG_ 1559 VCU_E2PROMReadFlt "null";
BA_ "sigExplanation" SG_ 1559 VCU_E2PROMReadFlt "null";
BA_ "sigSecLevel" SG_ 1559 VCU_E2PROMReadFlt "null";
BA_ "sigConfig" SG_ 1559 VCU_E2PROMWrFlt "null";
BA_ "sigExplanation" SG_ 1559 VCU_E2PROMWrFlt "null";
BA_ "sigSecLevel" SG_ 1559 VCU_E2PROMWrFlt "null";
BA_ "sigConfig" SG_ 1559 VCU_TMonFlt "null";
BA_ "sigExplanation" SG_ 1559 VCU_TMonFlt "null";
BA_ "sigSecLevel" SG_ 1559 VCU_TMonFlt "null";
BA_ "sigConfig" SG_ 1559 VCU_EVCANBusFlt "null";
BA_ "sigExplanation" SG_ 1559 VCU_EVCANBusFlt "null";
BA_ "sigSecLevel" SG_ 1559 VCU_EVCANBusFlt "null";
BA_ "sigConfig" SG_ 1559 VCU_CCANBusFlt "null";
BA_ "sigExplanation" SG_ 1559 VCU_CCANBusFlt "null";
BA_ "sigSecLevel" SG_ 1559 VCU_CCANBusFlt "null";
BA_ "sigConfig" SG_ 1559 VCU_BREAKCANBusFlt "null";
BA_ "sigExplanation" SG_ 1559 VCU_BREAKCANBusFlt "null";
BA_ "sigSecLevel" SG_ 1559 VCU_BREAKCANBusFlt "null";
BA_ "sigConfig" SG_ 1559 VCU_ATIC232ComFlt "null";
BA_ "sigExplanation" SG_ 1559 VCU_ATIC232ComFlt "null";
BA_ "sigSecLevel" SG_ 1559 VCU_ATIC232ComFlt "null";
BA_ "sigConfig" SG_ 1559 VCU_ATIC280ComFlt "null";
BA_ "sigExplanation" SG_ 1559 VCU_ATIC280ComFlt "null";
BA_ "sigSecLevel" SG_ 1559 VCU_ATIC280ComFlt "null";
BA_ "sigConfig" SG_ 1559 VCU_ATIC239LowSideOutpComFlt "null";
BA_ "sigExplanation" SG_ 1559 VCU_ATIC239LowSideOutpComFlt "null";
BA_ "sigSecLevel" SG_ 1559 VCU_ATIC239LowSideOutpComFlt "null";
BA_ "sigConfig" SG_ 1559 VCU_ATIC239VotSplyMngComFlt "null";
BA_ "sigExplanation" SG_ 1559 VCU_ATIC239VotSplyMngComFlt "null";
BA_ "sigSecLevel" SG_ 1559 VCU_ATIC239VotSplyMngComFlt "null";
BA_ "sigConfig" SG_ 1559 VCU_ATIC239UnderOverVotFlt "null";
BA_ "sigExplanation" SG_ 1559 VCU_ATIC239UnderOverVotFlt "null";
BA_ "sigSecLevel" SG_ 1559 VCU_ATIC239UnderOverVotFlt "null";
BA_ "sigConfig" SG_ 1559 VCU_ADCnvrFlt "null";
BA_ "sigExplanation" SG_ 1559 VCU_ADCnvrFlt "null";
BA_ "sigSecLevel" SG_ 1559 VCU_ADCnvrFlt "null";
BA_ "sigConfig" SG_ 1559 VCU_SftyFctMonrFlt "null";
BA_ "sigExplanation" SG_ 1559 VCU_SftyFctMonrFlt "null";
BA_ "sigSecLevel" SG_ 1559 VCU_SftyFctMonrFlt "null";
BA_ "sigConfig" SG_ 1559 VCU_SftyFctMonrMemFlt "null";
BA_ "sigExplanation" SG_ 1559 VCU_SftyFctMonrMemFlt "null";
BA_ "sigSecLevel" SG_ 1559 VCU_SftyFctMonrMemFlt "null";
BA_ "sigConfig" SG_ 1559 VCU_LVbattCtrlSigOpenFlt "null";
BA_ "sigExplanation" SG_ 1559 VCU_LVbattCtrlSigOpenFlt "null";
BA_ "sigSecLevel" SG_ 1559 VCU_LVbattCtrlSigOpenFlt "null";
BA_ "sigConfig" SG_ 1559 VCU_LVbattCtrlSigSTBFlt "null";
BA_ "sigExplanation" SG_ 1559 VCU_LVbattCtrlSigSTBFlt "null";
BA_ "sigSecLevel" SG_ 1559 VCU_LVbattCtrlSigSTBFlt "null";
BA_ "sigConfig" SG_ 1559 VCU_LVbattCtrlSigSTGFlt "null";
BA_ "sigExplanation" SG_ 1559 VCU_LVbattCtrlSigSTGFlt "null";
BA_ "sigSecLevel" SG_ 1559 VCU_LVbattCtrlSigSTGFlt "null";
BA_ "sigConfig" SG_ 1559 VCU_BMSWakeUpSigOpenFlt "null";
BA_ "sigExplanation" SG_ 1559 VCU_BMSWakeUpSigOpenFlt "null";
BA_ "sigSecLevel" SG_ 1559 VCU_BMSWakeUpSigOpenFlt "null";
BA_ "sigConfig" SG_ 1559 VCU_BMSWakeUpSigSTBFlt "null";
BA_ "sigExplanation" SG_ 1559 VCU_BMSWakeUpSigSTBFlt "null";
BA_ "sigSecLevel" SG_ 1559 VCU_BMSWakeUpSigSTBFlt "null";
BA_ "sigConfig" SG_ 1559 VCU_BMSWakeUpSigSTGFlt "null";
BA_ "sigExplanation" SG_ 1559 VCU_BMSWakeUpSigSTGFlt "null";
BA_ "sigSecLevel" SG_ 1559 VCU_BMSWakeUpSigSTGFlt "null";
BA_ "sigConfig" SG_ 1559 VCU_PDUWakeUpSigSTBFlt "null";
BA_ "sigExplanation" SG_ 1559 VCU_PDUWakeUpSigSTBFlt "null";
BA_ "sigSecLevel" SG_ 1559 VCU_PDUWakeUpSigSTBFlt "null";
BA_ "sigConfig" SG_ 1559 VCU_PDUWakeUpSigOpenFlt "null";
BA_ "sigExplanation" SG_ 1559 VCU_PDUWakeUpSigOpenFlt "null";
BA_ "sigSecLevel" SG_ 1559 VCU_PDUWakeUpSigOpenFlt "null";
BA_ "sigConfig" SG_ 1559 VCU_PDUWakeUpSigSTGFlt "null";
BA_ "sigExplanation" SG_ 1559 VCU_PDUWakeUpSigSTGFlt "null";
BA_ "sigSecLevel" SG_ 1559 VCU_PDUWakeUpSigSTGFlt "null";
BA_ "sigConfig" SG_ 1559 VCU_CCUCMUWakeUpSigOpenFlt "null";
BA_ "sigExplanation" SG_ 1559 VCU_CCUCMUWakeUpSigOpenFlt "null";
BA_ "sigSecLevel" SG_ 1559 VCU_CCUCMUWakeUpSigOpenFlt "null";
BA_ "sigConfig" SG_ 1559 VCU_CCUCMUWakeUpSigSTBFlt "null";
BA_ "sigExplanation" SG_ 1559 VCU_CCUCMUWakeUpSigSTBFlt "null";
BA_ "sigSecLevel" SG_ 1559 VCU_CCUCMUWakeUpSigSTBFlt "null";
BA_ "sigConfig" SG_ 1559 VCU_CCUCMUWakeUpSigSTGFlt "null";
BA_ "sigExplanation" SG_ 1559 VCU_CCUCMUWakeUpSigSTGFlt "null";
BA_ "sigSecLevel" SG_ 1559 VCU_CCUCMUWakeUpSigSTGFlt "null";
BA_ "sigConfig" SG_ 1559 VCU_MCUWakeUpSigOpenFlt "null";
BA_ "sigExplanation" SG_ 1559 VCU_MCUWakeUpSigOpenFlt "null";
BA_ "sigSecLevel" SG_ 1559 VCU_MCUWakeUpSigOpenFlt "null";
BA_ "sigConfig" SG_ 1559 VCU_MCUWakeUpSigSTBFlt "null";
BA_ "sigExplanation" SG_ 1559 VCU_MCUWakeUpSigSTBFlt "null";
BA_ "sigSecLevel" SG_ 1559 VCU_MCUWakeUpSigSTBFlt "null";
BA_ "sigConfig" SG_ 1559 VCU_MCUWakeUpSigSTGFlt "null";
BA_ "sigExplanation" SG_ 1559 VCU_MCUWakeUpSigSTGFlt "null";
BA_ "sigSecLevel" SG_ 1559 VCU_MCUWakeUpSigSTGFlt "null";
BA_ "sigConfig" SG_ 1559 VCU_ComLostFlt_CCU "null";
BA_ "sigExplanation" SG_ 1559 VCU_ComLostFlt_CCU "null";
BA_ "sigSecLevel" SG_ 1559 VCU_ComLostFlt_CCU "null";
BA_ "GenSigSendType" SG_ 1562 TBOX_RemDTCDmd 5;
BA_ "sigConfig" SG_ 1562 TBOX_RemDTCDmd "null";
BA_ "sigExplanation" SG_ 1562 TBOX_RemDTCDmd "null";
BA_ "sigSecLevel" SG_ 1562 TBOX_RemDTCDmd "null";
BA_ "GenSigStartValue" SG_ 1583 TBOX_ZoneT 48;
BA_ "sigConfig" SG_ 1583 TBOX_CrtTi_Day "null";
BA_ "sigExplanation" SG_ 1583 TBOX_CrtTi_Day "null";
BA_ "sigSecLevel" SG_ 1583 TBOX_CrtTi_Day "null";
BA_ "sigConfig" SG_ 1583 TBOX_CrtTi_Hr "null";
BA_ "sigExplanation" SG_ 1583 TBOX_CrtTi_Hr "null";
BA_ "sigSecLevel" SG_ 1583 TBOX_CrtTi_Hr "null";
BA_ "sigConfig" SG_ 1583 TBOX_CrtTi_Mins "null";
BA_ "sigExplanation" SG_ 1583 TBOX_CrtTi_Mins "null";
BA_ "sigSecLevel" SG_ 1583 TBOX_CrtTi_Mins "null";
BA_ "sigConfig" SG_ 1583 TBOX_CrtTi_Yr "null";
BA_ "sigExplanation" SG_ 1583 TBOX_CrtTi_Yr "null";
BA_ "sigSecLevel" SG_ 1583 TBOX_CrtTi_Yr "null";
BA_ "sigConfig" SG_ 1583 TBOX_CrtTi_Mth "null";
BA_ "sigExplanation" SG_ 1583 TBOX_CrtTi_Mth "null";
BA_ "sigSecLevel" SG_ 1583 TBOX_CrtTi_Mth "null";
BA_ "sigConfig" SG_ 1583 TBOX_CrtTi_Sec "null";
BA_ "sigExplanation" SG_ 1583 TBOX_CrtTi_Sec "null";
BA_ "sigSecLevel" SG_ 1583 TBOX_CrtTi_Sec "null";
BA_ "sigConfig" SG_ 1584 VCU_CellTotVolt "null";
BA_ "sigExplanation" SG_ 1584 VCU_CellTotVolt "null";
BA_ "sigSecLevel" SG_ 1584 VCU_CellTotVolt "null";
BA_ "sigConfig" SG_ 1584 VCU_CellMinVolt "null";
BA_ "sigExplanation" SG_ 1584 VCU_CellMinVolt "null";
BA_ "sigSecLevel" SG_ 1584 VCU_CellMinVolt "null";
BA_ "sigConfig" SG_ 1584 VCU_CellMaxVolt "null";
BA_ "sigExplanation" SG_ 1584 VCU_CellMaxVolt "null";
BA_ "sigSecLevel" SG_ 1584 VCU_CellMaxVolt "null";
BA_ "sigConfig" SG_ 1588 VCU_ACChrgShttrSts "null";
BA_ "sigExplanation" SG_ 1588 VCU_ACChrgShttrSts "null";
BA_ "sigSecLevel" SG_ 1588 VCU_ACChrgShttrSts "null";
BA_ "sigConfig" SG_ 1588 VCU_DCChrgShttrSts "null";
BA_ "sigExplanation" SG_ 1588 VCU_DCChrgShttrSts "null";
BA_ "sigSecLevel" SG_ 1588 VCU_DCChrgShttrSts "null";
BA_ "sigConfig" SG_ 1588 VCU_SCPwrSplyEquipFactry "null";
BA_ "sigExplanation" SG_ 1588 VCU_SCPwrSplyEquipFactry "null";
BA_ "sigSecLevel" SG_ 1588 VCU_SCPwrSplyEquipFactry "null";
BA_ "sigConfig" SG_ 1588 VCU_ACChrgCrtUpprLmt "null";
BA_ "sigExplanation" SG_ 1588 VCU_ACChrgCrtUpprLmt "null";
BA_ "sigSecLevel" SG_ 1588 VCU_ACChrgCrtUpprLmt "null";
BA_ "sigConfig" SG_ 1594 BMS_Splr "null";
BA_ "sigExplanation" SG_ 1594 BMS_Splr "null";
BA_ "sigSecLevel" SG_ 1594 BMS_Splr "null";
BA_ "sigConfig" SG_ 1594 BMS_PwrBattTyp "null";
BA_ "sigExplanation" SG_ 1594 BMS_PwrBattTyp "null";
BA_ "sigSecLevel" SG_ 1594 BMS_PwrBattTyp "null";
BA_ "sigConfig" SG_ 1594 BMS_PwrBattPwrStsSOH "null";
BA_ "sigExplanation" SG_ 1594 BMS_PwrBattPwrStsSOH "null";
BA_ "sigSecLevel" SG_ 1594 BMS_PwrBattPwrStsSOH "null";
BA_ "sigConfig" SG_ 1594 BMS_PwrBattPackSerlNr "null";
BA_ "sigExplanation" SG_ 1594 BMS_PwrBattPackSerlNr "null";
BA_ "sigSecLevel" SG_ 1594 BMS_PwrBattPackSerlNr "null";
BA_ "sigConfig" SG_ 1594 BMS_PwrBattPackPrllNr "null";
BA_ "sigExplanation" SG_ 1594 BMS_PwrBattPackPrllNr "null";
BA_ "sigSecLevel" SG_ 1594 BMS_PwrBattPackPrllNr "null";
BA_ "sigConfig" SG_ 1594 BMS_CellCp "null";
BA_ "sigExplanation" SG_ 1594 BMS_CellCp "null";
BA_ "sigSecLevel" SG_ 1594 BMS_CellCp "null";
BA_ "sigConfig" SG_ 1594 BMS_DchaEndCellVolt "null";
BA_ "sigExplanation" SG_ 1594 BMS_DchaEndCellVolt "null";
BA_ "sigSecLevel" SG_ 1594 BMS_DchaEndCellVolt "null";
BA_ "sigConfig" SG_ 1604 ECC_644_CheckSum "null";
BA_ "sigExplanation" SG_ 1604 ECC_644_CheckSum "null";
BA_ "sigSecLevel" SG_ 1604 ECC_644_CheckSum "null";
BA_ "sigConfig" SG_ 1604 ECC_644_AliveCounter "null";
BA_ "sigExplanation" SG_ 1604 ECC_644_AliveCounter "null";
BA_ "sigSecLevel" SG_ 1604 ECC_644_AliveCounter "null";
BA_ "GenSigStartValue" SG_ 1604 ECC_ReMotOutlT 48;
BA_ "sigConfig" SG_ 1604 ECC_ReMotOutlT "null";
BA_ "sigExplanation" SG_ 1604 ECC_ReMotOutlT "null";
BA_ "sigSecLevel" SG_ 1604 ECC_ReMotOutlT "null";
BA_ "sigConfig" SG_ 1604 ECC_CoolgDfct "null";
BA_ "sigExplanation" SG_ 1604 ECC_CoolgDfct "null";
BA_ "sigSecLevel" SG_ 1604 ECC_CoolgDfct "null";
BA_ "sigConfig" SG_ 1604 ECC_CooltHomSts "null";
BA_ "sigExplanation" SG_ 1604 ECC_CooltHomSts "null";
BA_ "sigSecLevel" SG_ 1604 ECC_CooltHomSts "null";
BA_ "GenSigStartValue" SG_ 1604 ECC_PDUInlT 48;
BA_ "sigConfig" SG_ 1604 ECC_PDUInlT "null";
BA_ "sigExplanation" SG_ 1604 ECC_PDUInlT "null";
BA_ "sigSecLevel" SG_ 1604 ECC_PDUInlT "null";
BA_ "GenSigStartValue" SG_ 1604 ECC_FrntMotOutlT 48;
BA_ "sigConfig" SG_ 1604 ECC_FrntMotOutlT "null";
BA_ "sigExplanation" SG_ 1604 ECC_FrntMotOutlT "null";
BA_ "sigSecLevel" SG_ 1604 ECC_FrntMotOutlT "null";
BA_ "GenSigStartValue" SG_ 1604 ECC_MCURInlT 48;
BA_ "sigConfig" SG_ 1604 ECC_MCURInlT "null";
BA_ "sigExplanation" SG_ 1604 ECC_MCURInlT "null";
BA_ "sigSecLevel" SG_ 1604 ECC_MCURInlT "null";
BA_ "sigConfig" SG_ 1605 ECC_DefrstAirOutlTSnsrFlt "null";
BA_ "sigExplanation" SG_ 1605 ECC_DefrstAirOutlTSnsrFlt "null";
BA_ "sigSecLevel" SG_ 1605 ECC_DefrstAirOutlTSnsrFlt "null";
BA_ "sigConfig" SG_ 1605 ECC_ComLost_EAS "null";
BA_ "sigExplanation" SG_ 1605 ECC_ComLost_EAS "null";
BA_ "sigSecLevel" SG_ 1605 ECC_ComLost_EAS "null";
BA_ "sigConfig" SG_ 1605 ECC_OutdTSnsrFlt "null";
BA_ "sigExplanation" SG_ 1605 ECC_OutdTSnsrFlt "null";
BA_ "sigSecLevel" SG_ 1605 ECC_OutdTSnsrFlt "null";
BA_ "sigConfig" SG_ 1605 ECC_InsdTSnsrFlt "null";
BA_ "sigExplanation" SG_ 1605 ECC_InsdTSnsrFlt "null";
BA_ "sigSecLevel" SG_ 1605 ECC_InsdTSnsrFlt "null";
BA_ "sigConfig" SG_ 1605 ECC_EvaprTSnsrFlt "null";
BA_ "sigExplanation" SG_ 1605 ECC_EvaprTSnsrFlt "null";
BA_ "sigSecLevel" SG_ 1605 ECC_EvaprTSnsrFlt "null";
BA_ "sigConfig" SG_ 1605 ECC_IntExtCircMotFlt "null";
BA_ "sigExplanation" SG_ 1605 ECC_IntExtCircMotFlt "null";
BA_ "sigSecLevel" SG_ 1605 ECC_IntExtCircMotFlt "null";
BA_ "sigConfig" SG_ 1605 ECC_LeModThrMotFlt "null";
BA_ "sigExplanation" SG_ 1605 ECC_LeModThrMotFlt "null";
BA_ "sigSecLevel" SG_ 1605 ECC_LeModThrMotFlt "null";
BA_ "sigConfig" SG_ 1605 ECC_RiModThrMotFlt "null";
BA_ "sigExplanation" SG_ 1605 ECC_RiModThrMotFlt "null";
BA_ "sigSecLevel" SG_ 1605 ECC_RiModThrMotFlt "null";
BA_ "sigConfig" SG_ 1605 ECC_CtrlrFlt "null";
BA_ "sigExplanation" SG_ 1605 ECC_CtrlrFlt "null";
BA_ "sigSecLevel" SG_ 1605 ECC_CtrlrFlt "null";
BA_ "sigConfig" SG_ 1605 ECC_PDUInlTSnsrFlt "null";
BA_ "sigExplanation" SG_ 1605 ECC_PDUInlTSnsrFlt "null";
BA_ "sigSecLevel" SG_ 1605 ECC_PDUInlTSnsrFlt "null";
BA_ "sigConfig" SG_ 1605 ECC_FrntMotOutlTSnsrFlt "null";
BA_ "sigExplanation" SG_ 1605 ECC_FrntMotOutlTSnsrFlt "null";
BA_ "sigSecLevel" SG_ 1605 ECC_FrntMotOutlTSnsrFlt "null";
BA_ "sigConfig" SG_ 1605 ECC_ReMotOutlTSnsrFlt "null";
BA_ "sigExplanation" SG_ 1605 ECC_ReMotOutlTSnsrFlt "null";
BA_ "sigSecLevel" SG_ 1605 ECC_ReMotOutlTSnsrFlt "null";
BA_ "sigConfig" SG_ 1605 ECC_ComLost_CDS "null";
BA_ "sigExplanation" SG_ 1605 ECC_ComLost_CDS "null";
BA_ "sigSecLevel" SG_ 1605 ECC_ComLost_CDS "null";
BA_ "sigConfig" SG_ 1605 ECC_ComLost_WTC_H "null";
BA_ "sigExplanation" SG_ 1605 ECC_ComLost_WTC_H "null";
BA_ "sigSecLevel" SG_ 1605 ECC_ComLost_WTC_H "null";
BA_ "sigConfig" SG_ 1605 ECC_ComLost_WTC_B "null";
BA_ "sigExplanation" SG_ 1605 ECC_ComLost_WTC_B "null";
BA_ "sigSecLevel" SG_ 1605 ECC_ComLost_WTC_B "null";
BA_ "sigConfig" SG_ 1605 ECC_HPTSnsrFlt "null";
BA_ "sigExplanation" SG_ 1605 ECC_HPTSnsrFlt "null";
BA_ "sigSecLevel" SG_ 1605 ECC_HPTSnsrFlt "null";
BA_ "sigConfig" SG_ 1605 ECC_LPTSnsrFlt "null";
BA_ "sigExplanation" SG_ 1605 ECC_LPTSnsrFlt "null";
BA_ "sigSecLevel" SG_ 1605 ECC_LPTSnsrFlt "null";
BA_ "sigConfig" SG_ 1605 ECC_BlowFaceLeAirOutlTSnsrFlt "null";
BA_ "sigExplanation" SG_ 1605 ECC_BlowFaceLeAirOutlTSnsrFlt "null";
BA_ "sigSecLevel" SG_ 1605 ECC_BlowFaceLeAirOutlTSnsrFlt "null";
BA_ "sigConfig" SG_ 1605 ECC_BlowFaceRiAirOutlTSnsrFlt "null";
BA_ "sigExplanation" SG_ 1605 ECC_BlowFaceRiAirOutlTSnsrFlt "null";
BA_ "sigSecLevel" SG_ 1605 ECC_BlowFaceRiAirOutlTSnsrFlt "null";
BA_ "sigConfig" SG_ 1605 ECC_ReBlowFaceFootMotFlt "null";
BA_ "sigExplanation" SG_ 1605 ECC_ReBlowFaceFootMotFlt "null";
BA_ "sigSecLevel" SG_ 1605 ECC_ReBlowFaceFootMotFlt "null";
BA_ "sigConfig" SG_ 1605 ECC_HPSnsrFlt "null";
BA_ "sigExplanation" SG_ 1605 ECC_HPSnsrFlt "null";
BA_ "sigSecLevel" SG_ 1605 ECC_HPSnsrFlt "null";
BA_ "sigConfig" SG_ 1605 ECC_LPSnsrFlt "null";
BA_ "sigExplanation" SG_ 1605 ECC_LPSnsrFlt "null";
BA_ "sigSecLevel" SG_ 1605 ECC_LPSnsrFlt "null";
BA_ "sigConfig" SG_ 1605 ECC_HeatPmpHeatgEXVFlt "null";
BA_ "sigExplanation" SG_ 1605 ECC_HeatPmpHeatgEXVFlt "null";
BA_ "sigSecLevel" SG_ 1605 ECC_HeatPmpHeatgEXVFlt "null";
BA_ "sigConfig" SG_ 1605 ECC_BattCoolgEXVFlt "null";
BA_ "sigExplanation" SG_ 1605 ECC_BattCoolgEXVFlt "null";
BA_ "sigSecLevel" SG_ 1605 ECC_BattCoolgEXVFlt "null";
BA_ "sigConfig" SG_ 1605 ECC_BlowFootLeAirOutlTSnsrFlt "null";
BA_ "sigExplanation" SG_ 1605 ECC_BlowFootLeAirOutlTSnsrFlt "null";
BA_ "sigSecLevel" SG_ 1605 ECC_BlowFootLeAirOutlTSnsrFlt "null";
BA_ "sigConfig" SG_ 1605 ECC_BlowFootRiAirOutlTSnsrFlt "null";
BA_ "sigExplanation" SG_ 1605 ECC_BlowFootRiAirOutlTSnsrFlt "null";
BA_ "sigSecLevel" SG_ 1605 ECC_BlowFootRiAirOutlTSnsrFlt "null";
BA_ "sigConfig" SG_ 1605 ECC_LeHybThrMotFlt "null";
BA_ "sigExplanation" SG_ 1605 ECC_LeHybThrMotFlt "null";
BA_ "sigSecLevel" SG_ 1605 ECC_LeHybThrMotFlt "null";
BA_ "sigConfig" SG_ 1605 ECC_RiHybThrMotFlt "null";
BA_ "sigExplanation" SG_ 1605 ECC_RiHybThrMotFlt "null";
BA_ "sigSecLevel" SG_ 1605 ECC_RiHybThrMotFlt "null";
BA_ "sigConfig" SG_ 1605 ECC_MCURInlTSnsrFlt "null";
BA_ "sigExplanation" SG_ 1605 ECC_MCURInlTSnsrFlt "null";
BA_ "sigSecLevel" SG_ 1605 ECC_MCURInlTSnsrFlt "null";
BA_ "sigConfig" SG_ 1605 ECC_ComLost_EWP_FD "null";
BA_ "sigExplanation" SG_ 1605 ECC_ComLost_EWP_FD "null";
BA_ "sigSecLevel" SG_ 1605 ECC_ComLost_EWP_FD "null";
BA_ "sigConfig" SG_ 1605 ECC_ComLost_EWP_RD "null";
BA_ "sigExplanation" SG_ 1605 ECC_ComLost_EWP_RD "null";
BA_ "sigSecLevel" SG_ 1605 ECC_ComLost_EWP_RD "null";
BA_ "sigConfig" SG_ 1605 ECC_ComLost_EWP_H "null";
BA_ "sigExplanation" SG_ 1605 ECC_ComLost_EWP_H "null";
BA_ "sigSecLevel" SG_ 1605 ECC_ComLost_EWP_H "null";
BA_ "sigConfig" SG_ 1605 ECC_ComLost_EWP_B "null";
BA_ "sigExplanation" SG_ 1605 ECC_ComLost_EWP_B "null";
BA_ "sigSecLevel" SG_ 1605 ECC_ComLost_EWP_B "null";
BA_ "sigConfig" SG_ 1605 ECC_ComLost_EXV_B "null";
BA_ "sigExplanation" SG_ 1605 ECC_ComLost_EXV_B "null";
BA_ "sigSecLevel" SG_ 1605 ECC_ComLost_EXV_B "null";
BA_ "sigConfig" SG_ 1605 ECC_ComLost_EXV_H "null";
BA_ "sigExplanation" SG_ 1605 ECC_ComLost_EXV_H "null";
BA_ "sigSecLevel" SG_ 1605 ECC_ComLost_EXV_H "null";
BA_ "sigConfig" SG_ 1605 ECC_ComLost_CFM "null";
BA_ "sigExplanation" SG_ 1605 ECC_ComLost_CFM "null";
BA_ "sigSecLevel" SG_ 1605 ECC_ComLost_CFM "null";
BA_ "sigConfig" SG_ 1605 ECC_ComLost_AGS "null";
BA_ "sigExplanation" SG_ 1605 ECC_ComLost_AGS "null";
BA_ "sigSecLevel" SG_ 1605 ECC_ComLost_AGS "null";
BA_ "sigConfig" SG_ 1605 ECC_ComLost_CVM "null";
BA_ "sigExplanation" SG_ 1605 ECC_ComLost_CVM "null";
BA_ "sigSecLevel" SG_ 1605 ECC_ComLost_CVM "null";
BA_ "sigConfig" SG_ 1605 ECC_ComLost_MDV "null";
BA_ "sigExplanation" SG_ 1605 ECC_ComLost_MDV "null";
BA_ "sigSecLevel" SG_ 1605 ECC_ComLost_MDV "null";
BA_ "sigConfig" SG_ 1616 VCU_PartVers "null";
BA_ "sigExplanation" SG_ 1616 VCU_PartVers "null";
BA_ "sigSecLevel" SG_ 1616 VCU_PartVers "null";
BA_ "sigConfig" SG_ 1616 VCU_SwVersPatch "null";
BA_ "sigExplanation" SG_ 1616 VCU_SwVersPatch "null";
BA_ "sigSecLevel" SG_ 1616 VCU_SwVersPatch "null";
BA_ "sigConfig" SG_ 1616 VCU_HwVers "null";
BA_ "sigExplanation" SG_ 1616 VCU_HwVers "null";
BA_ "sigSecLevel" SG_ 1616 VCU_HwVers "null";
BA_ "sigConfig" SG_ 1616 VCU_SwVersMain "null";
BA_ "sigExplanation" SG_ 1616 VCU_SwVersMain "null";
BA_ "sigSecLevel" SG_ 1616 VCU_SwVersMain "null";
BA_ "sigConfig" SG_ 1616 VCU_SwVersMinor "null";
BA_ "sigExplanation" SG_ 1616 VCU_SwVersMinor "null";
BA_ "sigSecLevel" SG_ 1616 VCU_SwVersMinor "null";
BA_ "sigConfig" SG_ 1618 BMS_SwVers "null";
BA_ "sigExplanation" SG_ 1618 BMS_SwVers "null";
BA_ "sigSecLevel" SG_ 1618 BMS_SwVers "null";
BA_ "sigConfig" SG_ 1618 BMS_SwVersS "null";
BA_ "sigExplanation" SG_ 1618 BMS_SwVersS "null";
BA_ "sigSecLevel" SG_ 1618 BMS_SwVersS "null";
BA_ "sigConfig" SG_ 1618 BMS_PartVers "null";
BA_ "sigExplanation" SG_ 1618 BMS_PartVers "null";
BA_ "sigSecLevel" SG_ 1618 BMS_PartVers "null";
BA_ "sigConfig" SG_ 1618 BMS_HwVers "null";
BA_ "sigExplanation" SG_ 1618 BMS_HwVers "null";
BA_ "sigSecLevel" SG_ 1618 BMS_HwVers "null";
BA_ "sigConfig" SG_ 1618 BMS_SwVersM "null";
BA_ "sigExplanation" SG_ 1618 BMS_SwVersM "null";
BA_ "sigSecLevel" SG_ 1618 BMS_SwVersM "null";
VAL_ 1328 ICC_DrvrTSet 0 "Inactive" 1 "Low" 2 "Low" 3 "Low" 4 "Low" 5 "Low" 6 "Low" 7 "Low" 8 "Low" 9 "Low" 10 "Low" 11 "Low" 12 "Low" 13 "Low" 14 "Low" 15 "Low" 16 "Low" 17 "Low" 18 "Low" 19 "Low" 20 "Low" 21 "Low" 22 "Low" 23 "Low" 24 "Low" 25 "Low" 26 "Low" 27 "Low" 28 "Low" 29 "Low" 30 "Low" 31 "Low" 32 "Low" 33 "Low" 34 "Low" 35 "Low" 36 "18¡æ" 37 "18.5¡æ" 38 "19¡æ" 39 "19.5¡æ" 40 "20¡æ" 41 "20.5¡æ" 42 "21¡æ" 43 "21.5¡æ" 44 "22¡æ" 45 "22.5¡æ" 46 "23¡æ" 47 "23.5¡æ" 48 "24¡æ" 49 "24.5¡æ" 50 "25¡æ" 51 "25.5¡æ" 52 "26¡æ" 53 "26.5¡æ" 54 "27¡æ" 55 "27.5¡æ" 56 "28¡æ" 57 "28.5¡æ" 58 "29¡æ" 59 "29.5¡æ" 60 "30¡æ" 61 "30.5¡æ" 62 "31¡æ" 63 "31.5¡æ" 64 "32¡æ" 65 "High" 66 "High" 67 "High" 68 "High" 69 "High" 70 "High" 71 "High" 72 "High" 73 "High" 74 "High" 75 "High" 76 "High" 77 "High" 78 "High" 79 "High" 80 "High" 81 "High" 82 "High" 83 "High" 84 "High" 85 "High" 86 "High" 87 "High" 88 "High" 89 "High" 90 "High" 91 "High" 92 "High" 93 "High" 94 "High" 95 "High" 96 "High" 97 "High" 98 "High" 99 "High" 100 "High" 101 "High" 102 "High" 103 "High" 104 "High" 105 "High" 106 "High" 107 "High" 108 "High" 109 "High" 110 "High" 111 "High" 112 "High" 113 "High" 114 "High" 115 "High" 116 "High" 117 "High" 118 "High" 119 "High" 120 "High" 121 "High" 122 "High" 123 "High" 124 "High" 125 "High" 126 "High" 127 "High" 128 "High" 129 "High" 130 "High" 131 "High" 132 "High" 133 "High" 134 "High" 135 "High" 136 "High" 137 "High" 138 "High" 139 "High" 140 "High" 141 "High" 142 "High" 143 "High" 144 "High" 145 "High" 146 "High" 147 "High" 148 "High" 149 "High" 150 "High" 151 "High" 152 "High" 153 "High" 154 "High" 155 "High" 156 "High" 157 "High" 158 "High" 159 "High" 160 "High" 161 "High" 162 "High" 163 "High" 164 "High" 165 "High" 166 "High" 167 "High" 168 "High" 169 "High" 170 "High" 171 "High" 172 "High" 173 "High" 174 "High" 175 "High" 176 "High" 177 "High" 178 "High" 179 "High" 180 "High" 181 "High" 182 "High" 183 "High" 184 "High" 185 "High" 186 "High" 187 "High" 188 "High" 189 "High" 190 "High" 191 "High" 192 "High" 193 "High" 194 "High" 195 "High" 196 "High" 197 "High" 198 "High" 199 "High" 200 "High" 201 "High" 202 "High" 203 "High" 204 "High" 205 "High" 206 "High" 207 "High" 208 "High" 209 "High" 210 "High" 211 "High" 212 "High" 213 "High" 214 "High" 215 "High" 216 "High" 217 "High" 218 "High" 219 "High" 220 "High" 221 "High" 222 "High" 223 "High" 224 "High" 225 "High" 226 "High" 227 "High" 228 "High" 229 "High" 230 "High" 231 "High" 232 "High" 233 "High" 234 "High" 235 "High" 236 "High" 237 "High" 238 "High" 239 "High" 240 "High" 241 "High" 242 "High" 243 "High" 244 "High" 245 "High" 246 "High" 247 "High" 248 "High" 249 "High" 250 "High" 251 "High" 252 "High" 253 "High" 254 "High" 255 "Invalid" ;
VAL_ 1328 ICC_PassTSet 0 "Inactive" 1 "Low" 2 "Low" 3 "Low" 4 "Low" 5 "Low" 6 "Low" 7 "Low" 8 "Low" 9 "Low" 10 "Low" 11 "Low" 12 "Low" 13 "Low" 14 "Low" 15 "Low" 16 "Low" 17 "Low" 18 "Low" 19 "Low" 20 "Low" 21 "Low" 22 "Low" 23 "Low" 24 "Low" 25 "Low" 26 "Low" 27 "Low" 28 "Low" 29 "Low" 30 "Low" 31 "Low" 32 "Low" 33 "Low" 34 "Low" 35 "Low" 36 "18¡æ" 37 "18.5¡æ" 38 "19¡æ" 39 "19.5¡æ" 40 "20¡æ" 41 "20.5¡æ" 42 "21¡æ" 43 "21.5¡æ" 44 "22¡æ" 45 "22.5¡æ" 46 "23¡æ" 47 "23.5¡æ" 48 "24¡æ" 49 "24.5¡æ" 50 "25¡æ" 51 "25.5¡æ" 52 "26¡æ" 53 "26.5¡æ" 54 "27¡æ" 55 "27.5¡æ" 56 "28¡æ" 57 "28.5¡æ" 58 "29¡æ" 59 "29.5¡æ" 60 "30¡æ" 61 "30.5¡æ" 62 "31¡æ" 63 "31.5¡æ" 64 "32¡æ" 65 "High" 66 "High" 67 "High" 68 "High" 69 "High" 70 "High" 71 "High" 72 "High" 73 "High" 74 "High" 75 "High" 76 "High" 77 "High" 78 "High" 79 "High" 80 "High" 81 "High" 82 "High" 83 "High" 84 "High" 85 "High" 86 "High" 87 "High" 88 "High" 89 "High" 90 "High" 91 "High" 92 "High" 93 "High" 94 "High" 95 "High" 96 "High" 97 "High" 98 "High" 99 "High" 100 "High" 101 "High" 102 "High" 103 "High" 104 "High" 105 "High" 106 "High" 107 "High" 108 "High" 109 "High" 110 "High" 111 "High" 112 "High" 113 "High" 114 "High" 115 "High" 116 "High" 117 "High" 118 "High" 119 "High" 120 "High" 121 "High" 122 "High" 123 "High" 124 "High" 125 "High" 126 "High" 127 "High" 128 "High" 129 "High" 130 "High" 131 "High" 132 "High" 133 "High" 134 "High" 135 "High" 136 "High" 137 "High" 138 "High" 139 "High" 140 "High" 141 "High" 142 "High" 143 "High" 144 "High" 145 "High" 146 "High" 147 "High" 148 "High" 149 "High" 150 "High" 151 "High" 152 "High" 153 "High" 154 "High" 155 "High" 156 "High" 157 "High" 158 "High" 159 "High" 160 "High" 161 "High" 162 "High" 163 "High" 164 "High" 165 "High" 166 "High" 167 "High" 168 "High" 169 "High" 170 "High" 171 "High" 172 "High" 173 "High" 174 "High" 175 "High" 176 "High" 177 "High" 178 "High" 179 "High" 180 "High" 181 "High" 182 "High" 183 "High" 184 "High" 185 "High" 186 "High" 187 "High" 188 "High" 189 "High" 190 "High" 191 "High" 192 "High" 193 "High" 194 "High" 195 "High" 196 "High" 197 "High" 198 "High" 199 "High" 200 "High" 201 "High" 202 "High" 203 "High" 204 "High" 205 "High" 206 "High" 207 "High" 208 "High" 209 "High" 210 "High" 211 "High" 212 "High" 213 "High" 214 "High" 215 "High" 216 "High" 217 "High" 218 "High" 219 "High" 220 "High" 221 "High" 222 "High" 223 "High" 224 "High" 225 "High" 226 "High" 227 "High" 228 "High" 229 "High" 230 "High" 231 "High" 232 "High" 233 "High" 234 "High" 235 "High" 236 "High" 237 "High" 238 "High" 239 "High" 240 "High" 241 "High" 242 "High" 243 "High" 244 "High" 245 "High" 246 "High" 247 "High" 248 "High" 249 "High" 250 "High" 251 "High" 252 "High" 253 "High" 254 "High" 255 "Invalid" ;
VAL_ 1328 ICC_VSPVoiceTypSwt 0 "Sound_I" 1 "Sound_II" ;
VAL_ 1328 ICC_ECCAUTOReq 0 "Inactive" 1 "Active" ;
VAL_ 1328 ICC_DrvrSYNCReq 0 "Inactive" 1 "Active" ;
VAL_ 1328 ICC_ACSwtReq 0 "Inactive" 1 "Active" ;
VAL_ 1328 ICC_AirVolSet 0 "Inactive" 1 "First_gear_of_wind_speed" 2 "Wind_speed_second_gear" 3 "third_gear_of_wind_speed" 4 "wind_speed_fourth_gear" 5 "Wind_speed_fifth_gear" 6 "Wind_speed_six" 7 "Wind_speed_seven_gear" 8 "Reserved" 9 "Reserved" 10 "Reserved" 11 "Reserved" 12 "Reserved" 13 "Reserved" 14 "Reserved" 15 "windless_gear" ;
VAL_ 1328 ICC_ECCIntExtCircReq 0 "Inactive" 1 "Active" ;
VAL_ 1328 ICC_AirClnSwtReq 0 "Closing_request" 1 "Opening_request" ;
VAL_ 1328 ICC_MaxFrntDefrstSet 0 "No_request" 1 "Switching_request" ;
VAL_ 1328 ICC_VSPCtrlCmd 0 "Disable_disabled" 1 "Enable_Enable" ;
VAL_ 1328 ICC_NavCtryCod 255 "Invalid" ;
VAL_ 1328 ICC_NavRoadTyp 15 "Invalid" ;
VAL_ 1328 ICC_NavSpdLimUnit 0 "Unknown" 1 "MPH" 2 "KMH" 3 "Reserved" ;
VAL_ 1328 ICC_NavSpdLimSts 0 "SL_Unknown" 1 "SL_Exists" 2 "SL_Nolimit" 3 "SL_Plural" ;
VAL_ 1328 ICC_NavSpdLim 0 "No_Display" 1 "SPL_5" 2 "SPL_10" 3 "SPL_15" 4 "SPL_20" 5 "SPL_25" 26 "SPL_130" 27 "Reserved" 28 "Reserved" 29 "Reserved" 30 "Reserved" 31 "Reserved" 32 "Reserved" 33 "Reserved" 34 "Reserved" 35 "Reserved" 36 "Reserved" 37 "Reserved" 38 "Reserved" 39 "Reserved" 40 "Reserved" 41 "Reserved" 42 "Reserved" 43 "Reserved" 44 "Reserved" 45 "Reserved" 46 "Reserved" 47 "Reserved" 48 "Reserved" 49 "Reserved" 50 "Reserved" 51 "Reserved" 52 "Reserved" 53 "Reserved" 54 "Reserved" 55 "Reserved" 56 "Reserved" 57 "Reserved" 58 "Reserved" 59 "Reserved" 60 "Reserved" 61 "Reserved" 62 "Reserved" 63 "Reserved" ;
VAL_ 1328 ICC_BlowWinBtn 0 "Inactive" 1 "Pressed" ;
VAL_ 1328 ICC_NavSpdLimExitDst 255 "Invalid" ;
VAL_ 1329 ICC_TotMilgVld_ODO 0 "Value_OK" 1 "Value_Unreliable" ;
VAL_ 1329 ICC_DispVehSpdUnit 0 "KMH" 1 "MPH" ;
VAL_ 1329 ICC_ADASSigFlt 0 "No_Failure" 1 "Reversible_Failure" 2 "Irrversible_Failure" 3 "Reserved" ;
VAL_ 1329 ICC_DispFlt 0 "No_Error_No_error" 1 "Error_error" ;
VAL_ 1329 ICC_WorkshopMode 0 "Init" 1 "Active" 2 "Inactive" 3 "Invalid" ;
VAL_ 1332 ICC_MinChrgSoc_Setting 254 "Minimum_Charge_Not_Actived" 255 "Invalid" ;
VAL_ 1332 ICC_PwrBattDrvgHeatSwtSts 0 "Off_state" 1 "On_state" ;
VAL_ 1332 ICC_DrvrBlowFaceBtn 0 "Inactive" 1 "Pressed" ;
VAL_ 1332 ICC_PassBlowFacetBtn 0 "Inactive" 1 "Pressed" ;
VAL_ 1332 ICC_DrvrBlowFootBtn 0 "Inactive" 1 "Pressed" ;
VAL_ 1332 ICC_PassBlowFootBtn 0 "Inactive" 1 "Pressed" ;
VAL_ 1332 ICC_BackRowAirOutlModReq 0 "Inactive" 1 "Rear_face_blowing" 2 "Face_blowing_foot_blowing_of_rear_row" 3 "Rear_row_foot_blowing" 4 "Rear_row_cutoff" 5 "Reserved" 6 "Reserved" 7 "Reserved" ;
VAL_ 1332 ICC_DchaBtnAvlFlg 0 "Not_pressed" 1 "pressed" ;
VAL_ 1332 ICC_ECCSysSwtCmd 0 "Inactive" 1 "Air_conditioning_power_on_(Short)" 2 "Air_conditioning_shutdown_(Long)" 3 "Reserved" ;
VAL_ 1332 ICC_DrvrBlowModReq 0 "Inactive" 1 "driver_face_blowing_mode" 2 "driver_face_blowing/foot_blowing_mode" 3 "Driver_foot_blowing_mode" 4 "driver_foot/window_mode" 5 "Window_blowing_mode" 6 "Reserved" 7 "Reserved" ;
VAL_ 1332 ICC_PassBlowModReq 0 "Inactive" 1 "front_passenger_face_blowing_mode" 2 "front_passenger_face_blowing/foot_blowing_mode" 3 "Front_passenger_foot_mode" 4 "Front_passenger_foot/window_mode" 5 "Reserved" 6 "Reserved" 7 "Reserved" ;
VAL_ 1360 OBC_PDU_CrtSts 0 "OK" 1 "NOK" ;
VAL_ 1360 OBC_Pwr 0 "Other" 1 "2kw" 2 "3.3kw" 3 "6.6kw" 4 "11kw" ;
VAL_ 1360 OBC_V2L_RdySts 0 "Initial" 1 "V2L_ready" 2 "V2L_not_ready" 3 "Invalid" ;
VAL_ 1360 OBC_V2L_ActvStsFb 0 "Initial" 1 "V2L_active" 2 "V2L_Off" 3 "Failure" ;
VAL_ 1360 OBC_T 255 "Invalid" ;
VAL_ 1360 OBC_CrtSts 0 "initializing_state" 1 "Standby" 2 "Working" 3 "Ready" 4 "Fault" 5 "Sleep" 6 "Shutdown" 7 "Invalid" ;
VAL_ 1360 OBC_DCNegRlyAdhFlt 0 "Normal" 1 "Abnormal" ;
VAL_ 1360 OBC_DCPosRlyAdhFlt 0 "Normal" 1 "Abnormal" ;
VAL_ 1360 OBC_OperMod 0 "Initial" 1 "Charge" 2 "VTOL_discharge" 3 "VTOV_discharge" 4 "VTOL_Trunk_Discharge" 5 "Derating" ;
VAL_ 1360 OBC_PwrSplyHLVIntlkFlt 0 "Normal" 1 "Abnormal" ;
VAL_ 1360 OBC_ACSCIntlkSigChkCircFlt 0 "Normal" 1 "Abnormal" ;
VAL_ 1360 OBC_DCFCIntlkSigChkCircFlt 0 "Normal" 1 "Abnormal" ;
VAL_ 1360 OBC_PTCIntlkSigChkCircFlt 0 "Normal" 1 "Abnormal" ;
VAL_ 1360 OBC_PwrBattIntlkSigChkCircFlt 0 "Normal" 1 "Abnormal" ;
VAL_ 1360 OBC_EASIntlkSigChkCircFlt 0 "Normal" 1 "Abnormal" ;
VAL_ 1360 OBC_OTARdy_Fb 0 "Initial" 1 "Ready" 2 "Not_Ready" 3 "Invalid" ;
VAL_ 1363 OBC_Splr 0 "Other" 1 "Shinry" 2 "Vapel" 3 "Vmax" 4 "Evtech" 5 "ZG_Power_Supply" 6 "Stang" 7 "Sunchem" 8 "Haichen" 9 "Delta" 10 "LEAR" 11 "Valeo" 12 "Delphi" 13 "Huawei" 14 "Inovance" 15 "Reserved" ;
VAL_ 1363 OBC_ACCrtPhase1 255 "Invalid" ;
VAL_ 1363 OBC_ACCrtPhase2 255 "Invalid" ;
VAL_ 1363 OBC_ACCrtPhase3 255 "Invalid" ;
VAL_ 1363 OBC_PhaseFreq 63 "Invalid_value" ;
VAL_ 1363 OBC_EVChrgElectcLockStsFbSig 0 "Initial_value" 1 "Locked" 2 "Unlocking_state" 3 "Void" 4 "Void" 5 "Void" 6 "Void" 7 "Error" ;
VAL_ 1364 VCU_PwrGridBreakFlg 0 "Not_power_off" 1 "power_off" ;
VAL_ 1364 VCU_ACChrgDchaIndcrLampSts 0 "off" 1 "White_(illumination/half_connection)" 2 "green_(fully_connected_without_charge_and_discharge)" 3 "Green_Breath_(AC_charging)" 4 "Blue_(charging_complete)" 5 "Orange_(charging_fault)" 6 "Purple_(Discharging_process_started)" 7 "Aqua_Blue_(Discharging_process_stopped)" ;
VAL_ 1364 VCU_PrplsnEPwrReq 16383 "Invalid" ;
VAL_ 1364 VCU_VCUWakeUpSig 0 "Not_waken_up" 1 "Waken_up" ;
VAL_ 1364 VCU_DCChrgDchaIndcrLampSts 0 "off" 1 "White_(illumination/half_connection)" 2 "green_(fully_connected_without_charge_and_discharge)" 3 "Green_Breath_(DC_charging)" 4 "Blue_(charging_complete)" 5 "Orange_(charging_fault)" 6 "Purple_(Discharging_process_started)" 7 "Aqua_Blue_(Discharging_process_stopped)" ;
VAL_ 1364 VCU_HVBattActPwr 16383 "Invalid" ;
VAL_ 1365 VCU_DCChrgElectcLockDrvFlt 0 "Normal" 1 "Output_short_circuit" 2 "Short_circuit_to_GND/power_supply" 3 "Void" ;
VAL_ 1365 VCU_ACDCChrgIndcrLamp12VFlt 0 "Normal" 1 "Output_short_circuit_to_ground" 2 "Output_short_circuit_to_power_supply" 3 "Output_short_circuit" 4 "Output_overcurrent" 5 "Overheat" 6 "Void" 7 "Void" ;
VAL_ 1365 VCU_ComChkFlt_VCU 0 "Normal" 1 "Abnormal" ;
VAL_ 1365 VCU_ComChkFlt_BMS 0 "Normal" 1 "Abnormal" ;
VAL_ 1365 VCU_ComLostFlt_ICC 0 "Normal" 1 "Abnormal" ;
VAL_ 1365 VCU_ComLostFlt_PEPS 0 "Normal" 1 "Abnormal" ;
VAL_ 1365 VCU_ACChrgNTC1AndNTC2TFlt 0 "Normal" 1 "Abnormal" ;
VAL_ 1365 VCU_ComChkFlt_ESP 0 "Normal" 1 "Abnormal" ;
VAL_ 1365 VCU_ComLostFlt_OBC 0 "Normal" 1 "Abnormal" ;
VAL_ 1365 VCU_CrtSts 0 "Initial_value" 1 "Standby" 2 "Working" 3 "Reserved" 4 "Fault" 5 "Sleep" 6 "Reserved" 7 "Invalid" ;
VAL_ 1365 VCU_ACChrgTAlrmFlt 0 "Normal" 1 "Alarm" 2 "Fault" 3 "Void" ;
VAL_ 1365 VCU_DCChrgNTC1AndNTC2TFlt 0 "Normal" 1 "Abnormal" ;
VAL_ 1365 VCU_KL30OperFlt 0 "Normal" 1 "Abnormal" ;
VAL_ 1365 VCU_ACChrgElectcLockDrvFlt 0 "Normal" 1 "Output_open_circuit" 2 "Short_circuit_to_GND/power_supply" 3 "Void" ;
VAL_ 1365 VCU_ComLostFlt_VCU 0 "Normal" 1 "Abnormal" ;
VAL_ 1365 VCU_ACChrgDchaCCSigFlt 0 "Normal" 1 "Short_circuit_to_ground" 2 "Short_circuit_to_power_supply" 3 "Resistance_abnormal" ;
VAL_ 1365 VCU_ACChrgElectcUnlockFailFlt 0 "Normal" 1 "Abnormal" ;
VAL_ 1365 VCU_ACChrgElectcLockFailFlt 0 "Normal" 1 "Abnormal" ;
VAL_ 1365 VCU_DCChrgTAlrmFlt 0 "Normal" 1 "Alarm" 2 "Fault" 3 "Void" ;
VAL_ 1365 VCU_ChrgCPSigFlt 0 "Normal" 1 "Short_circuit_to_ground" 2 "Frequency_abnormal" 3 "Amplitude_abnormal" ;
VAL_ 1365 VCU_DCChrgNTC1InpFlt 0 "Normal" 1 "NTC1_short_circuit_to_GDN" 2 "NTC1_short_circuit_or_Short_circuit_to_power_supply" 3 "NTC1_open_circuit" ;
VAL_ 1365 VCU_DCChrgNTC2InpFlt 0 "NTC2_open_circuit" 1 "NTC2_short_circuit_to_GDN" 2 "NTC2_short_circuit_or_Short_circuit_to_power_supply" 3 "Reserved" ;
VAL_ 1365 VCU_ACChrgNTC1InpFlt 0 "Normal" 1 "NTC1_short_circuit_to_GDN" 2 "NTC1_short_circuit_or_Short_circuit_to_power_supply" 3 "Reserved" ;
VAL_ 1365 VCU_ACChrgNTC2InpFlt 0 "Normal" 1 "NTC2_short_circuit_to_GDN" 2 "NTC2_short_circuit_or_Short_circuit_to_power_supply" 3 "Reserved" ;
VAL_ 1365 VCU_DchgCPSigFlt 0 "Normal" 1 "Short_circuit_to_ground" 2 "Short_circuit_to_power_supply" 3 "Signal_open_circuit" 4 "Amplitude_abnormal" 5 "Frequency_duty_cycle_abnormal" 6 "Reserved" 7 "Reserved" ;
VAL_ 1365 VCU_CC2SigFlt 0 "Normal" 1 "Short_circuit_to_ground" 2 "Short_circuit_to_power_supply" 3 "Short_circuit" 4 "Voltage_abnormal" 5 "Reserved" 6 "Reserved" 7 "Reserved" ;
VAL_ 1365 VCU_ACChrgIndcrLampDrvFlt 0 "Normal" 1 "Output_short_circuit_to_ground" 2 "Output_open_circuit" 3 "Output_overcurrent" 4 "Overheat" 5 "Reserved" 6 "Reserved" 7 "Reserved" ;
VAL_ 1365 VCU_DCChrgIndcrLampDrvFlt 0 "Normal" 1 "Output_short_circuit_to_ground" 2 "Output_open_circuit" 3 "Output_overcurrent" 4 "Overheat" 5 "Reserved" 6 "Reserved" 7 "Reserved" ;
VAL_ 1365 VCU_DCChrgASigFlt 0 "Normal" 1 "Short_circuit_to_ground_or_no_power_supply" 2 "Voltage_abnormal" 3 "Reserved" ;
VAL_ 1369 OBC_InpVoltRng 0 "other" 1 "220V" 2 "110V" 3 "110V~220V" ;
VAL_ 1369 OBC_MinOutpVolt 65535 "Invalid" ;
VAL_ 1369 OBC_MaxOutpVolt 65535 "Invalid" ;
VAL_ 1369 OBC_DCChrggEvseInlVolt 65535 "Invalid" ;
VAL_ 1370 OBC_HVDCOutpOverCrtSwFlt 0 "Normal" 1 "Abnormal" ;
VAL_ 1370 OBC_HVDCOutpOverCrtHwFlt 0 "Normal" 1 "Abnormal" ;
VAL_ 1370 OBC_ComLostFlt_BMS 0 "Normal" 1 "Abnormal" ;
VAL_ 1370 OBC_ACVoltOverVoltFlt 0 "Normal" 1 "Abnormal" ;
VAL_ 1370 OBC_ACVoltUnderVoltFlt 0 "Normal" 1 "Abnormal" ;
VAL_ 1370 OBC_HVDCOutpOverVoltHwFlt 0 "Normal" 1 "Abnormal" ;
VAL_ 1370 OBC_HVDCOutpUnderVoltFlt 0 "Normal" 1 "Abnormal" ;
VAL_ 1370 OBC_HVDCOutpOverVoltSwFlt 0 "Normal" 1 "Abnormal" ;
VAL_ 1370 OBC_InpCrtOverCrtHwSwFlt 0 "Normal" 1 "Abnormal" ;
VAL_ 1370 OBC_OverTTurnDwnPwrFlt 0 "Normal" 1 "Abnormal" ;
VAL_ 1370 OBC_OverTShutDwnFlt 0 "Normal" 1 "Abnormal" ;
VAL_ 1370 OBC_ExtFlt 0 "No_Fault" 1 "Fault" ;
VAL_ 1370 OBC_IntFlt 0 "Normal" 1 "Abnormal" ;
VAL_ 1370 OBC_ComLostFlt_VCU 0 "Normal" 1 "Abnormal" ;
VAL_ 1370 OBC_ComLostFlt_CCU 0 "Normal" 1 "Abnormal" ;
VAL_ 1370 OBC_12VPwrSplyVoltUnder 0 "Normal" 1 "Abnormal" ;
VAL_ 1370 OBC_12VPwrSplyVoltOver 0 "Normal" 1 "Abnormal" ;
VAL_ 1392 OBC_ACVoltPhase1 65535 "Invalid" ;
VAL_ 1392 OBC_ACVoltPhase2 65535 "Invalid" ;
VAL_ 1392 OBC_ACVoltPhase3 65535 "Invalid" ;
VAL_ 1404 VCU_ActEgyCnsTyp 0 "Default" 1 "Active_(Power_consumption_W)" 2 "Inactive_(energy_consumption_Wh_per_km)" 3 "Invalid" ;
VAL_ 1408 VCU_ActChrgTotAh 65535 "Invalid" ;
VAL_ 1408 VCU_ActDchgTotAh 65535 "Invalid" ;
VAL_ 1408 VCU_PwrBattAvlEgy 65535 "Invalid" ;
VAL_ 1409 EWP_H_Sts 0 "Shutdown" 1 "Run" 2 "Fault" 3 "Idle_run" ;
VAL_ 1409 EWP_B_Sts 0 "Shutdown" 1 "Run" 2 "Fault" 3 "Idle_run" ;
VAL_ 1409 EWP_FD_Sts 0 "Shutdown" 1 "Run" 2 "Fault" 3 "Idle_run" ;
VAL_ 1409 EWP_RD_Sts 0 "Shutdown" 1 "Run" 2 "Fault" 3 "Idle_run" ;
VAL_ 1409 ECC_ThreeWtrVlvSts 0 "Normal" 1 "Fault" ;
VAL_ 1409 ECC_AvtvGrilleSts 0 "Normal" 1 "Fault" ;
VAL_ 1409 ECC_CoolgFanSts 0 "Shutdown" 1 "Run" 2 "Fault" 3 "Reserved" ;
VAL_ 1409 ECC_ParticleSnsrCrtSts 0 "Standby_Standby" 1 "Running_Working" 2 "Complete_air_test" 3 "Invalid" ;
VAL_ 1409 ECC_ParticleSnsrFltSts 0 "Normal" 1 "Abnormal" ;
VAL_ 1410 ECC_InsdT 255 "Invalid" ;
VAL_ 1410 ECC_RemPwrCnsEstim 0 "Valid" 1 "Valid" 2 "Valid" 3 "Valid" 4 "Valid" 5 "Valid" 6 "Valid" 7 "Valid" 8 "Valid" 9 "Valid" 10 "Valid" 11 "Valid" 12 "Valid" 13 "Valid" 14 "Valid" 15 "Valid" 16 "Valid" 17 "Valid" 18 "Valid" 19 "Valid" 20 "Valid" 21 "Valid" 22 "Valid" 23 "Valid" 24 "Valid" 25 "Valid" 26 "Valid" 27 "Valid" 28 "Valid" 29 "Valid" 30 "Valid" 31 "Valid" 32 "Valid" 33 "Valid" 34 "Valid" 35 "Valid" 36 "Valid" 37 "Valid" 38 "Valid" 39 "Valid" 40 "Valid" 41 "Valid" 42 "Valid" 43 "Valid" 44 "Valid" 45 "Valid" 46 "Valid" 47 "Valid" 48 "Valid" 49 "Valid" 50 "Valid" 51 "Valid" 52 "Valid" 53 "Valid" 54 "Valid" 55 "Valid" 56 "Valid" 57 "Valid" 58 "Valid" 59 "Valid" 60 "Valid" 61 "Valid" 62 "Valid" 63 "Valid" 64 "Valid" 65 "Valid" 66 "Valid" 67 "Valid" 68 "Valid" 69 "Valid" 70 "Valid" 71 "Valid" 72 "Valid" 73 "Valid" 74 "Valid" 75 "Valid" 76 "Valid" 77 "Valid" 78 "Valid" 79 "Valid" 80 "Valid" 81 "Valid" 82 "Valid" 83 "Valid" 84 "Valid" 85 "Valid" 86 "Valid" 87 "Valid" 88 "Valid" 89 "Valid" 90 "Valid" 91 "Valid" 92 "Valid" 93 "Valid" 94 "Valid" 95 "Valid" 96 "Valid" 97 "Valid" 98 "Valid" 99 "Valid" 100 "Valid" 101 "Valid" 102 "Valid" 103 "Valid" 104 "Valid" 105 "Valid" 106 "Valid" 107 "Valid" 108 "Valid" 109 "Valid" 110 "Valid" 111 "Valid" 112 "Valid" 113 "Valid" 114 "Valid" 115 "Valid" 116 "Valid" 117 "Valid" 118 "Valid" 119 "Valid" 120 "Valid" 121 "Valid" 122 "Valid" 123 "Valid" 124 "Valid" 125 "Valid" 126 "Valid" 127 "Valid" 128 "Valid" 129 "Valid" 130 "Valid" 131 "Valid" 132 "Valid" 133 "Valid" 134 "Valid" 135 "Valid" 136 "Valid" 137 "Valid" 138 "Valid" 139 "Valid" 140 "Valid" 141 "Valid" 142 "Valid" 143 "Valid" 144 "Valid" 145 "Valid" 146 "Valid" 147 "Valid" 148 "Valid" 149 "Valid" 150 "Valid" 151 "Valid" 152 "Valid" 153 "Valid" 154 "Valid" 155 "Valid" 156 "Valid" 157 "Valid" 158 "Valid" 159 "Valid" 160 "Valid" 161 "Valid" 162 "Valid" 163 "Valid" 164 "Valid" 165 "Valid" 166 "Valid" 167 "Valid" 168 "Valid" 169 "Valid" 170 "Valid" 171 "Valid" 172 "Valid" 173 "Valid" 174 "Valid" 175 "Valid" 176 "Valid" 177 "Valid" 178 "Valid" 179 "Valid" 180 "Valid" 181 "Valid" 182 "Valid" 183 "Valid" 184 "Valid" 185 "Valid" 186 "Valid" 187 "Valid" 188 "Valid" 189 "Valid" 190 "Valid" 191 "Valid" 192 "Valid" 193 "Valid" 194 "Valid" 195 "Valid" 196 "Valid" 197 "Valid" 198 "Valid" 199 "Valid" 200 "Valid" 201 "Valid" 202 "Valid" 203 "Valid" 204 "Valid" 205 "Valid" 206 "Valid" 207 "Valid" 208 "Valid" 209 "Valid" 210 "Valid" 211 "Valid" 212 "Valid" 213 "Valid" 214 "Valid" 215 "Valid" 216 "Valid" 217 "Valid" 218 "Valid" 219 "Valid" 220 "Valid" 221 "Valid" 222 "Valid" 223 "Valid" 224 "Valid" 225 "Valid" 226 "Valid" 227 "Valid" 228 "Valid" 229 "Valid" 230 "Valid" 231 "Valid" 232 "Valid" 233 "Valid" 234 "Valid" 235 "Valid" 236 "Valid" 237 "Valid" 238 "Valid" 239 "Valid" 240 "Valid" 241 "Valid" 242 "Valid" 243 "Valid" 244 "Valid" 245 "Valid" 246 "Valid" 247 "Valid" 248 "Valid" 249 "Valid" 250 "Valid" 251 "Valid" 252 "Valid" 253 "Valid" 254 "Valid" 255 "Invalid" ;
VAL_ 1410 ECC_RemTSetSts 0 "Inactive" 1 "Low" 2 "Low" 3 "Low" 4 "Low" 5 "Low" 6 "Low" 7 "Low" 8 "Low" 9 "Low" 10 "Low" 11 "Low" 12 "Low" 13 "Low" 14 "Low" 15 "Low" 16 "Low" 17 "Low" 18 "Low" 19 "Low" 20 "Low" 21 "Low" 22 "Low" 23 "Low" 24 "Low" 25 "Low" 26 "Low" 27 "Low" 28 "Low" 29 "Low" 30 "Low" 31 "Low" 32 "Low" 33 "Low" 34 "Low" 35 "Low" 36 "18??C" 37 "18.5??C" 38 "19??C" 39 "19.5??C" 40 "20??C" 41 "20.5??C" 42 "21??C" 43 "21.5??C" 44 "22??C" 45 "22.5??C" 46 "23??C" 47 "23.5??C" 48 "24??C" 49 "24.5??C" 50 "25??C" 51 "25.5??C" 52 "26??C" 53 "26.5??C" 54 "27??C" 55 "27.5??C" 56 "28??C" 57 "28.5??C" 58 "29??C" 59 "29.5??C" 60 "30??C" 61 "30.5??C" 62 "31??C" 63 "31.5??C" 64 "32??C" 65 "High" 66 "High" 67 "High" 68 "High" 69 "High" 70 "High" 71 "High" 72 "High" 73 "High" 74 "High" 75 "High" 76 "High" 77 "High" 78 "High" 79 "High" 80 "High" 81 "High" 82 "High" 83 "High" 84 "High" 85 "High" 86 "High" 87 "High" 88 "High" 89 "High" 90 "High" 91 "High" 92 "High" 93 "High" 94 "High" 95 "High" 96 "High" 97 "High" 98 "High" 99 "High" 100 "High" 101 "High" 102 "High" 103 "High" 104 "High" 105 "High" 106 "High" 107 "High" 108 "High" 109 "High" 110 "High" 111 "High" 112 "High" 113 "High" 114 "High" 115 "High" 116 "High" 117 "High" 118 "High" 119 "High" 120 "High" 121 "High" 122 "High" 123 "High" 124 "High" 125 "High" 126 "High" 127 "High" 128 "High" 129 "High" 130 "High" 131 "High" 132 "High" 133 "High" 134 "High" 135 "High" 136 "High" 137 "High" 138 "High" 139 "High" 140 "High" 141 "High" 142 "High" 143 "High" 144 "High" 145 "High" 146 "High" 147 "High" 148 "High" 149 "High" 150 "High" 151 "High" 152 "High" 153 "High" 154 "High" 155 "High" 156 "High" 157 "High" 158 "High" 159 "High" 160 "High" 161 "High" 162 "High" 163 "High" 164 "High" 165 "High" 166 "High" 167 "High" 168 "High" 169 "High" 170 "High" 171 "High" 172 "High" 173 "High" 174 "High" 175 "High" 176 "High" 177 "High" 178 "High" 179 "High" 180 "High" 181 "High" 182 "High" 183 "High" 184 "High" 185 "High" 186 "High" 187 "High" 188 "High" 189 "High" 190 "High" 191 "High" 192 "High" 193 "High" 194 "High" 195 "High" 196 "High" 197 "High" 198 "High" 199 "High" 200 "High" 201 "High" 202 "High" 203 "High" 204 "High" 205 "High" 206 "High" 207 "High" 208 "High" 209 "High" 210 "High" 211 "High" 212 "High" 213 "High" 214 "High" 215 "High" 216 "High" 217 "High" 218 "High" 219 "High" 220 "High" 221 "High" 222 "High" 223 "High" 224 "High" 225 "High" 226 "High" 227 "High" 228 "High" 229 "High" 230 "High" 231 "High" 232 "High" 233 "High" 234 "High" 235 "High" 236 "High" 237 "High" 238 "High" 239 "High" 240 "High" 241 "High" 242 "High" 243 "High" 244 "High" 245 "High" 246 "High" 247 "High" 248 "High" 249 "High" 250 "High" 251 "High" 252 "High" 253 "High" 254 "High" 255 "Invalid" ;
VAL_ 1410 ECC_RemDefrstSts 0 "Off" 1 "On" ;
VAL_ 1410 ECC_BattFldLvlSnsrLamp 0 "Lamp_off" 1 "Lamp_on" 2 "Reserved" 3 "Invalid" ;
VAL_ 1412 ECC_TarPwrReq_WTC_H 65535 "Invalid" ;
VAL_ 1412 ECC_TarPwrReq_WTC_B 65535 "Invalid" ;
VAL_ 1412 ECC_DchaT 255 "Invalid" ;
VAL_ 1412 ECC_FourWayVlvOutlT 255 "Invalid" ;
VAL_ 1412 ECC_TarGearReq_WTC_B 0 "Gear_0" 1 "Gear_1" 2 "Gear_2" 3 "Gear_3" 4 "Gear_4" 5 "Gear_5" 6 "Gear_6" 7 "Reserved" 8 "Reserved" 9 "Reserved" 10 "Reserved" 11 "Reserved" 12 "Reserved" 13 "Reserved" 14 "Reserved" 15 "Reserved" ;
VAL_ 1412 ECC_TarGearReq_WTC_H 0 "Gear_0" 1 "Gear_1" 2 "Gear_2" 3 "Gear_3" 4 "Gear_4" 5 "Gear_5" 6 "Gear_6" 7 "Reserved" 8 "Reserved" 9 "Reserved" 10 "Reserved" 11 "Reserved" 12 "Reserved" 13 "Reserved" 14 "Reserved" 15 "Reserved" ;
VAL_ 1415 Rotator_ECUSts 0 "Idle" 1 "Rotating_clockwise" 2 "Invalid_command" 3 "Stuck" 4 "Rotating_counterclockwise" ;
VAL_ 1415 Rotator_PosVld 0 "invalid" 1 "valid" ;
VAL_ 1415 Rotator_Pos_rotator 0 "init" 1 "0_degree" 2 "+90_degree" 7 "Invalid" ;
VAL_ 1415 Rotator_OpticSnsrFlt 0 "None" 1 "Fail_High" 2 "Fail_Low" 3 "Invalid" ;
VAL_ 1415 Rotator_HallSnsrFlt 0 "None" 1 "Fail_High" 2 "Fail_Low" 3 "Invalid" ;
VAL_ 1415 Rotator_RotationReqSteerClmn 0 "no_rotation" 1 "Rotation_request" ;
VAL_ 1436 VCU_LowMilg_Warn 0 "above_50_miles-no_warning" 1 "21-50_miles_warning_(acoustic_and_amber_alert)" 2 "2-20_miles_warning_(acoustic_and_red_alert)" ;
VAL_ 1436 VCU_LowMilgRemAlrm 0 "Init" 1 "Soft_warning" 2 "Strict_alarm" 3 "Invalid" ;
VAL_ 1440 VCU_DCChrgCrtCmd 65535 "Invalid" ;
VAL_ 1444 VCU_HVEM_PwrCoorrPrio 0 "Init" 1 "PDF1" 2 "PDF2" 3 "PDF3" ;
VAL_ 1476 TBOX_OTA_ownCondchk 0 "No_Request" 1 "Request" 3 "Invalid" ;
VAL_ 1476 TBOX_TerminalRemWakeupSig 0 "Not_waken_up" 1 "Waken_up" ;
VAL_ 1476 TBOX_RemSCModReq 0 "No_remote_control" 1 "Turn_on_remote_charging" 2 "Turn_off_remote_charging" 3 "Reserved" ;
VAL_ 1476 TBOX_RemPwrBattOpenHeatgReq 0 "No_remote_control" 1 "Turn_on_remote_power_battery_heating_mode" 2 "Turn_off_remote_power_battery_heating_mode" 3 "Reserved" ;
VAL_ 1476 TBOX_RemPwrBattResvHeatgReq 0 "No_request" 1 "Request" ;
VAL_ 1476 TBOX_RemInsdInfoDispEna 0 "Disable" 1 "Enable" ;
VAL_ 1476 TBOX_RemECCDefrstModReq 0 "No_remote_control" 1 "Turn_on_remote_AC_defrost_mode" 2 "Turn_off_remote_AC_defrost_mode" 3 "Reserved" ;
VAL_ 1476 TBOX_RemECCResvDefrstReq 0 "No_remote_control" 1 "Reserve_remote_AC_deforst_mode" ;
VAL_ 1476 TBOX_RemECCSetT 0 "Inactive" 1 "Low" 2 "Low" 3 "Low" 4 "Low" 5 "Low" 6 "Low" 7 "Low" 8 "Low" 9 "Low" 10 "Low" 11 "Low" 12 "Low" 13 "Low" 14 "Low" 15 "Low" 16 "Low" 17 "Low" 18 "Low" 19 "Low" 20 "Low" 21 "Low" 22 "Low" 23 "Low" 24 "Low" 25 "Low" 26 "Low" 27 "Low" 28 "Low" 29 "Low" 30 "Low" 31 "Low" 32 "Low" 33 "Low" 34 "Low" 35 "Low" 36 "18¡ãC" 37 "18.5¡ãC" 38 "19¡ãC" 39 "19.5¡ãC" 40 "20¡ãC" 41 "20.5¡ãC" 42 "21¡ãC" 43 "21.5¡ãC" 44 "22¡ãC" 45 "22.5¡ãC" 46 "23¡ãC" 47 "23.5¡ãC" 48 "24¡ãC" 49 "24.5¡ãC" 50 "25¡ãC" 51 "25.5¡ãC" 52 "26¡ãC" 53 "26.5¡ãC" 54 "27¡ãC" 55 "27.5¡ãC" 56 "28¡ãC" 57 "28.5¡ãC" 58 "29¡ãC" 59 "29.5¡ãC" 60 "30¡ãC" 61 "30.5¡ãC" 62 "31¡ãC" 63 "31.5¡ãC" 64 "32¡ãC" 65 "High" 66 "High" 67 "High" 68 "High" 69 "High" 70 "High" 71 "High" 72 "High" 73 "High" 74 "High" 75 "High" 76 "High" 77 "High" 78 "High" 79 "High" 80 "High" 81 "High" 82 "High" 83 "High" 84 "High" 85 "High" 86 "High" 87 "High" 88 "High" 89 "High" 90 "High" 91 "High" 92 "High" 93 "High" 94 "High" 95 "High" 96 "High" 97 "High" 98 "High" 99 "High" 100 "High" 101 "High" 102 "High" 103 "High" 104 "High" 105 "High" 106 "High" 107 "High" 108 "High" 109 "High" 110 "High" 111 "High" 112 "High" 113 "High" 114 "High" 115 "High" 116 "High" 117 "High" 118 "High" 119 "High" 120 "High" 121 "High" 122 "High" 123 "High" 124 "High" 125 "High" 126 "High" 127 "High" 128 "High" 129 "High" 130 "High" 131 "High" 132 "High" 133 "High" 134 "High" 135 "High" 136 "High" 137 "High" 138 "High" 139 "High" 140 "High" 141 "High" 142 "High" 143 "High" 144 "High" 145 "High" 146 "High" 147 "High" 148 "High" 149 "High" 150 "High" 151 "High" 152 "High" 153 "High" 154 "High" 155 "High" 156 "High" 157 "High" 158 "High" 159 "High" 160 "High" 161 "High" 162 "High" 163 "High" 164 "High" 165 "High" 166 "High" 167 "High" 168 "High" 169 "High" 170 "High" 171 "High" 172 "High" 173 "High" 174 "High" 175 "High" 176 "High" 177 "High" 178 "High" 179 "High" 180 "High" 181 "High" 182 "High" 183 "High" 184 "High" 185 "High" 186 "High" 187 "High" 188 "High" 189 "High" 190 "High" 191 "High" 192 "High" 193 "High" 194 "High" 195 "High" 196 "High" 197 "High" 198 "High" 199 "High" 200 "High" 201 "High" 202 "High" 203 "High" 204 "High" 205 "High" 206 "High" 207 "High" 208 "High" 209 "High" 210 "High" 211 "High" 212 "High" 213 "High" 214 "High" 215 "High" 216 "High" 217 "High" 218 "High" 219 "High" 220 "High" 221 "High" 222 "High" 223 "High" 224 "High" 225 "High" 226 "High" 227 "High" 228 "High" 229 "High" 230 "High" 231 "High" 232 "High" 233 "High" 234 "High" 235 "High" 236 "High" 237 "High" 238 "High" 239 "High" 240 "High" 241 "High" 242 "High" 243 "High" 244 "High" 245 "High" 246 "High" 247 "High" 248 "High" 249 "High" 250 "High" 251 "High" 252 "High" 253 "High" 254 "High" 255 "Invalid" ;
VAL_ 1476 TBOX_RemResvECCSetT 0 "Inactive" 1 "Low" 2 "Low" 3 "Low" 4 "Low" 5 "Low" 6 "Low" 7 "Low" 8 "Low" 9 "Low" 10 "Low" 11 "Low" 12 "Low" 13 "Low" 14 "Low" 15 "Low" 16 "Low" 17 "Low" 18 "Low" 19 "Low" 20 "Low" 21 "Low" 22 "Low" 23 "Low" 24 "Low" 25 "Low" 26 "Low" 27 "Low" 28 "Low" 29 "Low" 30 "Low" 31 "Low" 32 "Low" 33 "Low" 34 "Low" 35 "Low" 36 "18¡ãC" 37 "18.5¡ãC" 38 "19¡ãC" 39 "19.5¡ãC" 40 "20¡ãC" 41 "20.5¡ãC" 42 "21¡ãC" 43 "21.5¡ãC" 44 "22¡ãC" 45 "22.5¡ãC" 46 "23¡ãC" 47 "23.5¡ãC" 48 "24¡ãC" 49 "24.5¡ãC" 50 "25¡ãC" 51 "25.5¡ãC" 52 "26¡ãC" 53 "26.5¡ãC" 54 "27¡ãC" 55 "27.5¡ãC" 56 "28¡ãC" 57 "28.5¡ãC" 58 "29¡ãC" 59 "29.5¡ãC" 60 "30¡ãC" 61 "30.5¡ãC" 62 "31¡ãC" 63 "31.5¡ãC" 64 "32¡ãC" 65 "High" 66 "High" 67 "High" 68 "High" 69 "High" 70 "High" 71 "High" 72 "High" 73 "High" 74 "High" 75 "High" 76 "High" 77 "High" 78 "High" 79 "High" 80 "High" 81 "High" 82 "High" 83 "High" 84 "High" 85 "High" 86 "High" 87 "High" 88 "High" 89 "High" 90 "High" 91 "High" 92 "High" 93 "High" 94 "High" 95 "High" 96 "High" 97 "High" 98 "High" 99 "High" 100 "High" 101 "High" 102 "High" 103 "High" 104 "High" 105 "High" 106 "High" 107 "High" 108 "High" 109 "High" 110 "High" 111 "High" 112 "High" 113 "High" 114 "High" 115 "High" 116 "High" 117 "High" 118 "High" 119 "High" 120 "High" 121 "High" 122 "High" 123 "High" 124 "High" 125 "High" 126 "High" 127 "High" 128 "High" 129 "High" 130 "High" 131 "High" 132 "High" 133 "High" 134 "High" 135 "High" 136 "High" 137 "High" 138 "High" 139 "High" 140 "High" 141 "High" 142 "High" 143 "High" 144 "High" 145 "High" 146 "High" 147 "High" 148 "High" 149 "High" 150 "High" 151 "High" 152 "High" 153 "High" 154 "High" 155 "High" 156 "High" 157 "High" 158 "High" 159 "High" 160 "High" 161 "High" 162 "High" 163 "High" 164 "High" 165 "High" 166 "High" 167 "High" 168 "High" 169 "High" 170 "High" 171 "High" 172 "High" 173 "High" 174 "High" 175 "High" 176 "High" 177 "High" 178 "High" 179 "High" 180 "High" 181 "High" 182 "High" 183 "High" 184 "High" 185 "High" 186 "High" 187 "High" 188 "High" 189 "High" 190 "High" 191 "High" 192 "High" 193 "High" 194 "High" 195 "High" 196 "High" 197 "High" 198 "High" 199 "High" 200 "High" 201 "High" 202 "High" 203 "High" 204 "High" 205 "High" 206 "High" 207 "High" 208 "High" 209 "High" 210 "High" 211 "High" 212 "High" 213 "High" 214 "High" 215 "High" 216 "High" 217 "High" 218 "High" 219 "High" 220 "High" 221 "High" 222 "High" 223 "High" 224 "High" 225 "High" 226 "High" 227 "High" 228 "High" 229 "High" 230 "High" 231 "High" 232 "High" 233 "High" 234 "High" 235 "High" 236 "High" 237 "High" 238 "High" 239 "High" 240 "High" 241 "High" 242 "High" 243 "High" 244 "High" 245 "High" 246 "High" 247 "High" 248 "High" 249 "High" 250 "High" 251 "High" 252 "High" 253 "High" 254 "High" 255 "Invalid" ;
VAL_ 1476 TBOX_4GSigIND 0 "No_signal" 1 "Weak" 2 "Moderate" 3 "Strong" ;
VAL_ 1476 TBOX_Conn_Typ 0 "Not_Connected" 1 "3G_or_4G_LTE_CAT-1_and_below_(downllink_less_than_10_Mbps)" 2 "4G_LTE_CAT-2_and_above_(downlink_greater_than_10_Mbps)" 3 "WiFi_2,4_GHz" 4 "WiFi_5_GHz" 5 "Reserved_for_5G_FR1_(Less_than_1_Gbps)" 6 "Reserved_for_5G_FR2_(Greater_than_1_Gbps)" 7 "Reserved_for_5G_mmWave" ;
VAL_ 1476 TBOX_TSPNotConn 0 "Normal" 1 "fault" ;
VAL_ 1476 TBOX_EHUNotCONN 0 "Normal" 1 "fault" ;
VAL_ 1476 TBOX_WIFIError 0 "Normal" 1 "fault" ;
VAL_ 1476 TBOX_InnerBattError 0 "Normal" 1 "fault" ;
VAL_ 1476 TBOX_VoltLow 0 "Normal" 1 "fault" ;
VAL_ 1476 TBOX_VoltHigh 0 "Normal" 1 "fault" ;
VAL_ 1476 TBOX_4GLoss 0 "Normal" 1 "fault" ;
VAL_ 1476 TBOX_RemSWH_Req 0 "No_request" 1 "SWH_ON" 2 "Reserved" 3 "Invalid" ;
VAL_ 1476 TBOX_OTAInhbReq 0 "No_Inhibit_request" 1 "Inhibit_Request" 2 "Reserved" 3 "Invalid" ;
VAL_ 1536 ECC_ETXVSts 0 "Not_triggered" 1 "Triggered" ;
VAL_ 1536 ECC_FourWayVlvSts 0 "Cooling" 1 "Heating" 2 "Reserved" 3 "Reserved" ;
VAL_ 1536 ECC_HPLinePSts 0 "Normal" 1 "Too_high" 2 "Too_low" 3 "Reserved" ;
VAL_ 1536 ECC_LeTHybThrPercReqSts 0 "Gear_0_request" 1 "Gear_1_request" 2 "Gear_2_request" 3 "Gear_3_request" 4 "Gear_4_request" 5 "Gear_5_request" 6 "Reserved" 7 "Reserved" ;
VAL_ 1536 ECC_RiTHybThrPercReqSts 0 "Gear_0_request" 1 "Gear_1_request" 2 "Gear_2_request" 3 "Gear_3_request" 4 "Gear_4_request" 5 "Gear_5_request" 6 "Reserved" 7 "Reserved" ;
VAL_ 1552 ICC_UsrSetChrgRmnMilg 255 "Invalid" ;
VAL_ 1552 ICC_EPedlSts 0 "OnePedalDrive" 1 "Roll" 2 "Creep" 3 "Invalid" ;
VAL_ 1552 ICC_AccelMod 0 "Low" 1 "Medium" 2 "High" 3 "Invalid" ;
VAL_ 1552 ICC_BoostMode 0 "Default" 1 "Active_(On)" 2 "Inactive_(Off)" 3 "Reserved" ;
VAL_ 1552 ICC_EgyCnseClrFlg 0 "flag_bit_not_reached" 1 "average_energy_consumption_zeroed" 2 "Cumulative_average_energy_consumption_zeroed" 3 "Average_energy_consumption_&_cumulative_average_energy_consumption_zeroed" ;
VAL_ 1552 ICC_UsrSetDchaEndDrvgMilg 1023 "Invalid" ;
VAL_ 1552 ICC_VehiMod 0 "Default_Mode" 1 "Mode1" 2 "Mode2" 3 "Mode3" 4 "Mode4" 5 "Mode5" 6 "Mode6" 7 "Mode7" 8 "Mode8" 9 "Mode9" 10 "Mode10" 11 "Mode11" 12 "Mode12" 13 "Mode13" 14 "Mode14" 15 "Mode15" ;
VAL_ 1552 ICC_EgyCnseStcClrFlg 0 "flag_bit_not_reached" 1 "Charging_interface_zeroed" 2 "Non-charging_interface_zeroed" 3 "Reserved" ;
VAL_ 1552 ICC_PollingFctOpenSts 0 "Default" 1 "Active" 2 "Inactive" 3 "Reserved" ;
VAL_ 1552 ICC_KickFctOpenSts 0 "Default" 1 "Active" 2 "Inactive" 3 "Reserved" ;
VAL_ 1552 ICC_UsrSetChrgGunAntithft 0 "Anti-theft" 1 "No_anti-theft" ;
VAL_ 1552 ICC_ChrgInsulFctReq 0 "No_action" 1 "On" 2 "Off" 3 "Reserved" ;
VAL_ 1552 ICC_StopChrgBtn 0 "No_action" 1 "Stop_charging" ;
VAL_ 1552 ICC_DrvModSig 0 "Eco" 1 "Normal" 2 "Sport" 3 "Custom" 4 "Snow" 5 "Offroad" 6 "Valet" 7 "Invalid" ;
VAL_ 1552 ICC_SetACChrgLmtCrt 0 "Invalid_(treat_same_as_0x3)" 1 "Lvl1_(25%_of_MaxAllowable)" 2 "Lvl2_(50%_of_MaxAllowable)" 3 "Lvl3_(100%_of_MaxAllowable)" ;
VAL_ 1552 ICC_SetTrvlMod 0 "Initial_value" 1 "Daily_commuter_mode" 2 "Long-distance_travel_mode" 3 "Reserved" ;
VAL_ 1552 ICC_RegenLvl 0 "Off" 1 "Normal" 2 "High" 3 "Invalid" ;
VAL_ 1552 ICC_SetChrgEndSOC 127 "Invalid" ;
VAL_ 1552 ICC_StartChrgBtn 0 "No_action" 1 "Start_charging" ;
VAL_ 1558 VCU_PwrAntitheftAuthentLrngSts 0 "Not_learned" 1 "Learned" ;
VAL_ 1558 VCU_PwrAntitheftErrTyp 0 "Normal" 1 "Vrigin" 2 "No_Respond" 3 "Wrong_Secret_Key" ;
VAL_ 1558 VCU_FreestartMod 0 "Freestart_mode" 1 "Non-freestart_mode" ;
VAL_ 1559 VCU_E2PROMAPICallFlt 0 "Normal" 1 "Alarm" ;
VAL_ 1559 VCU_E2PROMReadFlt 0 "Normal" 1 "Alarm" ;
VAL_ 1559 VCU_E2PROMWrFlt 0 "Normal" 1 "Alarm" ;
VAL_ 1559 VCU_TMonFlt 0 "Normal" 1 "Alarm" ;
VAL_ 1559 VCU_EVCANBusFlt 0 "Normal" 1 "Alarm" ;
VAL_ 1559 VCU_CCANBusFlt 0 "Normal" 1 "Alarm" ;
VAL_ 1559 VCU_BREAKCANBusFlt 0 "Normal" 1 "Alarm" ;
VAL_ 1559 VCU_ATIC232ComFlt 0 "Normal" 1 "Alarm" ;
VAL_ 1559 VCU_ATIC280ComFlt 0 "Normal" 1 "Alarm" ;
VAL_ 1559 VCU_ATIC239LowSideOutpComFlt 0 "Normal" 1 "Alarm" ;
VAL_ 1559 VCU_ATIC239VotSplyMngComFlt 0 "Normal" 1 "Alarm" ;
VAL_ 1559 VCU_ATIC239UnderOverVotFlt 0 "Normal" 1 "Alarm" ;
VAL_ 1559 VCU_ADCnvrFlt 0 "Normal" 1 "Alarm" ;
VAL_ 1559 VCU_SftyFctMonrFlt 0 "Normal" 1 "Alarm" ;
VAL_ 1559 VCU_SftyFctMonrMemFlt 0 "Normal" 1 "Alarm" ;
VAL_ 1559 VCU_LVbattCtrlSigOpenFlt 0 "Normal" 1 "Alarm" ;
VAL_ 1559 VCU_LVbattCtrlSigSTBFlt 0 "Normal" 1 "Alarm" ;
VAL_ 1559 VCU_LVbattCtrlSigSTGFlt 0 "Normal" 1 "Alarm" ;
VAL_ 1559 VCU_BMSWakeUpSigOpenFlt 0 "Normal" 1 "Alarm" ;
VAL_ 1559 VCU_BMSWakeUpSigSTBFlt 0 "Normal" 1 "Alarm" ;
VAL_ 1559 VCU_BMSWakeUpSigSTGFlt 0 "Normal" 1 "Alarm" ;
VAL_ 1559 VCU_PDUWakeUpSigSTBFlt 0 "Normal" 1 "Alarm" ;
VAL_ 1559 VCU_PDUWakeUpSigOpenFlt 0 "Normal" 1 "Alarm" ;
VAL_ 1559 VCU_PDUWakeUpSigSTGFlt 0 "Normal" 1 "Alarm" ;
VAL_ 1559 VCU_CCUCMUWakeUpSigOpenFlt 0 "Normal" 1 "Alarm" ;
VAL_ 1559 VCU_CCUCMUWakeUpSigSTBFlt 0 "Normal" 1 "Alarm" ;
VAL_ 1559 VCU_CCUCMUWakeUpSigSTGFlt 0 "Normal" 1 "Alarm" ;
VAL_ 1559 VCU_MCUWakeUpSigOpenFlt 0 "Normal" 1 "Alarm" ;
VAL_ 1559 VCU_MCUWakeUpSigSTBFlt 0 "Normal" 1 "Alarm" ;
VAL_ 1559 VCU_MCUWakeUpSigSTGFlt 0 "Normal" 1 "Alarm" ;
VAL_ 1559 VCU_ComLostFlt_CCU 0 "Normal" 1 "Alarm" ;
VAL_ 1562 TBOX_RemDTCDmd 0 "No_demand" 1 "Demand" ;
VAL_ 1562 TBOX_DrvRngCldVld 0 "Initializing" 1 "Valid" 2 "Invalid" 3 "Reserved" ;
VAL_ 1583 TBOX_CrtTi_Day 0 "Day1" 30 "Day31" ;
VAL_ 1583 TBOX_CrtTi_Hr 0 "Hour_0" 23 "Hour_23" ;
VAL_ 1583 TBOX_CrtTi_Mins 0 "Mintue_0" 59 "Mintue_59" ;
VAL_ 1583 TBOX_CrtTi_Yr 0 "Year_2015" 255 "Year2270" ;
VAL_ 1583 TBOX_CrtTi_Mth 0 "January" 11 "December" ;
VAL_ 1583 TBOX_CrtTi_Sec 0 "Second_0" 59 "Second_59" ;
VAL_ 1584 VCU_CellTotVolt 65535 "Invalid" ;
VAL_ 1588 VCU_ACChrgShttrSts 0 "Off" 1 "On" ;
VAL_ 1588 VCU_DCChrgShttrSts 0 "Off" 1 "On" ;
VAL_ 1588 VCU_SCPwrSplyEquipFactry 0 "Initial_value" 1 "Non-BJEV_power_supply" 2 "BJEV_portable_charger_as_per_the_original_national_standards" 3 "BJEV_charging_equipment_as_per_the_new_national_standards" 4 "Reserved" 5 "Reserved" 6 "Reserved" 7 "Reserved" ;
VAL_ 1594 BMS_Splr 0 "Other" 1 "Planet" 2 "Coslight" 3 "SumSung" 4 "Zhuoneng" 5 "South_Korea_SK" 6 "Gotion" 7 "Tenpower" 8 "Farasis_Energy" 9 "BJEV" 10 "Octillion" 11 "Microvast" 12 "Reserved" 13 "CATL" 14 "Reserved" 15 "Reserved" ;
VAL_ 1594 BMS_PwrBattTyp 0 "Other" 1 "Ni-MH" 2 "LFP" 3 "LMO" 4 "Li-Sulfur" 5 "NCM" 6 "Sodium-solphur" 7 "Lithium_titanate" 8 "Lead-acid" 9 "Metal-air" 10 "Reserved" 11 "Reserved" 12 "Reserved" 13 "Reserved" 14 "Reserved" 15 "Reserved" ;
VAL_ 1604 ECC_ReMotOutlT 255 "Invalid" ;
VAL_ 1604 ECC_CoolgDfct 0 "Active" 1 "Inactive" ;
VAL_ 1604 ECC_CooltHomSts 0 "not_homogenized" 1 "homogenized" ;
VAL_ 1604 ECC_PDUInlT 255 "Invalid" ;
VAL_ 1604 ECC_FrntMotOutlT 255 "Invalid" ;
VAL_ 1604 ECC_MCURInlT 255 "Invalid" ;
VAL_ 1605 ECC_DefrstAirOutlTSnsrFlt 0 "Normal" 1 "Abnormal" ;
VAL_ 1605 ECC_ComLost_EAS 0 "Normal" 1 "Abnormal" ;
VAL_ 1605 ECC_OutdTSnsrFlt 0 "Normal" 1 "Abnormal" ;
VAL_ 1605 ECC_InsdTSnsrFlt 0 "Normal" 1 "Abnormal" ;
VAL_ 1605 ECC_EvaprTSnsrFlt 0 "Normal" 1 "Abnormal" ;
VAL_ 1605 ECC_IntExtCircMotFlt 0 "Normal" 1 "Abnormal" ;
VAL_ 1605 ECC_LeModThrMotFlt 0 "Normal" 1 "Abnormal" ;
VAL_ 1605 ECC_RiModThrMotFlt 0 "Normal" 1 "Abnormal" ;
VAL_ 1605 ECC_CtrlrFlt 0 "Normal" 1 "Abnormal" ;
VAL_ 1605 ECC_PDUInlTSnsrFlt 0 "Normal" 1 "Abnormal" ;
VAL_ 1605 ECC_FrntMotOutlTSnsrFlt 0 "Normal" 1 "Abnormal" ;
VAL_ 1605 ECC_ReMotOutlTSnsrFlt 0 "Normal" 1 "Abnormal" ;
VAL_ 1605 ECC_ComLost_CDS 0 "Normal" 1 "Abnormal" ;
VAL_ 1605 ECC_ComLost_WTC_H 0 "Normal" 1 "Abnormal" ;
VAL_ 1605 ECC_ComLost_WTC_B 0 "Normal" 1 "Abnormal" ;
VAL_ 1605 ECC_HPTSnsrFlt 0 "Normal" 1 "Abnormal" ;
VAL_ 1605 ECC_LPTSnsrFlt 0 "Normal" 1 "Abnormal" ;
VAL_ 1605 ECC_BlowFaceLeAirOutlTSnsrFlt 0 "Normal" 1 "Abnormal" ;
VAL_ 1605 ECC_BlowFaceRiAirOutlTSnsrFlt 0 "Normal" 1 "Abnormal" ;
VAL_ 1605 ECC_ReBlowFaceFootMotFlt 0 "Normal" 1 "Abnormal" ;
VAL_ 1605 ECC_HPSnsrFlt 0 "Normal" 1 "Abnormal" ;
VAL_ 1605 ECC_LPSnsrFlt 0 "Normal" 1 "Abnormal" ;
VAL_ 1605 ECC_HeatPmpHeatgEXVFlt 0 "Normal" 1 "Abnormal" ;
VAL_ 1605 ECC_BattCoolgEXVFlt 0 "Normal" 1 "Abnormal" ;
VAL_ 1605 ECC_BlowFootLeAirOutlTSnsrFlt 0 "Normal" 1 "Abnormal" ;
VAL_ 1605 ECC_BlowFootRiAirOutlTSnsrFlt 0 "Normal" 1 "Abnormal" ;
VAL_ 1605 ECC_LeHybThrMotFlt 0 "Normal" 1 "Abnormal" ;
VAL_ 1605 ECC_RiHybThrMotFlt 0 "Normal" 1 "Abnormal" ;
VAL_ 1605 ECC_MCURInlTSnsrFlt 0 "Normal" 1 "Abnormal" ;
VAL_ 1605 ECC_ComLost_EWP_FD 0 "Normal" 1 "Abnormal" ;
VAL_ 1605 ECC_ComLost_EWP_RD 0 "Normal" 1 "Abnormal" ;
VAL_ 1605 ECC_ComLost_EWP_H 0 "Communication_normal" 1 "Communication_abnormal" ;
VAL_ 1605 ECC_ComLost_EWP_B 0 "Communication_normal" 1 "Communication_abnormal" ;
VAL_ 1605 ECC_ComLost_EXV_B 0 "Communication_normal" 1 "Communication_abnormal" ;
VAL_ 1605 ECC_ComLost_EXV_H 0 "Communication_normal" 1 "Communication_abnormal" ;
VAL_ 1605 ECC_ComLost_CFM 0 "Communication_normal" 1 "Communication_abnormal" ;
VAL_ 1605 ECC_ComLost_AGS 0 "Communication_normal" 1 "Communication_abnormal" ;
VAL_ 1605 ECC_ComLost_CVM 0 "Communication_normal" 1 "Communication_abnormal" ;
VAL_ 1605 ECC_ComLost_MDV 0 "Communication_normal" 1 "Communication_abnormal" ;
